VERSION ""

NS_ :

BS_:
BU_: GW BMS GPEU PCU RPEU PDU EMS TMS RPEU OBC GPEU PDU ReservedID19 ReservedID20 BDC  TMS Tester
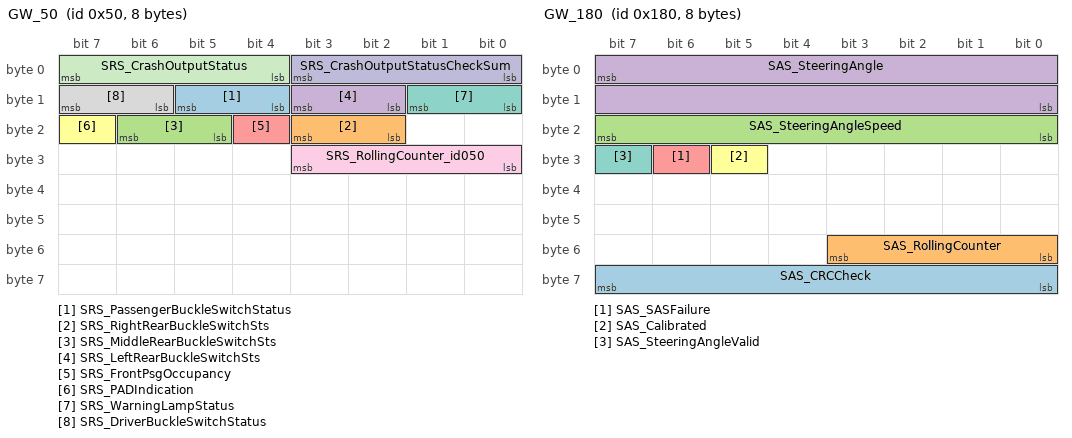
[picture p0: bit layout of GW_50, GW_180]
BO_ 80 GW_50: 8 GW
 SG_ SRS_PassengerBuckleSwitchStatus : 13|2@0+ (1.0000000000,0.0000000000) [0.0000000000|3.0000000000] "" Vector__XXX
 SG_ SRS_RightRearBuckleSwitchSts : 19|2@0+ (1.0000000000,0.0000000000) [0.0000000000|3.0000000000] "" Vector__XXX
 SG_ SRS_MiddleRearBuckleSwitchSts : 22|2@0+ (1.0000000000,0.0000000000) [0.0000000000|3.0000000000] "" Vector__XXX
 SG_ SRS_LeftRearBuckleSwitchSts : 11|2@0+ (1.0000000000,0.0000000000) [0.0000000000|3.0000000000] "" Vector__XXX
 SG_ SRS_FrontPsgOccupancy : 20|1@0+ (1.0000000000,0.0000000000) [0.0000000000|1.0000000000] "" Vector__XXX
 SG_ SRS_PADIndication : 23|1@0+ (1.0000000000,0.0000000000) [0.0000000000|1.0000000000] "" Vector__XXX
 SG_ SRS_WarningLampStatus : 9|2@0+ (1.0000000000,0.0000000000) [0.0000000000|3.0000000000] "" Vector__XXX
 SG_ SRS_DriverBuckleSwitchStatus : 15|2@0+ (1.0000000000,0.0000000000) [0.0000000000|3.0000000000] ""  EMS,PCU,PDCU
 SG_ SRS_RollingCounter_id050 : 27|4@0+ (1.0000000000,0.0000000000) [0.0000000000|15.0000000000] ""  BMS,EMS,PCU,PDCU
 SG_ SRS_CrashOutputStatusCheckSum : 3|4@0+ (1.0000000000,0.0000000000) [0.0000000000|15.0000000000] ""  BMS,EMS,PCU,PDCU
 SG_ SRS_CrashOutputStatus : 7|4@0+ (1.0000000000,0.0000000000) [0.0000000000|15.0000000000] ""  BMS,EMS,PCU,PDCU

BO_ 384 GW_180: 8 GW
 SG_ SAS_CRCCheck : 63|8@0+ (1.0000000000,0.0000000000) [0.0000000000|255.0000000000] ""  PCU,PDCU
 SG_ SAS_RollingCounter : 51|4@0+ (1.0000000000,0.0000000000) [0.0000000000|15.0000000000] ""  PCU,PDCU
 SG_ SAS_SteeringAngleSpeed : 23|8@0+ (4.0000000000,0.0000000000) [0.0000000000|1016.0000000000] "deg/s"  EMS,PCU,PDCU
 SG_ SAS_SteeringAngle : 7|16@0- (0.1000000000,0.0000000000) [-780.0000000000|780.0000000000] "degree"  EMS,PCU,PDCU
 SG_ SAS_SASFailure : 30|1@0+ (1.0000000000,0.0000000000) [0.0000000000|1.0000000000] "" Vector__XXX
 SG_ SAS_Calibrated : 29|1@0+ (1.0000000000,0.0000000000) [0.0000000000|1.0000000000] "" Vector__XXX
 SG_ SAS_SteeringAngleValid : 31|1@0+ (1.0000000000,0.0000000000) [0.0000000000|1.0000000000] ""  EMS,PCU,PDCU

BO_ 400 BMS_190: 32 BMS
 SG_ BMS_PlsHeatTiRem : 203|11@0+ (1.0000000000,0.0000000000) [0.0000000000|2047.0000000000] "second"  GW
 SG_ BMS_BattPlsHeagStsFb : 208|3@0+ (1.0000000000,0.0000000000) [0.0000000000|7.0000000000] ""  GW
 SG_ BMS_MaxChrgU : 221|9@0+ (1.0000000000,0.0000000000) [0.0000000000|500.0000000000] "V"  GW,RPEU
 SG_ BMS_MinDchaIU : 228|9@0+ (1.0000000000,0.0000000000) [0.0000000000|500.0000000000] "V"  GW,RPEU
 SG_ BMS_BcuCycWakeupTimer : 82|11@0+ (1.0000000000,0.0000000000) [0.0000000000|2047.0000000000] "min"  GW
 SG_ BMS_BcuDataUploadReq : 83|1@0+ (1.0000000000,0.0000000000) [0.0000000000|1.0000000000] ""  GW
 SG_ BMS_BattInrHeatMode : 87|4@0+ (1.0000000000,0.0000000000) [0.0000000000|15.0000000000] "min"  GW,TMS,BDC
 SG_ BMS_BattPlsHeatgGearReq : 199|2@0+ (1.0000000000,0.0000000000) [0.0000000000|3.0000000000] ""  PCU,PDCU,GW,RPEU
 SG_ BMS_RollingCounter_190 : 235|4@0+ (1.0000000000,0.0000000000) [0.0000000000|15.0000000000] ""  GW,DPEU,PCU,PDCU,OBC,PDU
 SG_ BMS_CRCCheck_190 : 247|16@0+ (1.0000000000,0.0000000000) [0.0000000000|65535.0000000000] ""  GW,DPEU,PCU,PDCU,OBC,PDU
 SG_ BMS_RlyWlddErr : 180|1@0+ (1.0000000000,0.0000000000) [0.0000000000|1.0000000000] ""  PDCU,PCU,GW
 SG_ BMS_MaxDchaPwrShoT : 135|10@0+ (0.5000000000,0.0000000000) [0.0000000000|500.0000000000] "Kw"  PDCU,PCU,GW,DPEU
 SG_ BMS_MaxDchaIShoT : 147|10@0+ (1.0000000000,0.0000000000) [0.0000000000|1000.0000000000] "A"  PDCU,PCU,GW,DPEU
 SG_ BMS_MaxChrgPwrShoT : 141|10@0+ (0.5000000000,0.0000000000) [0.0000000000|500.0000000000] "Kw"  PDCU,PCU,GW,DPEU
 SG_ BMS_MaxChrgIShoT : 153|10@0+ (1.0000000000,0.0000000000) [0.0000000000|1000.0000000000] "A"  PDCU,PCU,GW,DPEU
 SG_ BMS_BattUSwitch : 175|9@0+ (1.0000000000,0.0000000000) [0.0000000000|500.0000000000] "V"  PDCU,PCU,GW
 SG_ BMS_BattUCmdLoc : 182|2@0+ (1.0000000000,0.0000000000) [0.0000000000|3.0000000000] ""  PDCU,PCU,GW
 SG_ BMS_BcuSngPackModSts : 71|1@0+ (1.0000000000,0.0000000000) [0.0000000000|1.0000000000] ""  PDCU,PCU,GW
 SG_ BMS_SOC : 28|10@0+ (0.1000000000,0.0000000000) [0.0000000000|100.0000000000] "%"  PDCU,PCU,GW,TMS,BDC
 SG_ BMS_PwrUpAllw : 42|1@0+ (1.0000000000,0.0000000000) [0.0000000000|1.0000000000] ""  PDCU,PCU,GW
 SG_ BMS_OperMod : 47|3@0+ (1.0000000000,0.0000000000) [0.0000000000|7.0000000000] ""  PDCU,PCU,GW,DPEU
 SG_ BMS_OBCOperModReq : 44|2@0+ (1.0000000000,0.0000000000) [0.0000000000|3.0000000000] ""  PDCU,PCU,GW,OBC,PDU
 SG_ BMS_InsulationSts : 33|2@0+ (1.0000000000,0.0000000000) [0.0000000000|3.0000000000] ""  PDCU,PCU,GW
 SG_ BMS_HVILSts : 41|1@0+ (1.0000000000,0.0000000000) [0.0000000000|1.0000000000] ""  PDCU,PCU,GW
 SG_ BMS_HeatSftySts : 34|1@0+ (1.0000000000,0.0000000000) [0.0000000000|1.0000000000] ""  PDCU,PCU,GW,TMS,BDC
 SG_ BMS_FltRnk : 55|4@0+ (1.0000000000,0.0000000000) [0.0000000000|8.0000000000] ""  PDCU,PCU,GW
 SG_ BMS_CrashSts : 40|1@0+ (1.0000000000,0.0000000000) [0.0000000000|1.0000000000] ""  PDCU,PCU,GW
 SG_ BMS_BattU : 7|13@0+ (0.1000000000,0.0000000000) [0.0000000000|500.0000000000] "V"  PDCU,PCU,DPEU,GPEU,RPEU,GW
 SG_ BMS_BattI : 10|14@0+ (0.1000000000,-600.0000000000) [-600.0000000000|1000.0000000000] "A"  PDCU,PCU,DPEU,GPEU,RPEU,GW,TMS,BDC

BO_ 308 GPEU_134: 64 GPEU
 SG_ GM_MotorStart : 239|1@0+ (1.0000000000,0.0000000000) [0.0000000000|1.0000000000] ""  GPEU,GW
 SG_ GM_KeyOn : 238|1@0+ (1.0000000000,0.0000000000) [0.0000000000|1.0000000000] ""  GPEU,GW
 SG_ GM_ReolverSingalVp : 423|8@0+ (0.0200000000,0.0000000000) [0.0000000000|5.1000000000] ""  DPEU,GPEU,GW
 SG_ GM_IqFeedBack : 415|8@0+ (0.0200000000,-2.4000000000) [-2.4000000000|2.4000000000] ""  DPEU,GPEU,GW
 SG_ GM_IdFeedBack : 407|8@0+ (0.0200000000,-2.4000000000) [-2.4000000000|2.4000000000] ""  DPEU,GPEU,GW
 SG_ GM_IqCmd : 399|8@0+ (0.0200000000,-2.4000000000) [-2.4000000000|2.4000000000] ""  DPEU,GPEU,GW
 SG_ GM_IdCmd : 391|8@0+ (0.0200000000,-2.4000000000) [-2.4000000000|2.4000000000] ""  DPEU,GPEU,GW
 SG_ GM_IvtINTCT : 167|8@0+ (1.0000000000,-40.0000000000) [-40.0000000000|213.0000000000] "DegreeC"  DPEU,GPEU,PCU,PDCU,GW,TMS,BDC
 SG_ GM_IvtwaterReq : 263|8@0+ (0.1000000000,0.0000000000) [0.0000000000|20.0000000000] "L/min"  DPEU,GPEU,GW,TMS,BDC
 SG_ GM_MidSide_DCUUAct : 463|10@0+ (1.0000000000,0.0000000000) [0.0000000000|1000.0000000000] "V"  DPEU,GPEU,PCU,PDCU,GW
 SG_ GM_MotSpdVld : 72|1@0+ (1.0000000000,0.0000000000) [0.0000000000|1.0000000000] ""  DPEU,GPEU,PCU,PDCU,GW,TMS,BDC
 SG_ GM_MotSpd : 71|15@0+ (1.0000000000,-12000.0000000000) [-12000.0000000000|12000.0000000000] "1/min"  DPEU,GPEU,PCU,PDCU,GW,TMS,BDC
 SG_ GM_TorsionalVibrationTqVld : 17|1@0+ (1.0000000000,0.0000000000) [0.0000000000|1.0000000000] ""  DPEU,GPEU,PCU,PDCU,GW
 SG_ GM_TorsionalVibrationTq : 9|8@0+ (1.0000000000,-128.0000000000) [-128.0000000000|127.0000000000] "Nm"  DPEU,GPEU,PCU,PDCU,GW
 SG_ GM_MotTqRealVld : 10|1@0+ (1.0000000000,0.0000000000) [0.0000000000|1.0000000000] ""  DPEU,GPEU,PCU,PDCU,GW,EMS
 SG_ GM_MotTqReal : 7|13@0+ (0.1000000000,-400.0000000000) [-400.0000000000|400.0000000000] "Nm"  DPEU,GPEU,PCU,PDCU,GW,EMS
 SG_ GM_IvtTOver : 293|1@0+ (1.0000000000,0.0000000000) [0.0000000000|1.0000000000] ""  DPEU,GPEU,GW,TMS,BDC
 SG_ GM_OperMdl : 281|4@0+ (1.0000000000,0.0000000000) [0.0000000000|15.0000000000] ""  DPEU,GPEU,PCU,PDCU,GW,TMS,BDC
 SG_ GM_MotTOver : 282|1@0+ (1.0000000000,0.0000000000) [0.0000000000|1.0000000000] ""  DPEU,GPEU,GW,TMS,BDC
 SG_ GM_IvtCooltT : 274|8@0+ (1.0000000000,-40.0000000000) [-40.0000000000|213.0000000000] "DegreeC"  DPEU,GPEU,PCU,PDCU,GW,TMS,BDC
 SG_ GM_MotSts : 153|2@0+ (1.0000000000,0.0000000000) [0.0000000000|3.0000000000] ""  DPEU,GPEU,GW,TMS,BDC
 SG_ GM_MotNr : 155|2@0+ (1.0000000000,0.0000000000) [0.0000000000|3.0000000000] ""  DPEU,GPEU,GW
 SG_ GM_ErrAmnt : 159|4@0+ (1.0000000000,0.0000000000) [0.0000000000|15.0000000000] ""  DPEU,GPEU,GW
 SG_ GM_BattSide_DCUIAct : 205|10@0+ (1.0000000000,-500.0000000000) [-500.0000000000|500.0000000000] "A"  DPEU,GPEU,PCU,PDCU,GW
 SG_ GM_MotwaterReq : 300|8@0+ (0.1000000000,0.0000000000) [0.0000000000|20.0000000000] "L/min"  DPEU,GPEU,GW,TMS,BDC
 SG_ GM_MotOilReq : 292|8@0+ (0.1000000000,0.0000000000) [0.0000000000|20.0000000000] "L/min"  DPEU,GPEU,PCU,PDCU,GW,TMS,BDC
 SG_ GM_FltCode : 237|9@0+ (1.0000000000,0.0000000000) [0.0000000000|500.0000000000] ""  DPEU,GPEU,PCU,PDCU,GW
 SG_ GM_ACIAct : 199|10@0+ (1.0000000000,-400.0000000000) [-400.0000000000|400.0000000000] "Arms"  DPEU,GPEU,GW
 SG_ GM_MotStatorT : 151|8@0+ (1.0000000000,-40.0000000000) [-40.0000000000|213.0000000000] "DegreeC"  DPEU,GPEU,PCU,PDCU,GW,TMS,BDC
 SG_ GM_MotRotorT : 143|8@0+ (1.0000000000,-40.0000000000) [-40.0000000000|213.0000000000] "DegreeC"  DPEU,GPEU,PCU,PDCU,GW,TMS,BDC
 SG_ GM_IvtIGBTMdlT : 135|8@0+ (1.0000000000,-40.0000000000) [-40.0000000000|213.0000000000] "DegreeC"  DPEU,GPEU,PCU,PDCU,GW,TMS,BDC
 SG_ DPEU_RollingCounter_134 : 491|4@0+ (1.0000000000,0.0000000000) [0.0000000000|15.0000000000] ""  DPEU,PCU,PDCU,GW,GPEU,EMS
 SG_ DPEU_CRCCheck_134 : 503|16@0+ (1.0000000000,0.0000000000) [0.0000000000|65535.0000000000] ""  DPEU,PCU,PDCU,GW,GPEU,EMS
 SG_ GM_Resolvercalibrstatus : 327|3@0+ (1.0000000000,0.0000000000) [0.0000000000|7.0000000000] ""  DPEU,GPEU,PCU,PDCU,GW
 SG_ GM_OffsAg : 219|12@0+ (0.0878906250,-180.0000000000) [-180.0000000000|180.0000000000] ""  DPEU,GPEU,PCU,PDCU,GW
 SG_ GM_MinTqShortTerm : 356|9@0+ (1.0000000000,-500.0000000000) [-500.0000000000|0.0000000000] "Nm"  DPEU,GPEU,PCU,PDCU
 SG_ GM_MinTqLongTerm : 349|9@0+ (1.0000000000,-500.0000000000) [-500.0000000000|0.0000000000] "Nm"  DPEU,GPEU,PCU,PDCU
 SG_ GM_MaxTqShortTerm : 342|9@0+ (1.0000000000,0.0000000000) [0.0000000000|500.0000000000] "Nm"  DPEU,GPEU,PCU,PDCU
 SG_ GM_MaxTqLongTerm : 335|9@0+ (1.0000000000,0.0000000000) [0.0000000000|500.0000000000] "Nm"  DPEU,GPEU,PCU,PDCU
 SG_ GM_FltRnk : 322|3@0+ (1.0000000000,0.0000000000) [0.0000000000|4.0000000000] ""  DPEU,GPEU,PCU,PDCU,GW
 SG_ GM_ASCflag : 244|1@0+ (1.0000000000,0.0000000000) [0.0000000000|1.0000000000] ""  DPEU,GPEU,PCU,PDCU,GW
 SG_ GM_MidSide_DCUIAct : 469|10@0+ (1.0000000000,-500.0000000000) [-500.0000000000|500.0000000000] "A"  DPEU,GPEU,GW

BO_ 510 PCU_1FE: 32 PCU
 SG_ PCU_CRCCheck_1FE_2 : 191|8@0+ (1.0000000000,0.0000000000) [0.0000000000|255.0000000000] ""  DPEU,GPEU,PCU,PDCU
 SG_ PCU_RollingCounter_1FE_2 : 179|4@0+ (1.0000000000,0.0000000000) [0.0000000000|15.0000000000] ""  DPEU,GPEU,PCU,PDCU
 SG_ PCU_CRCCheck_1FE_1 : 127|8@0+ (1.0000000000,0.0000000000) [0.0000000000|255.0000000000] ""  PCU,PDCU,DPEU,GPEU
 SG_ PCU_RollingCounter_1FE_1 : 115|4@0+ (1.0000000000,0.0000000000) [0.0000000000|15.0000000000] ""  PCU,PDCU,DPEU,GPEU
 SG_ PCU_CRCCheck_1FE_0 : 63|8@0+ (1.0000000000,0.0000000000) [0.0000000000|255.0000000000] ""  PCU,PDCU,DPEU,GPEU
 SG_ PCU_RollingCounter_1FE_0 : 51|4@0+ (1.0000000000,0.0000000000) [0.0000000000|15.0000000000] ""  PCU,PDCU,DPEU,GPEU
 SG_ PCU_GMCurrentCmd : 19|11@0+ (0.1000000000,-100.0000000000) [-100.0000000000|100.0000000000] "A"  PCU,PDCU,DPEU,GPEU
 SG_ PCU_GMTqRgnIMax : 13|10@0+ (1.0000000000,-500.0000000000) [-500.0000000000|500.0000000000] "A"  PCU,PDCU,DPEU,GPEU
 SG_ PCU_GMTqImax : 7|10@0+ (1.0000000000,-500.0000000000) [-500.0000000000|500.0000000000] "A"  PCU,PDCU,DPEU,GPEU
 SG_ PCU_RollingCounter_1FE : 235|4@0+ (1.0000000000,0.0000000000) [0.0000000000|15.0000000000] ""  DPEU,PCU,PDCU,GPEU
 SG_ PCU_CRCCheck_1FE : 247|16@0+ (1.0000000000,0.0000000000) [0.0000000000|65535.0000000000] ""  DPEU,PCU,PDCU,GPEU
 SG_ PCU_GM_TqNegMax : 146|10@0+ (1.0000000000,-512.0000000000) [-512.0000000000|511.0000000000] "Nm"  DPEU,GPEU,PCU,PDCU
 SG_ PCU_GM_RateTqMax : 138|8@0+ (100.0000000000,-10000.0000000000) [-10000.0000000000|10000.0000000000] "Nm/s"  DPEU,GPEU,PCU,PDCU
 SG_ PCU_GM_RateSpdMax : 131|9@0+ (100.0000000000,-20000.0000000000) [-20000.0000000000|20000.0000000000] "rpm/s"  DPEU,GPEU,PCU,PDCU
 SG_ PCU_GM_MotModReq : 135|4@0+ (1.0000000000,0.0000000000) [0.0000000000|15.0000000000] ""  DPEU,GPEU,PCU,PDCU
 SG_ PCU_GM_TqPosMax : 46|10@0+ (1.0000000000,-512.0000000000) [-512.0000000000|511.0000000000] "Nm"  DPEU,GPEU,PCU,PDCU
 SG_ PCU_GM_SurgeDamperTqMin : 24|10@0+ (1.0000000000,-500.0000000000) [-500.0000000000|500.0000000000] "Nm"  PCU,PDCU,DPEU,GPEU
 SG_ PCU_GM_SurgeDamperTqMax : 101|10@0+ (1.0000000000,-500.0000000000) [-500.0000000000|500.0000000000] "Nm"  PCU,PDCU,DPEU,GPEU
 SG_ PCU_GM_SurgeDamperEna : 102|1@0+ (1.0000000000,0.0000000000) [0.0000000000|1.0000000000] ""  PCU,PDCU,DPEU,GPEU
 SG_ PCU_GM_ResoCaliAllow : 88|2@0+ (1.0000000000,0.0000000000) [0.0000000000|3.0000000000] ""  PCU,PDCU,DPEU,GPEU
 SG_ PCU_GM_nCtlExtCfg : 91|3@0+ (1.0000000000,0.0000000000) [0.0000000000|5.0000000000] ""  PCU,PDCU,DPEU,GPEU
 SG_ PCU_GM_MotTqReq : 72|13@0+ (0.1000000000,-400.0000000000) [-400.0000000000|400.0000000000] "Nm"  PCU,PDCU,DPEU,GPEU
 SG_ PCU_GM_MotSpdReq : 71|15@0+ (1.0000000000,-12000.0000000000) [-12000.0000000000|12000.0000000000] "1/Min"  PCU,PDCU,DPEU,GPEU

BO_ 1467 RPEU_5BB: 64 RPEU
 SG_ TM1_ReMotActHeaPwr : 439|8@0+ (1.0000000000,0.0000000000) [0.0000000000|255.0000000000] "kW"  RPEU,GW,TMS,BDC,PCU,PDCU
 SG_ TM1_ReMotWasHeaPwr : 431|8@0+ (1.0000000000,0.0000000000) [0.0000000000|255.0000000000] "kW"  RPEU,GW,TMS,BDC,PCU,PDCU
 SG_ TM1_ReIPUIqCmd : 481|11@0+ (1.0000000000,-1000.0000000000) [-1000.0000000000|1047.0000000000] "A"  RPEU,GW
 SG_ TM1_ReIPUIdCmd : 476|11@0+ (1.0000000000,-1000.0000000000) [-1000.0000000000|1047.0000000000] "A"  RPEU,GW
 SG_ TM1_ReMotIStatr : 471|11@0+ (1.0000000000,-1000.0000000000) [-1000.0000000000|1047.0000000000] "A"  RPEU,GW
 SG_ TM1_VcuIpuErrLamp : 456|1@0+ (1.0000000000,0.0000000000) [0.0000000000|1.0000000000] ""  RPEU,GW
 SG_ TM1_ReMotReducerRatio : 455|15@0+ (0.0010000000,0.0000000000) [0.0000000000|20.0000000000] ""  RPEU,GW
 SG_ TM1_RmipuReWhlActTq : 415|16@0+ (1.0000000000,-32768.0000000000) [-32768.0000000000|32767.0000000000] ""  RPEU,GW
 SG_ TM1_ReIpuTIgbtPhaW : 407|8@0+ (1.0000000000,-50.0000000000) [-50.0000000000|205.0000000000] "��"  RPEU,GW
 SG_ TM1_ReIpuTIgbtPhaV : 399|8@0+ (1.0000000000,-50.0000000000) [-50.0000000000|205.0000000000] "��"  RPEU,GW
 SG_ TM1_ReIpuTIgbtPhaU : 391|8@0+ (1.0000000000,-50.0000000000) [-50.0000000000|205.0000000000] "��"  RPEU,GW
 SG_ TM1_ReIpuStsDrtgTqMin : 364|6@0+ (1.0000000000,0.0000000000) [0.0000000000|63.0000000000] ""  RPEU,GW
 SG_ TM1_ReIpuStsDrtgTqMax : 354|6@0+ (1.0000000000,0.0000000000) [0.0000000000|63.0000000000] ""  RPEU,GW
 SG_ TM1_ReIpuCooltFlowRateEst : 339|4@0+ (1.0000000000,0.0000000000) [0.0000000000|15.0000000000] ""  RPEU,GW
 SG_ TM1_ReIpuCoolgTEst : 327|8@0+ (1.0000000000,-50.0000000000) [-50.0000000000|205.0000000000] "��"  RPEU,GW
 SG_ TM1_RmipuTqLimFlgWithInpU : 340|1@0+ (1.0000000000,0.0000000000) [0.0000000000|1.0000000000] ""  RPEU,GW
 SG_ TM1_ReIPUUqCmd : 335|11@0+ (1.0000000000,-1000.0000000000) [-1000.0000000000|1047.0000000000] "V"  RPEU,GW
 SG_ TM1_ReMotTqGb : 287|16@0+ (0.1000000000,-2000.0000000000) [-2000.0000000000|4553.5000000000] "Nm"  RPEU,GW
 SG_ TM1_ReMotRateTq : 303|10@0+ (10.0000000000,0.0000000000) [0.0000000000|10230.0000000000] "Nm/S"  RPEU,GW
 SG_ TM1_ReIPUIGBTSwitchFreq : 279|8@0+ (0.1000000000,0.0000000000) [0.0000000000|25.5000000000] "kHz"  RPEU,GW
 SG_ TM1_ReIpuIqPIOut : 271|8@0+ (1.0000000000,-100.0000000000) [-100.0000000000|155.0000000000] "A"  RPEU,GW
 SG_ TM1_ReIpuT : 263|8@0+ (1.0000000000,-40.0000000000) [-40.0000000000|215.0000000000] "��"  RPEU,GW
 SG_ TM1_MotSts : 33|2@0+ (1.0000000000,0.0000000000) [0.0000000000|3.0000000000] ""  DPEU,RPEU,GW,TMS,BDC
 SG_ TM1_MotNr : 35|2@0+ (1.0000000000,0.0000000000) [0.0000000000|3.0000000000] ""  DPEU,RPEU,GW
 SG_ TM1_ErrAmnt : 39|4@0+ (1.0000000000,0.0000000000) [0.0000000000|15.0000000000] ""  DPEU,RPEU,GW

BO_ 811 PDU_32B: 32 PDU
 SG_ OBC_RollingCounter_32B : 235|4@0+ (1.0000000000,0.0000000000) [0.0000000000|15.0000000000] ""  GW,OBC,PCU,PDCU
 SG_ OBC_CRCCheck_32B : 247|16@0+ (1.0000000000,0.0000000000) [0.0000000000|65535.0000000000] ""  GW,OBC,PCU,PDCU
 SG_ DCDC_ResetSts : 74|3@0+ (1.0000000000,0.0000000000) [0.0000000000|7.0000000000] ""  GW,DPEU,OBC,PDU
 SG_ DCDCAvlOutpPwr : 95|12@0+ (1.0000000000,0.0000000000) [0.0000000000|3500.0000000000] ""  DPEU,OBC,PDU,PCU,PDCU,GW,DCDC
 SG_ DCDC_Sts : 77|2@0+ (1.0000000000,0.0000000000) [0.0000000000|3.0000000000] ""  DPEU,OBC,GW,DCDC
 SG_ DCDC_RollingCounter_31D : 115|4@0+ (1.0000000000,0.0000000000) [0.0000000000|15.0000000000] ""  DPEU,OBC,PDU,PCU,PDCU,GW,DCDC
 SG_ DCDC_PCBT : 87|8@0+ (1.0000000000,-40.0000000000) [-40.0000000000|213.0000000000] "DegreeC"  DPEU,OBC,PDU,PCU,PDCU,GW,DCDC,TMS,BDC
 SG_ DCDC_OverT : 75|1@0+ (1.0000000000,0.0000000000) [0.0000000000|1.0000000000] ""  DPEU,OBC,PDU,GW,DCDC,TMS,BDC,IBCMR
 SG_ DCDC_FltRnk : 79|2@0+ (1.0000000000,0.0000000000) [0.0000000000|3.0000000000] ""  DPEU,OBC,PDU,DCDC,PCU,PDCU,GW
 SG_ DCDC_FltCode : 71|8@0+ (1.0000000000,0.0000000000) [0.0000000000|255.0000000000] ""  DPEU,OBC,PDU,PCU,PDCU,GW
 SG_ DCDC_CRCCheck_31D : 127|8@0+ (1.0000000000,0.0000000000) [0.0000000000|255.0000000000] ""  DPEU,OBC,PDU,PCU,PDCU,GW
 SG_ DCDC_Utlzt : 26|9@0+ (0.2500000000,0.0000000000) [0.0000000000|127.2500000000] "%"  DPEU,OBC,PCU,PDCU,GW
 SG_ DCDC_ULV : 14|8@0+ (0.1250000000,0.0000000000) [0.0000000000|25.0000000000] ""  DPEU,OBC,PDU,PCU,PDCU,GW
 SG_ DCDC_UHV : 7|9@0+ (1.0000000000,0.0000000000) [0.0000000000|500.0000000000] "V"  DPEU,OBC,PDU,PCU,PDCU,GW
 SG_ DCDC_RollingCounter_2E4 : 51|4@0+ (1.0000000000,0.0000000000) [0.0000000000|15.0000000000] ""  DPEU,OBC,PDU,DCDC,PCU,PDCU,GW
 SG_ DCDC_CRCCheck_2E4 : 63|8@0+ (1.0000000000,0.0000000000) [0.0000000000|255.0000000000] ""  DPEU,OBC,PDU,DCDC,PCU,PDCU,GW
 SG_ DCDC_StsWarning : 53|2@0+ (1.0000000000,0.0000000000) [0.0000000000|3.0000000000] ""  DPEU,OBC,PDU,PCU,PDCU,GW
 SG_ DCDC_OperMod : 29|3@0+ (1.0000000000,0.0000000000) [0.0000000000|7.0000000000] ""  DPEU,OBC,PDU,PCU,PDCU,GW,TMS,BDC
 SG_ DCDC_ILV : 22|9@0+ (1.0000000000,0.0000000000) [0.0000000000|500.0000000000] "A"  DPEU,OBC,PDU,PCU,PDCU,GW
 SG_ DCDC_IHV : 32|9@0+ (0.0625000000,0.0000000000) [0.0000000000|25.0000000000] "A"  DPEU,OBC,PDU,PCU,PDCU,GW

BO_ 276 PCU_114: 32 PCU
 SG_ TCU_ShiftPostionValid1 : 107|1@0+ (1.0000000000,0.0000000000) [0.0000000000|1.0000000000] ""  PCU,PDCU,GW,RPEU
 SG_ TCU_GearShiftPosition1 : 111|4@0+ (1.0000000000,0.0000000000) [0.0000000000|15.0000000000] ""  PCU,PDCU,GW,RPEU
 SG_ PCU_TM1DynTqUnloadAllwd : 53|1@0+ (1.0000000000,0.0000000000) [0.0000000000|1.0000000000] ""  PCU,PDCU,GW,RPEU
 SG_ PCU_CRCCheck_114 : 247|16@0+ (1.0000000000,0.0000000000) [0.0000000000|65535.0000000000] ""  PCU,PDCU,GW,DPEU,RPEU
 SG_ PCU_RollingCounter_114 : 235|4@0+ (1.0000000000,0.0000000000) [0.0000000000|15.0000000000] ""  PCU,PDCU,GW,DPEU,RPEU
 SG_ PCU_CRCCheck_114_2 : 191|8@0+ (1.0000000000,0.0000000000) [0.0000000000|255.0000000000] ""  PCU,PDCU,GW,DPEU,RPEU
 SG_ PCU_RollingCounter_114_2 : 179|4@0+ (1.0000000000,0.0000000000) [0.0000000000|15.0000000000] ""  PCU,PDCU,GW,DPEU,RPEU
 SG_ PCU_CRCCheck_114_1 : 127|8@0+ (1.0000000000,0.0000000000) [0.0000000000|255.0000000000] ""  PCU,PDCU,GW,DPEU,RPEU
 SG_ PCU_RollingCounter_114_1 : 115|4@0+ (1.0000000000,0.0000000000) [0.0000000000|15.0000000000] ""  PCU,PDCU,GW,DPEU,RPEU
 SG_ PCU_TM1CurrentCmd : 147|11@0+ (0.1000000000,-100.0000000000) [-100.0000000000|100.0000000000] "A"  PCU,PDCU,GW,DPEU,RPEU
 SG_ PCU_TM1TqRgnIMax : 141|10@0+ (1.0000000000,-500.0000000000) [-500.0000000000|500.0000000000] "A"  PCU,PDCU,GW,DPEU,RPEU
 SG_ PCU_TM1TqImax : 135|10@0+ (1.0000000000,-500.0000000000) [-500.0000000000|500.0000000000] "A"  PCU,PDCU,GW,DPEU,RPEU
 SG_ PCU_TM1_SurgeDamperTqMin : 13|10@0+ (1.0000000000,-500.0000000000) [-500.0000000000|500.0000000000] "Nm"  PCU,PDCU,GW,DPEU,RPEU
 SG_ PCU_TM1_SurgeDamperTqMax : 7|10@0+ (1.0000000000,-500.0000000000) [-500.0000000000|500.0000000000] "Nm"  PCU,PDCU,GW,DPEU,RPEU
 SG_ PCU_TM1_MotTqPosMax : 19|10@0+ (1.0000000000,-500.0000000000) [-500.0000000000|500.0000000000] "Nm"  PCU,PDCU,GW,DPEU,RPEU
 SG_ PCU_TM1_MotTqNegMax : 25|10@0+ (1.0000000000,-500.0000000000) [-500.0000000000|500.0000000000] "Nm"  PCU,PDCU,GW,DPEU,RPEU
 SG_ PCU_TM1_MotRateTqMax : 47|10@0+ (10.0000000000,0.0000000000) [0.0000000000|10000.0000000000] "Nm/S"  PCU,PDCU,GW,DPEU,RPEU
 SG_ PCU_CRCCheck_114_0 : 63|8@0+ (1.0000000000,0.0000000000) [0.0000000000|255.0000000000] ""  PCU,PDCU,GW,DPEU,RPEU
 SG_ PCU_RollingCounter_114_0 : 51|4@0+ (1.0000000000,0.0000000000) [0.0000000000|15.0000000000] ""  PCU,PDCU,GW,DPEU,RPEU
 SG_ PCU_TM1_SurgeDamperEna : 96|1@0+ (1.0000000000,0.0000000000) [0.0000000000|1.0000000000] ""  PCU,PDCU,GW,DPEU,RPEU
 SG_ PCU_TM1_ResoCaliAllow : 98|2@0+ (1.0000000000,0.0000000000) [0.0000000000|3.0000000000] ""  PCU,PDCU,GW,DPEU,RPEU
 SG_ PCU_TM1_nCtlExtCfg : 101|3@0+ (1.0000000000,0.0000000000) [0.0000000000|5.0000000000] ""  PCU,PDCU,GW,DPEU,RPEU
 SG_ PCU_TM1_MotTqReq : 83|14@0+ (0.1000000000,-800.0000000000) [-800.0000000000|800.0000000000] "Nm"  PCU,PDCU,GW,DPEU,RPEU
 SG_ PCU_TM1_MotSpdReq : 71|16@0+ (1.0000000000,-25000.0000000000) [-25000.0000000000|25000.0000000000] "1/Min"  PCU,PDCU,GW,DPEU,RPEU
 SG_ PCU_TM1_MotModReq : 87|4@0+ (1.0000000000,0.0000000000) [0.0000000000|15.0000000000] ""  PCU,PDCU,GW,DPEU,RPEU

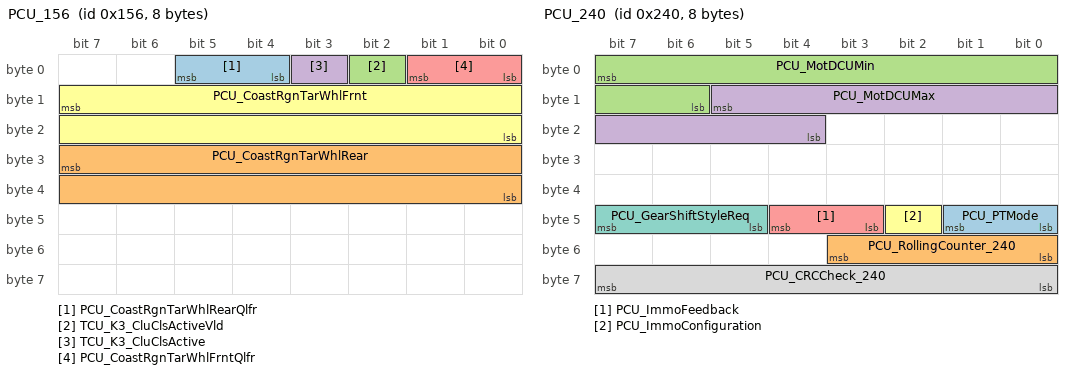
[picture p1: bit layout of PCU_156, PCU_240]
BO_ 342 PCU_156: 8 PCU
 SG_ PCU_CoastRgnTarWhlRearQlfr : 5|2@0+ (1.0000000000,0.0000000000) [0.0000000000|2.0000000000] ""  PCU,PDCU,GW
 SG_ PCU_CoastRgnTarWhlRear : 31|16@0+ (1.0000000000,-32768.0000000000) [-32768.0000000000|32767.0000000000] "Nm"  PCU,PDCU,GW
 SG_ TCU_K3_CluClsActiveVld : 2|1@0+ (1.0000000000,0.0000000000) [0.0000000000|1.0000000000] ""  PCU,PDCU,GW
 SG_ TCU_K3_CluClsActive : 3|1@0+ (1.0000000000,0.0000000000) [0.0000000000|1.0000000000] ""  PCU,PDCU,GW
 SG_ PCU_CoastRgnTarWhlFrntQlfr : 1|2@0+ (1.0000000000,0.0000000000) [0.0000000000|2.0000000000] "-"  PCU,PDCU,GW
 SG_ PCU_CoastRgnTarWhlFrnt : 15|16@0+ (1.0000000000,-32768.0000000000) [-32768.0000000000|32767.0000000000] "Nm"  PCU,PDCU,GW

BO_ 576 PCU_240: 8 PCU
 SG_ PCU_PTMode : 41|2@0+ (1.0000000000,0.0000000000) [0.0000000000|3.0000000000] ""  EMS,PCU,PDCU,GW
 SG_ PCU_RollingCounter_240 : 51|4@0+ (1.0000000000,0.0000000000) [0.0000000000|15.0000000000] ""  DPEU,PCU,PDCU,GW
 SG_ PCU_MotDCUMin : 7|10@0+ (0.5000000000,0.0000000000) [0.0000000000|500.0000000000] "V"  PCU,PDCU,DPEU,GW
 SG_ PCU_MotDCUMax : 13|10@0+ (0.5000000000,0.0000000000) [0.0000000000|500.0000000000] "V"  PCU,PDCU,DPEU,GW
 SG_ PCU_ImmoFeedback : 44|2@0+ (1.0000000000,0.0000000000) [0.0000000000|3.0000000000] ""  PCU,PDCU,GW
 SG_ PCU_ImmoConfiguration : 42|1@0+ (1.0000000000,0.0000000000) [0.0000000000|1.0000000000] ""  PCU,PDCU,GW
 SG_ PCU_GearShiftStyleReq : 47|3@0+ (1.0000000000,0.0000000000) [0.0000000000|7.0000000000] ""  PCU,PDCU,GW
 SG_ PCU_CRCCheck_240 : 63|8@0+ (1.0000000000,0.0000000000) [0.0000000000|255.0000000000] ""  DPEU,PCU,PDCU,GW

BO_ 583 GW_247: 32 GW
 SG_ APA_ESP_BrakeFunctionMode : 238|3@0+ (1.0000000000,0.0000000000) [0.0000000000|7.0000000000] "" Vector__XXX
 SG_ APA_RollingCounter_236 : 179|4@0+ (1.0000000000,0.0000000000) [0.0000000000|15.0000000000] ""  PCU,PDCU
 SG_ APA_PtTrqReqValid : 151|1@0+ (1.0000000000,0.0000000000) [0.0000000000|1.0000000000] ""  PCU,PDCU
 SG_ APA_PtTorqReq : 135|16@0+ (1.0000000000,-32768.0000000000) [-32768.0000000000|32767.0000000000] "Nm"  PCU,PDCU
 SG_ APA_CRC_Checksum_236 : 191|8@0+ (1.0000000000,0.0000000000) [0.0000000000|255.0000000000] ""  PCU,PDCU
 SG_ APA_FunctionOnOffSts : 33|5@0+ (1.0000000000,0.0000000000) [0.0000000000|31.0000000000] "" Vector__XXX
 SG_ APA_CRCCheck_247 : 247|16@0+ (1.0000000000,0.0000000000) [0.0000000000|65535.0000000000] ""  EMS,PCU,PDCU
 SG_ APA_RollingCounter_247 : 235|4@0+ (1.0000000000,0.0000000000) [0.0000000000|15.0000000000] ""  EMS,PCU,PDCU
 SG_ APA_TrqHoldForTCUCl : 111|1@0+ (1.0000000000,0.0000000000) [0.0000000000|1.0000000000] "" Vector__XXX
 SG_ APA_TCUClutchCombinationReq : 110|1@0+ (1.0000000000,0.0000000000) [0.0000000000|1.0000000000] "" Vector__XXX
 SG_ APA_APAOnOff : 6|1@0+ (1.0000000000,0.0000000000) [0.0000000000|1.0000000000] ""  PCU,PDCU,EMS
 SG_ APA_CRCCheck_264 : 63|8@0+ (1.0000000000,0.0000000000) [0.0000000000|255.0000000000] "" Vector__XXX
 SG_ APA_ParkingPercentage : 42|7@0+ (1.0000000000,0.0000000000) [0.0000000000|100.0000000000] "%" Vector__XXX
 SG_ APA_RollingCounter_264 : 51|4@0+ (1.0000000000,0.0000000000) [0.0000000000|15.0000000000] "" Vector__XXX
 SG_ APA_TurnLightsCommand : 29|2@0+ (1.0000000000,0.0000000000) [0.0000000000|3.0000000000] "" Vector__XXX
 SG_ APA_ParkNotice : 39|6@0+ (1.0000000000,0.0000000000) [0.0000000000|63.0000000000] "" Vector__XXX
 SG_ APA_IncreasePressureReq : 27|1@0+ (1.0000000000,0.0000000000) [0.0000000000|1.0000000000] "" Vector__XXX
 SG_ APA_ButtonPress : 26|1@0+ (1.0000000000,0.0000000000) [0.0000000000|1.0000000000] "" Vector__XXX
 SG_ APA_RemoteOnOff : 25|2@0+ (1.0000000000,0.0000000000) [0.0000000000|3.0000000000] "" Vector__XXX
 SG_ APA_SteeringAngleReq : 15|16@0- (0.1000000000,0.0000000000) [-780.0000000000|780.0000000000] "degree" Vector__XXX
 SG_ APA_EmergenceBrake : 7|1@0+ (1.0000000000,0.0000000000) [0.0000000000|1.0000000000] "" Vector__XXX
 SG_ APA_indication : 5|3@0+ (1.0000000000,0.0000000000) [0.0000000000|7.0000000000] "" Vector__XXX
 SG_ APA_ErrorStatus : 2|1@0+ (1.0000000000,0.0000000000) [0.0000000000|1.0000000000] "" Vector__XXX
 SG_ APA_SteeringAngleReqProtection : 1|2@0+ (1.0000000000,0.0000000000) [0.0000000000|3.0000000000] "" Vector__XXX
 SG_ APA_HSAHDforbidden : 92|1@0+ (1.0000000000,0.0000000000) [0.0000000000|1.0000000000] "" Vector__XXX
 SG_ APA_CRCCheck_26C : 127|8@0+ (1.0000000000,0.0000000000) [0.0000000000|255.0000000000] ""  EMS,PCU,PDCU
 SG_ APA_RollingCounter_26C : 115|4@0+ (1.0000000000,0.0000000000) [0.0000000000|15.0000000000] "N/A"  EMS,PCU,PDCU
 SG_ APA_ESPDecompressionModel : 98|1@0+ (1.0000000000,0.0000000000) [0.0000000000|1.0000000000] "" Vector__XXX
 SG_ APA_AccPedShieldReq : 97|1@0+ (1.0000000000,0.0000000000) [0.0000000000|1.0000000000] ""  EMS,PCU,PDCU
 SG_ APA_SlotNotice : 109|4@0+ (1.0000000000,0.0000000000) [0.0000000000|15.0000000000] "" Vector__XXX
 SG_ APA_DynamicSlotWarning : 105|1@0+ (1.0000000000,0.0000000000) [0.0000000000|1.0000000000] "" Vector__XXX
 SG_ APA_PrefillReq : 104|1@0+ (1.0000000000,0.0000000000) [0.0000000000|1.0000000000] "" Vector__XXX
 SG_ APA_Activation_Status : 89|3@0+ (1.0000000000,0.0000000000) [0.0000000000|7.0000000000] "" Vector__XXX
 SG_ APA_EngTorqReq : 87|10@0+ (0.0978470000,0.0000000000) [0.0000000000|99.9996340000] "%"  EMS
 SG_ APA_EngineTrqReqEnable : 93|1@0+ (1.0000000000,0.0000000000) [0.0000000000|1.0000000000] ""  EMS,PCU,PDCU
 SG_ APA_LSCAction : 91|1@0+ (1.0000000000,0.0000000000) [0.0000000000|1.0000000000] ""  EMS,PCU,PDCU
 SG_ APA_TransPRNDShiftEnable : 90|1@0+ (1.0000000000,0.0000000000) [0.0000000000|1.0000000000] ""  PCU,PDCU
 SG_ APA_TargetAcceleration : 79|8@0+ (0.0500000000,-5.0000000000) [-5.0000000000|7.7500000000] "m/s2" Vector__XXX
 SG_ APA_TransPRNDShiftReqValid : 71|1@0+ (1.0000000000,0.0000000000) [0.0000000000|1.0000000000] ""  PCU,PDCU
 SG_ APA_TransPRNDShiftRequest : 70|3@0+ (1.0000000000,0.0000000000) [0.0000000000|7.0000000000] ""  PCU,PDCU
 SG_ APA_TargetAccelerationValid : 67|1@0+ (1.0000000000,0.0000000000) [0.0000000000|1.0000000000] "NA" Vector__XXX
 SG_ APA_EPBrequestValid : 66|1@0+ (1.0000000000,0.0000000000) [0.0000000000|1.0000000000] "" Vector__XXX
 SG_ APA_EPBrequest : 65|2@0+ (1.0000000000,0.0000000000) [0.0000000000|3.0000000000] "" Vector__XXX

BO_ 610 GW_262: 8 GW
 SG_ PEPS_RemoteStartKeyStatus : 43|2@0+ (1.0000000000,0.0000000000) [0.0000000000|3.0000000000] "" Vector__XXX
 SG_ PEPS_APA_PowerMirrorFoldFeedback : 26|2@0+ (1.0000000000,0.0000000000) [0.0000000000|3.0000000000] "" Vector__XXX
 SG_ PEPS_APARemoteParkingOff : 53|1@0+ (1.0000000000,0.0000000000) [0.0000000000|1.0000000000] "" Vector__XXX
 SG_ PEPS_KeyStandbyPositionIndicator : 54|1@0+ (1.0000000000,0.0000000000) [0.0000000000|1.0000000000] "" Vector__XXX
 SG_ PEPS_CRCCheck_262 : 63|8@0+ (1.0000000000,0.0000000000) [0.0000000000|255.0000000000] "" Vector__XXX
 SG_ PEPS_RollingCounter_262 : 51|4@0+ (1.0000000000,0.0000000000) [0.0000000000|15.0000000000] "" Vector__XXX
 SG_ PEPS_PEPSFailStatus : 55|1@0+ (1.0000000000,0.0000000000) [0.0000000000|1.0000000000] "" Vector__XXX
 SG_ PEPS_PowerDistributionFaultBit : 47|1@0+ (1.0000000000,0.0000000000) [0.0000000000|1.0000000000] ""  PCU,PDCU
 SG_ PEPS_IMMOFeedback : 45|2@0+ (1.0000000000,0.0000000000) [0.0000000000|3.0000000000] ""  PCU,PDCU
 SG_ PEPS_EngineStartupInhibitFB : 46|1@0+ (1.0000000000,0.0000000000) [0.0000000000|1.0000000000] ""  PCU,PDCU
 SG_ PEPS_RemoteStartFeedback : 31|5@0+ (1.0000000000,0.0000000000) [0.0000000000|31.0000000000] ""  PCU,PDCU
 SG_ PEPS_EngineStartupInhibitSts : 24|1@0+ (1.0000000000,0.0000000000) [0.0000000000|1.0000000000] ""  PCU,PDCU
 SG_ PEPS_PowerDistributionStatus : 23|2@0+ (1.0000000000,0.0000000000) [0.0000000000|3.0000000000] ""  PCU,PDCU
 SG_ PEPS_UnallowStartSignal_Not_PN : 19|1@0+ (1.0000000000,0.0000000000) [0.0000000000|1.0000000000] ""  PCU,PDCU
 SG_ PEPS_IMMOFailedAlarmsignal : 18|1@0+ (1.0000000000,0.0000000000) [0.0000000000|1.0000000000] ""  PCU,PDCU
 SG_ PEPS_UnallowStart_ESCL_LOCK : 21|1@0+ (1.0000000000,0.0000000000) [0.0000000000|1.0000000000] ""  PCU,PDCU
 SG_ PEPS_UnallowStart_ESCL_Error : 15|1@0+ (1.0000000000,0.0000000000) [0.0000000000|1.0000000000] ""  PCU,PDCU
 SG_ PEPS_StartIndicatorSignal : 7|1@0+ (1.0000000000,0.0000000000) [0.0000000000|1.0000000000] "" Vector__XXX
 SG_ PEPS_StartupButtonSignal : 17|2@0+ (1.0000000000,0.0000000000) [0.0000000000|3.0000000000] ""  PCU,PDCU
 SG_ PEPS_APA_CloseWinFeedback : 11|2@0+ (1.0000000000,0.0000000000) [0.0000000000|3.0000000000] "" Vector__XXX
 SG_ PEPS_RemoteControlACReq : 9|2@0+ (1.0000000000,0.0000000000) [0.0000000000|3.0000000000] "" Vector__XXX
 SG_ PEPS_RemoteAPADoneKeyOffReq : 6|2@0+ (1.0000000000,0.0000000000) [0.0000000000|3.0000000000] "" Vector__XXX
 SG_ PEPS_APA_Engine0ffFeedback : 4|2@0+ (1.0000000000,0.0000000000) [0.0000000000|3.0000000000] "" Vector__XXX
 SG_ PEPS_APA_LockFeedback : 2|2@0+ (1.0000000000,0.0000000000) [0.0000000000|3.0000000000] "" Vector__XXX
 SG_ PEPS_APARemoteParkingOn : 0|1@0+ (1.0000000000,0.0000000000) [0.0000000000|1.0000000000] "" Vector__XXX

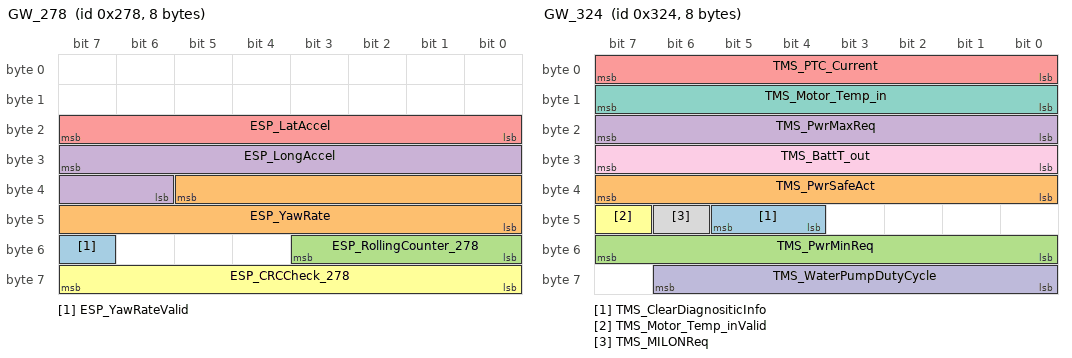
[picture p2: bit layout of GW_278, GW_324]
BO_ 632 GW_278: 8 GW
 SG_ ESP_YawRateValid : 55|1@0+ (1.0000000000,0.0000000000) [0.0000000000|1.0000000000] ""  PCU,PDCU
 SG_ ESP_YawRate : 37|14@0+ (0.0100000000,-81.9100000000) [-81.9100000000|81.9100000000] "degree/s"  PCU,PDCU
 SG_ ESP_RollingCounter_278 : 51|4@0+ (1.0000000000,0.0000000000) [0.0000000000|15.0000000000] ""  EMS,PCU,PDCU
 SG_ ESP_LongAccel : 31|10@0+ (0.0312500000,-16.0000000000) [-16.0000000000|15.9062500000] "m/s2"  EMS,PCU,PDCU
 SG_ ESP_LatAccel : 23|8@0+ (0.1000000000,-12.7000000000) [-12.7000000000|12.7000000000] "m/s2"  EMS,PCU,PDCU
 SG_ ESP_CRCCheck_278 : 63|8@0+ (1.0000000000,0.0000000000) [0.0000000000|255.0000000000] ""  EMS,PCU,PDCU

BO_ 664 GW_298: 8 GW
 SG_ BCM_TrunkUnlockReq : 29|1@0+ (1.0000000000,0.0000000000) [0.0000000000|1.0000000000] "" Vector__XXX
 SG_ PEPS_LuggageUnlockSignal : 1|2@0+ (1.0000000000,0.0000000000) [0.0000000000|3.0000000000] "" Vector__XXX
 SG_ BCM_DriverDoorLockStatus : 44|2@0+ (1.0000000000,0.0000000000) [0.0000000000|3.0000000000] ""  PCU,PDCU
 SG_ BCM_CRCCheck_298 : 63|8@0+ (1.0000000000,0.0000000000) [0.0000000000|255.0000000000] "" Vector__XXX
 SG_ BCM_RollingCounter_298 : 51|4@0+ (1.0000000000,0.0000000000) [0.0000000000|15.0000000000] "" Vector__XXX
 SG_ BCM_PassengerDoorLockStatus : 42|2@0+ (1.0000000000,0.0000000000) [0.0000000000|3.0000000000] "" Vector__XXX
 SG_ BCM_LeftRearDoorStatus : 40|1@0+ (1.0000000000,0.0000000000) [0.0000000000|1.0000000000] "" Vector__XXX
 SG_ PEPS_SmartWelcomeLightStaus : 37|2@0+ (1.0000000000,0.0000000000) [0.0000000000|3.0000000000] "" Vector__XXX
 SG_ PEPS_TrunkKeyStatus : 35|2@0+ (1.0000000000,0.0000000000) [0.0000000000|3.0000000000] "" Vector__XXX
 SG_ PEPS_UnLockKeyStatus : 33|2@0+ (1.0000000000,0.0000000000) [0.0000000000|3.0000000000] ""  PCU,PDCU
 SG_ PEPS_LockKeyStatus : 31|2@0+ (1.0000000000,0.0000000000) [0.0000000000|3.0000000000] ""  PCU,PDCU
 SG_ PEPS_SmartTrunkUlockRemind : 23|2@0+ (1.0000000000,0.0000000000) [0.0000000000|3.0000000000] "" Vector__XXX
 SG_ PEPS_UnlockSignal : 21|2@0+ (1.0000000000,0.0000000000) [0.0000000000|3.0000000000] ""  PCU,PDCU
 SG_ PEPS_LockSignal : 17|2@0+ (1.0000000000,0.0000000000) [0.0000000000|3.0000000000] ""  PCU,PDCU
 SG_ PEPS_KeyNumber : 15|3@0+ (1.0000000000,0.0000000000) [0.0000000000|6.0000000000] "" Vector__XXX
 SG_ PEPS_KeyAuthenticationStatus : 12|2@0+ (1.0000000000,0.0000000000) [0.0000000000|3.0000000000] ""  PCU,PDCU
 SG_ PEPS_Easy_open : 10|1@0+ (1.0000000000,0.0000000000) [0.0000000000|1.0000000000] "" Vector__XXX
 SG_ PEPS_Welcomelamp : 9|2@0+ (1.0000000000,0.0000000000) [0.0000000000|3.0000000000] ""  PCU,PDCU
 SG_ PEPS_TrunkRequestSignal : 7|1@0+ (1.0000000000,0.0000000000) [0.0000000000|1.0000000000] "" Vector__XXX
 SG_ PEPS_KeyLearningSignal : 6|2@0+ (1.0000000000,0.0000000000) [0.0000000000|3.0000000000] ""  PCU,PDCU
 SG_ PEPS_EasyOpenOrginalSignal : 4|1@0+ (1.0000000000,0.0000000000) [0.0000000000|1.0000000000] "" Vector__XXX
 SG_ PEPS_RemoteFailedAlarmSignal : 3|1@0+ (1.0000000000,0.0000000000) [0.0000000000|1.0000000000] ""  PCU,PDCU
 SG_ PEPS_SearchCarSignal : 2|1@0+ (1.0000000000,0.0000000000) [0.0000000000|1.0000000000] "" Vector__XXX

BO_ 793 PDU_319: 32 PDU
 SG_ OBC_RollingCounter_319 : 235|4@0+ (1.0000000000,0.0000000000) [0.0000000000|15.0000000000] ""  GW,OBC,PCU,PDCU
 SG_ OBC_CRCCheck_319 : 247|16@0+ (1.0000000000,0.0000000000) [0.0000000000|65535.0000000000] ""  GW,OBC,PCU,PDCU,PDU,BMS
 SG_ DCAC_DcacInpU : 199|13@0+ (0.1000000000,0.0000000000) [0.0000000000|500.0000000000] "V"  PCU,PDCU,GW,OBC,PDU
 SG_ DCAC_DcacInpI : 227|8@0+ (0.1000000000,0.0000000000) [0.0000000000|25.5000000000] "A"  PCU,PDCU,GW,OBC,PDU
 SG_ OBC_ResetSts : 189|3@0+ (1.0000000000,0.0000000000) [0.0000000000|7.0000000000] ""  OBC,PDU,GW
 SG_ OBC_MILONReq : 129|1@0+ (1.0000000000,0.0000000000) [0.0000000000|1.0000000000] ""  OBC,GW,PCU,PDCU,EMS
 SG_ OBC_IntT : 181|8@0+ (1.0000000000,-40.0000000000) [-40.0000000000|120.0000000000] "DegreeC"  OBC,PDU,GW,PCU,PDCU
 SG_ DCAC_DcacPwrCnseAct : 153|10@0+ (10.0000000000,0.0000000000) [0.0000000000|6000.0000000000] "W"  OBC,PDU,GW,PCU,PDCU
 SG_ DCAC_DcacOutpU : 137|8@0+ (1.0000000000,0.0000000000) [0.0000000000|255.0000000000] "V"  OBC,PDU,GW,PCU,PDCU
 SG_ DCAC_DcacOutpPwrAvlMax : 175|10@0+ (10.0000000000,0.0000000000) [0.0000000000|6000.0000000000] "W"  OBC,PDU,GW,PCU,PDCU
 SG_ DCAC_DcacOutpI : 145|7@0+ (1.0000000000,0.0000000000) [0.0000000000|120.0000000000] "A"  OBC,PDU,GW,PCU,PDCU
 SG_ DCAC_DcacOperMod : 135|3@0+ (1.0000000000,0.0000000000) [0.0000000000|7.0000000000] ""  OBC,PDU,GW,PCU,PDCU,TMS,BDC
 SG_ DCAC_DcacFltRnk : 132|3@0+ (1.0000000000,0.0000000000) [0.0000000000|7.0000000000] ""  OBC,PDU,GW,PCU,PDCU
 SG_ DCAC_DcacErrNr : 128|7@0+ (1.0000000000,0.0000000000) [0.0000000000|120.0000000000] ""  OBC,PDU,GW
 SG_ OBC_ObcWaterT : 109|8@0+ (1.0000000000,-40.0000000000) [-40.0000000000|120.0000000000] "DegreeC"  OBC,PDU,PCU,PDCU,GW,BMS,TMS,BDC
 SG_ OBC_ObcTOverWarn : 124|1@0+ (1.0000000000,0.0000000000) [0.0000000000|1.0000000000] ""  OBC,PDU,PCU,PDCU,GW
 SG_ OBC_ObcErrNr : 117|8@0+ (1.0000000000,0.0000000000) [0.0000000000|255.0000000000] ""  OBC,PDU,GW,BMS,PCU,PDCU
 SG_ OBC_ObcChrgInpAcU : 71|9@0+ (1.0000000000,0.0000000000) [0.0000000000|500.0000000000] "V"  OBC,PDU,PCU,PDCU,GW,BMS
 SG_ OBC_ObcChrgInpAcI : 78|10@0+ (0.1000000000,0.0000000000) [0.0000000000|100.0000000000] "A"  OBC,PDU,PCU,PDCU,GW,BMS
 SG_ OBC_ObcChrgDcU : 84|13@0+ (0.1000000000,0.0000000000) [0.0000000000|500.0000000000] "V"  OBC,PDU,PCU,PDCU,GW,BMS
 SG_ OBC_ObcChrgDcI : 103|10@0+ (0.1000000000,0.0000000000) [0.0000000000|100.0000000000] "A"  OBC,PDU,PCU,PDCU,GW,BMS
 SG_ OBC_Obc349CycCntr : 123|4@0+ (1.0000000000,0.0000000000) [0.0000000000|15.0000000000] ""  OBC,GW,BMS
 SG_ OBC_HVPwrOnReq : 125|1@0+ (1.0000000000,0.0000000000) [0.0000000000|1.0000000000] ""  OBC,PDU,PCU,PDCU,GW
 SG_ OBC_ObcWakeupSrc : 63|2@0+ (1.0000000000,0.0000000000) [0.0000000000|1.0000000000] ""  OBC,PDU,GW
 SG_ OBC_ObcS2Sts : 48|1@0+ (1.0000000000,0.0000000000) [0.0000000000|1.0000000000] ""  OBC,PDU,GW,BMS,PCU,PDCU
 SG_ OBC_ObcMaxChrgOutpUAvl : 7|13@0+ (0.1000000000,0.0000000000) [0.0000000000|500.0000000000] "V"  OBC,PDU,GW,BMS,PCU,PDCU
 SG_ OBC_ObcMaxChrgOutpPwrAvl : 16|10@0+ (10.0000000000,0.0000000000) [0.0000000000|10000.0000000000] "w"  OBC,PDU,GW,BMS,PCU,PDCU
 SG_ OBC_ObcMaxChrgOutpIAvl : 10|10@0+ (0.1000000000,0.0000000000) [0.0000000000|100.0000000000] "A"  OBC,PDU,GW,BMS,PCU,PDCU
 SG_ OBC_ObcFltRnk : 55|2@0+ (1.0000000000,0.0000000000) [0.0000000000|3.0000000000] ""  OBC,PDU,GW,PCU,PDCU
 SG_ OBC_ObcCpValVld : 46|1@0+ (1.0000000000,0.0000000000) [0.0000000000|1.0000000000] ""  OBC,PDU,GW,BMS,PCU,PDCU
 SG_ OBC_ObcCpVal : 38|8@0+ (1.0000000000,0.0000000000) [0.0000000000|100.0000000000] "%"  OBC,PDU,GW,BMS,PCU,PDCU
 SG_ OBC_ObcCpOutpU : 45|6@0+ (0.5000000000,0.0000000000) [0.0000000000|31.5000000000] "V"  OBC,PDU,GW
 SG_ OBC_ObcChrgSts : 53|4@0+ (1.0000000000,0.0000000000) [0.0000000000|6.0000000000] ""  OBC,PDU,GW,BMS,PCU,PDCU,TMS,BDC
 SG_ OBC_Obc319CycCntr : 59|4@0+ (1.0000000000,0.0000000000) [0.0000000000|15.0000000000] ""  OBC,PDU,GW,BMS,PCU,PDCU
 SG_ OBC_ChargeCoverSts : 49|1@0+ (1.0000000000,0.0000000000) [0.0000000000|1.0000000000] ""  OBC,GW,PCU,PDCU

BO_ 804 GW_324: 8 GW
 SG_ TMS_ClearDiagnositicInfo : 45|2@0+ (1.0000000000,0.0000000000) [0.0000000000|3.0000000000] "Rpm"  EMS,PDCU
 SG_ TMS_PwrSafeAct : 39|8@0+ (50.0000000000,0.0000000000) [0.0000000000|12750.0000000000] "W"  PCU,PDCU
 SG_ TMS_PwrMinReq : 55|8@0+ (100.0000000000,0.0000000000) [0.0000000000|25500.0000000000] "W"  PCU,PDCU
 SG_ TMS_PwrMaxReq : 23|8@0+ (100.0000000000,0.0000000000) [0.0000000000|25500.0000000000] "W"  PCU,PDCU
 SG_ TMS_PTC_Current : 7|8@0+ (1.0000000000,0.0000000000) [0.0000000000|255.0000000000] "A"  PCU,PDCU
 SG_ TMS_Motor_Temp_inValid : 47|1@0+ (1.0000000000,0.0000000000) [0.0000000000|1.0000000000] ""  DPEU,GPEU
 SG_ TMS_Motor_Temp_in : 15|8@0+ (1.0000000000,-40.0000000000) [-40.0000000000|120.0000000000] "��"  DPEU,GPEU
 SG_ TMS_MILONReq : 46|1@0+ (1.0000000000,0.0000000000) [0.0000000000|1.0000000000] ""  PCU,PDCU,EMS
 SG_ TMS_BattT_out : 31|8@0+ (1.0000000000,-40.0000000000) [-40.0000000000|120.0000000000] "��" Vector__XXX
 SG_ TMS_WaterPumpDutyCycle : 62|7@0+ (1.0000000000,0.0000000000) [0.0000000000|100.0000000000] ""  DPEU,GPEU

BO_ 838 EMS_346: 64 EMS
 SG_ EMS_ReFueldSts : 233|1@0+ (1.0000000000,0.0000000000) [0.0000000000|1.0000000000] ""  EMS,PCU,PDCU,GW
 SG_ EMS_NormalDteskEvapdiareq : 232|1@0+ (1.0000000000,0.0000000000) [0.0000000000|1.0000000000] ""  EMS,PCU,PDCU,GW
 SG_ EMS_ClearTMSDiagnositicInfo : 80|2@0+ (1.0000000000,0.0000000000) [0.0000000000|3.0000000000] "KW"  EMS,PDCU,GW,TMS,BDC
 SG_ EMS_CleaGPEUDiagnosticInfo : 185|2@0+ (1.0000000000,0.0000000000) [0.0000000000|3.0000000000] ""  EMS,PDCU,DPEU,GPEU,GW
 SG_ EMS_EngStrtInhb : 51|2@0+ (1.0000000000,0.0000000000) [0.0000000000|3.0000000000] ""  EMS,PDCU,GW,PCU
 SG_ EMS_CoolantThermostatDC : 280|4@0+ (10.0000000000,0.0000000000) [0.0000000000|100.0000000000] "Percent"  EMS,PDCU,GW,TMS,BDC
 SG_ EMS_flgWtrPmpErr : 281|1@0+ (1.0000000000,0.0000000000) [0.0000000000|1.0000000000] ""  EMS,PDCU,GW,TMS,BDC
 SG_ EMS_WtrPmpActSpd : 275|10@0+ (10.0000000000,0.0000000000) [0.0000000000|10220.0000000000] "RPM"  EMS,PDCU,GW,TMS,BDC
 SG_ EMS_WtrPmpTargetSpd : 269|10@0+ (10.0000000000,0.0000000000) [0.0000000000|10220.0000000000] "RPM"  EMS,PDCU,GW,TMS,BDC
 SG_ EMS_EngTargetCoolantTemp : 259|6@0+ (1.0000000000,60.0000000000) [60.0000000000|120.0000000000] "��"  EMS,PDCU,GW,TMS,BDC
 SG_ EMS_ClearOBCDiagnosticInfo : 187|2@0+ (1.0000000000,0.0000000000) [0.0000000000|3.0000000000] ""  EMS,PDCU,OBC,GW
 SG_ EMS_EngProtectionActive : 49|2@0+ (1.0000000000,0.0000000000) [0.0000000000|3.0000000000] ""  EMS,PDCU,GW,PCU
 SG_ EMS_MILIndcdLightInfo : 263|4@0+ (1.0000000000,0.0000000000) [0.0000000000|15.0000000000] ""  EMS,PDCU,PCU,GW
 SG_ EMS_EGRDia : 244|1@0+ (1.0000000000,0.0000000000) [0.0000000000|1.0000000000] ""  EMS,PCU,PDCU,GW
 SG_ Ems_GpfSrvRgnReq : 117|1@0+ (1.0000000000,0.0000000000) [0.0000000000|1.0000000000] ""  EMS,PCU,PDCU,GW
 SG_ EMS_DenominatorCntr2 : 181|1@0+ (1.0000000000,0.0000000000) [0.0000000000|1.0000000000] ""  EMS,PDCU,RPEU,GW,OBC
 SG_ EMS_DenominatorCntr1 : 180|1@0+ (1.0000000000,0.0000000000) [0.0000000000|1.0000000000] ""  EMS,PDCU,RPEU,GW,OBC
 SG_ EmsEngCoolanT2 : 78|8@0+ (0.7500000000,-48.0000000000) [-48.0000000000|142.5000000000] "��"  EMS,PDCU,GW,TMS,BDC
 SG_ EMS_ClearRPEUDiagnosticInfo : 191|2@0+ (1.0000000000,0.0000000000) [0.0000000000|3.0000000000] ""  EMS,PDCU,RPEU,GW
 SG_ Ems_EngRvsTowingReq : 85|1@0+ (1.0000000000,0.0000000000) [0.0000000000|1.0000000000] ""  EMS,PCU,PDCU,GW
 SG_ Ems_EngFuCutOffFbd : 84|1@0+ (1.0000000000,0.0000000000) [0.0000000000|1.0000000000] ""  EMS,PCU,PDCU,GW
 SG_ Ems_GpfActvRgnReq : 86|1@0+ (1.0000000000,0.0000000000) [0.0000000000|1.0000000000] ""  EMS,PCU,PDCU,GW
 SG_ Ems_FltRnk : 247|3@0+ (1.0000000000,0.0000000000) [0.0000000000|7.0000000000] ""  EMS,PCU,PDCU,GW
 SG_ EMS_RollingCounter_346 : 491|4@0+ (1.0000000000,0.0000000000) [0.0000000000|15.0000000000] ""  GW,EMS,PDCU
 SG_ EMS_CRCCheck_346 : 503|16@0+ (1.0000000000,0.0000000000) [0.0000000000|65535.0000000000] ""  GW,EMS,PDCU
 SG_ EMS_CleaDPEUDiagnosticInfo : 111|2@0+ (1.0000000000,0.0000000000) [0.0000000000|3.0000000000] ""  EMS,PDCU,GW,DPEU,GPEU
 SG_ EMS_ThrottleRelativePosition : 159|8@0+ (0.3920000000,0.0000000000) [0.0000000000|99.5680000000] "%"  EMS,PDCU,PCU,GW,BMS,DPEU,GPEU,OBC
 SG_ EMS_ThrottleAbsolutePosition : 151|8@0+ (0.3920000000,0.0000000000) [0.0000000000|99.5680000000] "%"  EMS,PDCU,PCU,GW,BMS,DPEU,GPEU,OBC
 SG_ EMS_PwrTrainStopTime : 167|16@0+ (1.0000000000,0.0000000000) [0.0000000000|65534.0000000000] "s"  EMS,PDCU,PCU,GW,BMS,DPEU,GPEU,OBC
 SG_ EMS_PwrTrainRunningTime : 135|16@0+ (1.0000000000,0.0000000000) [0.0000000000|65534.0000000000] "s"  EMS,PDCU,PCU,GW,BMS,OBC,DPEU,GPEU
 SG_ EMS_ClearPCUDiagnosticInfo : 179|2@0+ (1.0000000000,0.0000000000) [0.0000000000|3.0000000000] ""  EMS,PDCU,PCU,GW
 SG_ EMS_ClearIBCUDiagnosticInfo : 189|2@0+ (1.0000000000,0.0000000000) [0.0000000000|3.0000000000] ""  EMS,PDCU,GW
 SG_ EMS_ClearBMSDiagnosticInfo : 183|2@0+ (1.0000000000,0.0000000000) [0.0000000000|3.0000000000] ""  EMS,PDCU,GW,BMS
 SG_ EMS_PFCCCondition : 79|1@0+ (1.0000000000,0.0000000000) [0.0000000000|1.0000000000] ""  EMS,PDCU,PCU,GW,BMS,DPEU,GPEU,RPEU,OBC
 SG_ EMS_GPF_State : 83|3@0+ (1.0000000000,0.0000000000) [0.0000000000|7.0000000000] ""  EMS,PDCU,GW,PCU
 SG_ EMS_EngLoad : 71|8@0+ (0.3920000000,0.0000000000) [0.0000000000|99.5680000000] "%"  EMS,PDCU,GW,PCU,BMS,DPEU,GPEU,RPEU,OBC
 SG_ EMS_OxygenSensorDia : 23|1@0+ (1.0000000000,0.0000000000) [0.0000000000|1.0000000000] ""  GW,EMS,PDCU,PCU
 SG_ EMS_LowPreOilPumpProRemind : 22|1@0+ (1.0000000000,0.0000000000) [0.0000000000|1.0000000000] ""  EMS,PDCU,GW,PCU
 SG_ EMS_EngProtectionRemind : 21|2@0+ (1.0000000000,0.0000000000) [0.0000000000|3.0000000000] ""  EMS,PDCU,GW
 SG_ EMS_TotOdometer : 31|24@0+ (0.1000000000,0.0000000000) [0.0000000000|999999.0000000000] "Km"  EMS,PDCU,GW
 SG_ EMS_SVSLamp : 7|1@0+ (1.0000000000,0.0000000000) [0.0000000000|1.0000000000] ""  EMS,PDCU,GW
 SG_ EMS_OilPressureSts : 4|1@0+ (1.0000000000,0.0000000000) [0.0000000000|1.0000000000] ""  EMS,PDCU,GW
 SG_ EMS_MILIndcd : 6|2@0+ (1.0000000000,0.0000000000) [0.0000000000|3.0000000000] ""  EMS,PDCU,GW
 SG_ EMS_FuelCapLeakDisplay : 55|1@0+ (1.0000000000,0.0000000000) [0.0000000000|1.0000000000] ""  EMS,PDCU,GW
 SG_ EMS_FuCnse : 3|12@0+ (0.0010000000,0.0000000000) [0.0000000000|4.0950000000] ""  EMS,PDCU,GW,PCU
 SG_ EMS_EngOilT : 63|8@0+ (1.0000000000,-40.0000000000) [-40.0000000000|213.0000000000] "DegreeC"  EMS,PDCU,GW

BO_ 870 GW_366: 8 GW
 SG_ AC_TargetTorque : 3|8@0+ (0.1000000000,0.0000000000) [0.0000000000|25.4000000000] "Nm"  EMS
 SG_ AC_WorkSts : 4|3@0+ (1.0000000000,0.0000000000) [0.0000000000|7.0000000000] ""  PCU,PDCU
 SG_ AC_PTCStatus : 10|2@0+ (1.0000000000,0.0000000000) [0.0000000000|3.0000000000] ""  EMS
 SG_ AC_SolenoidCurrent : 47|8@0+ (0.0040000000,0.0000000000) [0.0000000000|1.0160000000] "A"  EMS
 SG_ AC_CompressorStatus : 5|1@0+ (1.0000000000,0.0000000000) [0.0000000000|1.0000000000] ""  EMS
 SG_ AC_ACPre : 27|12@0+ (0.0100000000,0.0000000000) [0.0000000000|40.9400000000] "Mpa"  EMS
 SG_ AC_AC_ReqValid : 54|1@0+ (1.0000000000,0.0000000000) [0.0000000000|1.0000000000] ""  EMS,PCU,PDCU
 SG_ AC_FrReqWindLevel : 31|4@0+ (1.0000000000,0.0000000000) [0.0000000000|15.0000000000] ""  EMS,PCU,PDCU
 SG_ AC_FrReqWindLevelVD : 11|1@0+ (1.0000000000,0.0000000000) [0.0000000000|1.0000000000] ""  EMS,PCU,PDCU
 SG_ AC_AC_Req : 55|1@0+ (1.0000000000,0.0000000000) [0.0000000000|1.0000000000] ""  EMS,PCU,PDCU
 SG_ AC_EnvironmentalTemp : 23|8@0+ (0.5000000000,-40.0000000000) [-40.0000000000|87.0000000000] "degreeC"  EMS,PCU,PDCU
 SG_ AC_EnvironmentalTempVD : 8|1@0+ (1.0000000000,0.0000000000) [0.0000000000|1.0000000000] ""  EMS,PCU,PDCU

BO_ 1302 GW_516: 32 GW
 SG_ HU_AirHumidityValid : 87|1@0+ (1.0000000000,0.0000000000) [0.0000000000|1.0000000000] ""  EMS,PDCU
 SG_ HU_AirHumidity : 70|7@0+ (1.0000000000,0.0000000000) [0.0000000000|100.0000000000] "%"  EMS,PDCU
 SG_ HU_LeaveMaintainMileage : 147|20@0+ (1.0000000000,0.0000000000) [0.0000000000|100000.0000000000] "km" Vector__XXX
 SG_ HU_LeaveMaintainDay : 131|12@0+ (1.0000000000,0.0000000000) [0.0000000000|3100.0000000000] "��" Vector__XXX
 SG_ HU_MaintainRemindReq : 133|2@0+ (1.0000000000,0.0000000000) [0.0000000000|3.0000000000] "" Vector__XXX
 SG_ HU_LocalTimeSystem : 111|2@0+ (1.0000000000,0.0000000000) [0.0000000000|3.0000000000] ""  BMS,OBC,PCU,PDCU,RPEU,DPEU,GPEU,PDU
 SG_ HU_LocalTimeSecond : 109|6@0+ (1.0000000000,0.0000000000) [0.0000000000|59.0000000000] "second"  BMS,OBC,PCU,PDCU,RPEU,DPEU,GPEU,PDU
 SG_ HU_LocalTimeMinute : 101|6@0+ (1.0000000000,0.0000000000) [0.0000000000|59.0000000000] "minute"  BMS,OBC,PCU,PDCU,RPEU,DPEU,GPEU,PDU
 SG_ HU_LocalTimeHour : 92|5@0+ (1.0000000000,0.0000000000) [0.0000000000|23.0000000000] "hour"  BMS,OBC,PCU,PDCU,RPEU,DPEU,GPEU,PDU
 SG_ HU_LocalTimeDate : 84|5@0+ (1.0000000000,0.0000000000) [1.0000000000|31.0000000000] "day"  BMS,OBC,PCU,PDCU,RPEU,DPEU,GPEU,PDU
 SG_ HU_LocalTimeYear : 119|8@0+ (1.0000000000,2013.0000000000) [2013.0000000000|2268.0000000000] "year"  BMS,OBC,PCU,PDCU,RPEU,DPEU,GPEU,PDU
 SG_ HU_LocalTimeMonth : 75|4@0+ (1.0000000000,0.0000000000) [1.0000000000|12.0000000000] "month"  BMS,OBC,PCU,PDCU,RPEU,DPEU,GPEU,PDU
 SG_ HU_LocalTimeValid : 71|1@0+ (1.0000000000,0.0000000000) [0.0000000000|1.0000000000] ""  BMS,OBC,PCU,PDCU,RPEU,DPEU,GPEU,PDU
 SG_ HU_CurrentLocationLatitude : 35|28@0+ (0.0000010000,-134.2177270000) [-90.0000000000|90.0000000000] "degree" Vector__XXX
 SG_ HU_CurrentLocationLongitude : 4|29@0+ (0.0000010000,-268.4354550000) [-180.0000000000|180.0000000000] "degree" Vector__XXX
 SG_ HU_CurrentLocationValid : 7|1@0+ (1.0000000000,0.0000000000) [0.0000000000|1.0000000000] "" Vector__XXX

BO_ 1304 GW_518: 8 GW
 SG_ BCM_CarMode : 11|2@0+ (1.0000000000,0.0000000000) [0.0000000000|3.0000000000] ""  EMS,PDCU

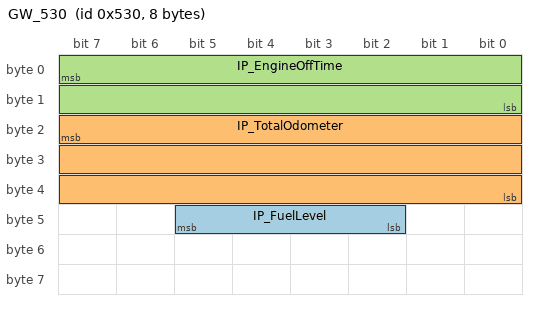
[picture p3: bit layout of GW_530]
BO_ 1328 GW_530: 8 GW
 SG_ IP_FuelLevel : 45|4@0+ (1.0000000000,0.0000000000) [0.0000000000|15.0000000000] "" Vector__XXX
 SG_ IP_TotalOdometer : 23|24@0+ (0.1000000000,0.0000000000) [0.0000000000|999999.0000000000] "Km"  BMS,EMS,PCU,PDCU,DPEU,GPEU
 SG_ IP_EngineOffTime : 7|16@0+ (1.0000000000,0.0000000000) [0.0000000000|65535.0000000000] "s"  PCU,PDCU

BO_ 1333 BMS_535: 32 BMS
 SG_ BMS_BcuCycWakupCount : 220|5@0+ (1.0000000000,0.0000000000) [0.0000000000|31.0000000000] ""  GW
 SG_ BMS_BcuCycWakupSts : 231|1@0+ (1.0000000000,0.0000000000) [0.0000000000|1.0000000000] ""  GW
 SG_ BMS_CellDeltaU : 67|11@0+ (0.0010000000,0.0000000000) [0.0000000000|2.0000000000] "V"  GW
 SG_ BMS_ModTRiseValue : 72|7@0+ (0.1000000000,0.0000000000) [0.0000000000|10.0000000000] "��/s"  GW
 SG_ BMS_ModTRiseQntty : 91|4@0+ (1.0000000000,0.0000000000) [0.0000000000|15.0000000000] ""  GW
 SG_ BMS_ModTRiseNum : 81|6@0+ (1.0000000000,0.0000000000) [0.0000000000|60.0000000000] ""  GW
 SG_ BMS_CellUdownErrQntty : 124|5@0+ (1.0000000000,0.0000000000) [0.0000000000|31.0000000000] ""  GW
 SG_ BMS_CellUdownErrNum : 117|8@0+ (1.0000000000,0.0000000000) [0.0000000000|168.0000000000] ""  GW
 SG_ BMS_SosMixSt : 15|24@0+ (1.0000000000,0.0000000000) [0.0000000000|16777215.0000000000] ""  GW
 SG_ BMS_PackARMU : 50|11@0+ (10.0000000000,0.0000000000) [0.0000000000|20470.0000000000] "ug/m3 "  GW
 SG_ BMS_DataUploadReq : 51|1@0+ (1.0000000000,0.0000000000) [0.0000000000|1.0000000000] ""  GW
 SG_ BMS_Wkpmod : 6|3@0+ (1.0000000000,0.0000000000) [0.0000000000|7.0000000000] ""  GW
 SG_ BMS_SwitchSts : 41|1@0+ (1.0000000000,0.0000000000) [0.0000000000|1.0000000000] ""  BCU,GW
 SG_ BMS_PckPrssrSts : 43|2@0+ (1.0000000000,0.0000000000) [0.0000000000|3.0000000000] ""  BCU,GW
 SG_ BMS_PackPRMU : 39|12@0+ (0.1000000000,0.0000000000) [0.0000000000|409.5000000000] "kpa"  BCU,GW
 SG_ BMS_HeatWarngSts : 40|3@0+ (1.0000000000,0.0000000000) [0.0000000000|7.0000000000] ""  BCU,GW
 SG_ BMS_HeatSftyStsRMU : 7|1@0+ (1.0000000000,0.0000000000) [0.0000000000|1.0000000000] ""  BCU,PCU,PDCU,GW
 SG_ BMS_StopCarTi : 199|27@0+ (1.0000000000,0.0000000000) [0.0000000000|134217727.0000000000] "/s"  GW
 SG_ BMS_CycleNr : 143|16@0+ (1.0000000000,0.0000000000) [0.0000000000|65535.0000000000] ""  GW
 SG_ BMS_CycleSt : 135|8@0+ (1.0000000000,0.0000000000) [0.0000000000|255.0000000000] ""  GW
 SG_ BMS_FirstCellU : 159|16@0+ (0.0010000000,0.0000000000) [0.0000000000|65.5350000000] "V"  GW

BO_ 1541 BMS_605: 64 BMS
 SG_ BMS_SOCUproModDisp : 359|2@0+ (1.0000000000,0.0000000000) [0.0000000000|2.0000000000] ""  GW
 SG_ BMS_SOCOverFlgDisp : 376|1@0+ (1.0000000000,0.0000000000) [0.0000000000|1.0000000000] ""  GW
 SG_ BMS_SOCEKFDisp : 366|10@0+ (0.1000000000,0.0000000000) [0.0000000000|100.0000000000] ""  GW
 SG_ BMS_BattResidPwr : 343|16@0+ (0.1000000000,0.0000000000) [0.0000000000|100.0000000000] "kWh"  PDCU,PCU,GW
 SG_ BMS_BattRatedAh : 327|16@0+ (0.2000000000,0.0000000000) [0.0000000000|300.0000000000] "Ah"  PDCU,PCU,GW
 SG_ BMS_SOCCntrDisp : 311|16@0+ (1.0000000000,0.0000000000) [0.0000000000|65535.0000000000] ""  GW
 SG_ BMS_VehCANErr : 207|1@0+ (1.0000000000,0.0000000000) [0.0000000000|1.0000000000] ""  GW
 SG_ BMS_SOHBattCpDisp : 219|10@0+ (0.5000000000,0.0000000000) [0.0000000000|500.0000000000] ""  GW
 SG_ BMS_SOCEstDisp : 213|10@0+ (0.1000000000,0.0000000000) [0.0000000000|100.0000000000] ""  GW
 SG_ BMS_OverCrrtDischrg : 202|1@0+ (1.0000000000,0.0000000000) [0.0000000000|1.0000000000] ""  GW
 SG_ BMS_OverCrrtChrg : 203|1@0+ (1.0000000000,0.0000000000) [0.0000000000|1.0000000000] ""  GW
 SG_ BMS_SwVers : 71|10@0+ (1.0000000000,0.0000000000) [0.0000000000|1023.0000000000] ""  PDCU,PCU
 SG_ BMS_SwSn : 89|4@0+ (1.0000000000,0.0000000000) [0.0000000000|15.0000000000] ""  PDCU,PCU
 SG_ BMS_SwNm : 111|8@0+ (1.0000000000,0.0000000000) [0.0000000000|255.0000000000] ""  PDCU,PCU
 SG_ BMS_HwVers : 77|10@0+ (1.0000000000,0.0000000000) [0.0000000000|1023.0000000000] ""  PDCU,PCU
 SG_ BMS_CalDataVers : 83|10@0+ (1.0000000000,0.0000000000) [0.0000000000|1023.0000000000] ""  PDCU,PCU
 SG_ BMS_BattSoe : 117|10@0+ (0.1000000000,0.0000000000) [0.0000000000|100.0000000000] "%"  PDCU,PCU
 SG_ BMS_SOH : 23|10@0+ (0.1000000000,0.0000000000) [0.0000000000|100.0000000000] "%"  PDCU,PCU,GW
 SG_ BMS_SOCMin : 15|8@0+ (1.0000000000,0.0000000000) [0.0000000000|100.0000000000] "%"  PDCU,PCU,GW
 SG_ BMS_SOCMax : 7|8@0+ (1.0000000000,0.0000000000) [0.0000000000|100.0000000000] "%"  PDCU,PCU,GW
 SG_ BMS_RmaingCpby : 29|15@0+ (0.1000000000,0.0000000000) [0.0000000000|500.0000000000] "Ah"  PDCU,PCU,GW
 SG_ BMS_ChrgnSysIAllwdMax : 45|9@0+ (1.0000000000,0.0000000000) [0.0000000000|400.0000000000] "A"  PDCU,PCU,GW
 SG_ BMS_BattT_InpReq : 63|8@0+ (1.0000000000,-40.0000000000) [-40.0000000000|125.0000000000] "DegreeC"  GW,TMS,BDC

BO_ 1590 BMS_636: 64 BMS
 SG_ BMS_CellEquilnSts168 : 187|1@0+ (1.0000000000,0.0000000000) [0.0000000000|1.0000000000] ""  GW
 SG_ BMS_CellEquilnSts167 : 186|1@0+ (1.0000000000,0.0000000000) [0.0000000000|1.0000000000] ""  GW
 SG_ BMS_CellEquilnSts166 : 185|1@0+ (1.0000000000,0.0000000000) [0.0000000000|1.0000000000] ""  GW
 SG_ BMS_CellEquilnSts165 : 184|1@0+ (1.0000000000,0.0000000000) [0.0000000000|1.0000000000] ""  GW
 SG_ BMS_CellEquilnSts164 : 183|1@0+ (1.0000000000,0.0000000000) [0.0000000000|1.0000000000] ""  GW
 SG_ BMS_CellEquilnSts163 : 182|1@0+ (1.0000000000,0.0000000000) [0.0000000000|1.0000000000] ""  GW
 SG_ BMS_CellEquilnSts162 : 181|1@0+ (1.0000000000,0.0000000000) [0.0000000000|1.0000000000] ""  GW
 SG_ BMS_CellEquilnSts161 : 180|1@0+ (1.0000000000,0.0000000000) [0.0000000000|1.0000000000] ""  GW
 SG_ BMS_CellEquilnSts160 : 179|1@0+ (1.0000000000,0.0000000000) [0.0000000000|1.0000000000] ""  GW
 SG_ BMS_CellEquilnSts159 : 178|1@0+ (1.0000000000,0.0000000000) [0.0000000000|1.0000000000] ""  GW
 SG_ BMS_CellEquilnSts158 : 177|1@0+ (1.0000000000,0.0000000000) [0.0000000000|1.0000000000] ""  GW
 SG_ BMS_CellEquilnSts157 : 176|1@0+ (1.0000000000,0.0000000000) [0.0000000000|1.0000000000] ""  GW
 SG_ BMS_CellEquilnSts156 : 175|1@0+ (1.0000000000,0.0000000000) [0.0000000000|1.0000000000] ""  GW
 SG_ BMS_CellEquilnSts155 : 174|1@0+ (1.0000000000,0.0000000000) [0.0000000000|1.0000000000] ""  GW
 SG_ BMS_CellEquilnSts154 : 173|1@0+ (1.0000000000,0.0000000000) [0.0000000000|1.0000000000] ""  GW
 SG_ BMS_CellEquilnSts153 : 172|1@0+ (1.0000000000,0.0000000000) [0.0000000000|1.0000000000] ""  GW
 SG_ BMS_CellEquilnSts152 : 171|1@0+ (1.0000000000,0.0000000000) [0.0000000000|1.0000000000] ""  GW
 SG_ BMS_CellEquilnSts151 : 170|1@0+ (1.0000000000,0.0000000000) [0.0000000000|1.0000000000] ""  GW
 SG_ BMS_CellEquilnSts150 : 169|1@0+ (1.0000000000,0.0000000000) [0.0000000000|1.0000000000] ""  GW
 SG_ BMS_CellEquilnSts149 : 168|1@0+ (1.0000000000,0.0000000000) [0.0000000000|1.0000000000] ""  GW
 SG_ BMS_CellEquilnSts148 : 167|1@0+ (1.0000000000,0.0000000000) [0.0000000000|1.0000000000] ""  GW
 SG_ BMS_CellEquilnSts147 : 166|1@0+ (1.0000000000,0.0000000000) [0.0000000000|1.0000000000] ""  GW
 SG_ BMS_CellEquilnSts146 : 165|1@0+ (1.0000000000,0.0000000000) [0.0000000000|1.0000000000] ""  GW
 SG_ BMS_CellEquilnSts145 : 164|1@0+ (1.0000000000,0.0000000000) [0.0000000000|1.0000000000] ""  GW
 SG_ BMS_CellEquilnSts144 : 163|1@0+ (1.0000000000,0.0000000000) [0.0000000000|1.0000000000] ""  GW
 SG_ BMS_CellEquilnSts143 : 162|1@0+ (1.0000000000,0.0000000000) [0.0000000000|1.0000000000] ""  GW
 SG_ BMS_CellEquilnSts142 : 161|1@0+ (1.0000000000,0.0000000000) [0.0000000000|1.0000000000] ""  GW
 SG_ BMS_CellEquilnSts141 : 160|1@0+ (1.0000000000,0.0000000000) [0.0000000000|1.0000000000] ""  GW
 SG_ BMS_CellEquilnSts140 : 159|1@0+ (1.0000000000,0.0000000000) [0.0000000000|1.0000000000] ""  GW
 SG_ BMS_CellEquilnSts139 : 158|1@0+ (1.0000000000,0.0000000000) [0.0000000000|1.0000000000] ""  GW
 SG_ BMS_CellEquilnSts138 : 157|1@0+ (1.0000000000,0.0000000000) [0.0000000000|1.0000000000] ""  GW
 SG_ BMS_CellEquilnSts137 : 156|1@0+ (1.0000000000,0.0000000000) [0.0000000000|1.0000000000] ""  GW
 SG_ BMS_CellEquilnSts136 : 155|1@0+ (1.0000000000,0.0000000000) [0.0000000000|1.0000000000] ""  GW
 SG_ BMS_CellEquilnSts135 : 154|1@0+ (1.0000000000,0.0000000000) [0.0000000000|1.0000000000] ""  GW
 SG_ BMS_CellEquilnSts134 : 153|1@0+ (1.0000000000,0.0000000000) [0.0000000000|1.0000000000] ""  GW
 SG_ BMS_CellEquilnSts133 : 152|1@0+ (1.0000000000,0.0000000000) [0.0000000000|1.0000000000] ""  GW
 SG_ BMS_CellEquilnSts132 : 151|1@0+ (1.0000000000,0.0000000000) [0.0000000000|1.0000000000] ""  GW
 SG_ BMS_CellEquilnSts131 : 150|1@0+ (1.0000000000,0.0000000000) [0.0000000000|1.0000000000] ""  GW
 SG_ BMS_CellEquilnSts130 : 149|1@0+ (1.0000000000,0.0000000000) [0.0000000000|1.0000000000] ""  GW
 SG_ BMS_CellEquilnSts129 : 148|1@0+ (1.0000000000,0.0000000000) [0.0000000000|1.0000000000] ""  GW
 SG_ BMS_CellEquilnSts128 : 147|1@0+ (1.0000000000,0.0000000000) [0.0000000000|1.0000000000] ""  GW
 SG_ BMS_CellEquilnSts127 : 146|1@0+ (1.0000000000,0.0000000000) [0.0000000000|1.0000000000] ""  GW
 SG_ BMS_CellEquilnSts126 : 145|1@0+ (1.0000000000,0.0000000000) [0.0000000000|1.0000000000] ""  GW
 SG_ BMS_CellEquilnSts125 : 144|1@0+ (1.0000000000,0.0000000000) [0.0000000000|1.0000000000] ""  GW
 SG_ BMS_CellEquilnSts124 : 143|1@0+ (1.0000000000,0.0000000000) [0.0000000000|1.0000000000] ""  GW
 SG_ BMS_CellEquilnSts123 : 142|1@0+ (1.0000000000,0.0000000000) [0.0000000000|1.0000000000] ""  GW
 SG_ BMS_CellEquilnSts122 : 141|1@0+ (1.0000000000,0.0000000000) [0.0000000000|1.0000000000] ""  GW
 SG_ BMS_CellEquilnSts121 : 140|1@0+ (1.0000000000,0.0000000000) [0.0000000000|1.0000000000] ""  GW
 SG_ BMS_CellEquilnSts120 : 139|1@0+ (1.0000000000,0.0000000000) [0.0000000000|1.0000000000] ""  GW
 SG_ BMS_CellEquilnSts119 : 138|1@0+ (1.0000000000,0.0000000000) [0.0000000000|1.0000000000] ""  GW
 SG_ BMS_CellEquilnSts118 : 137|1@0+ (1.0000000000,0.0000000000) [0.0000000000|1.0000000000] ""  GW
 SG_ BMS_CellEquilnSts117 : 136|1@0+ (1.0000000000,0.0000000000) [0.0000000000|1.0000000000] ""  GW
 SG_ BMS_CellEquilnSts116 : 135|1@0+ (1.0000000000,0.0000000000) [0.0000000000|1.0000000000] ""  GW
 SG_ BMS_CellEquilnSts115 : 134|1@0+ (1.0000000000,0.0000000000) [0.0000000000|1.0000000000] ""  GW
 SG_ BMS_CellEquilnSts114 : 133|1@0+ (1.0000000000,0.0000000000) [0.0000000000|1.0000000000] ""  GW
 SG_ BMS_CellEquilnSts113 : 132|1@0+ (1.0000000000,0.0000000000) [0.0000000000|1.0000000000] ""  GW
 SG_ BMS_CellEquilnSts112 : 131|1@0+ (1.0000000000,0.0000000000) [0.0000000000|1.0000000000] ""  GW
 SG_ BMS_CellEquilnSts111 : 130|1@0+ (1.0000000000,0.0000000000) [0.0000000000|1.0000000000] ""  GW
 SG_ BMS_CellEquilnSts110 : 129|1@0+ (1.0000000000,0.0000000000) [0.0000000000|1.0000000000] ""  GW
 SG_ BMS_CellEquilnSts109 : 128|1@0+ (1.0000000000,0.0000000000) [0.0000000000|1.0000000000] ""  GW
 SG_ BMS_CellEquilnSts108 : 111|1@0+ (1.0000000000,0.0000000000) [0.0000000000|1.0000000000] ""  GW
 SG_ BMS_CellEquilnSts107 : 110|1@0+ (1.0000000000,0.0000000000) [0.0000000000|1.0000000000] ""  GW
 SG_ BMS_CellEquilnSts106 : 109|1@0+ (1.0000000000,0.0000000000) [0.0000000000|1.0000000000] ""  GW
 SG_ BMS_CellEquilnSts105 : 108|1@0+ (1.0000000000,0.0000000000) [0.0000000000|1.0000000000] ""  GW
 SG_ BMS_CellEquilnSts104 : 103|1@0+ (1.0000000000,0.0000000000) [0.0000000000|1.0000000000] ""  GW
 SG_ BMS_CellEquilnSts103 : 102|1@0+ (1.0000000000,0.0000000000) [0.0000000000|1.0000000000] ""  GW
 SG_ BMS_CellEquilnSts102 : 101|1@0+ (1.0000000000,0.0000000000) [0.0000000000|1.0000000000] ""  GW
 SG_ BMS_CellEquilnSts101 : 100|1@0+ (1.0000000000,0.0000000000) [0.0000000000|1.0000000000] ""  GW
 SG_ BMS_CellEquilnSts100 : 99|1@0+ (1.0000000000,0.0000000000) [0.0000000000|1.0000000000] ""  GW
 SG_ BMS_CellEquilnSts99 : 98|1@0+ (1.0000000000,0.0000000000) [0.0000000000|1.0000000000] ""  GW
 SG_ BMS_CellEquilnSts98 : 97|1@0+ (1.0000000000,0.0000000000) [0.0000000000|1.0000000000] ""  GW
 SG_ BMS_CellEquilnSts97 : 96|1@0+ (1.0000000000,0.0000000000) [0.0000000000|1.0000000000] ""  GW
 SG_ BMS_CellEquilnSts96 : 88|1@0+ (1.0000000000,0.0000000000) [0.0000000000|1.0000000000] ""  GW
 SG_ BMS_CellEquilnSts95 : 89|1@0+ (1.0000000000,0.0000000000) [0.0000000000|1.0000000000] ""  GW
 SG_ BMS_CellEquilnSts94 : 90|1@0+ (1.0000000000,0.0000000000) [0.0000000000|1.0000000000] ""  GW
 SG_ BMS_CellEquilnSts93 : 91|1@0+ (1.0000000000,0.0000000000) [0.0000000000|1.0000000000] ""  GW
 SG_ BMS_CellEquilnSts92 : 92|1@0+ (1.0000000000,0.0000000000) [0.0000000000|1.0000000000] ""  GW
 SG_ BMS_CellEquilnSts91 : 93|1@0+ (1.0000000000,0.0000000000) [0.0000000000|1.0000000000] ""  GW
 SG_ BMS_CellEquilnSts90 : 94|1@0+ (1.0000000000,0.0000000000) [0.0000000000|1.0000000000] ""  GW
 SG_ BMS_CellEquilnSts89 : 95|1@0+ (1.0000000000,0.0000000000) [0.0000000000|1.0000000000] ""  GW
 SG_ BMS_CellEquilnSts88 : 80|1@0+ (1.0000000000,0.0000000000) [0.0000000000|1.0000000000] ""  GW
 SG_ BMS_CellEquilnSts87 : 81|1@0+ (1.0000000000,0.0000000000) [0.0000000000|1.0000000000] ""  GW
 SG_ BMS_CellEquilnSts86 : 82|1@0+ (1.0000000000,0.0000000000) [0.0000000000|1.0000000000] ""  GW
 SG_ BMS_CellEquilnSts85 : 83|1@0+ (1.0000000000,0.0000000000) [0.0000000000|1.0000000000] ""  GW
 SG_ BMS_CellEquilnSts84 : 84|1@0+ (1.0000000000,0.0000000000) [0.0000000000|1.0000000000] ""  GW
 SG_ BMS_CellEquilnSts83 : 85|1@0+ (1.0000000000,0.0000000000) [0.0000000000|1.0000000000] ""  GW
 SG_ BMS_CellEquilnSts82 : 86|1@0+ (1.0000000000,0.0000000000) [0.0000000000|1.0000000000] ""  GW
 SG_ BMS_CellEquilnSts81 : 87|1@0+ (1.0000000000,0.0000000000) [0.0000000000|1.0000000000] ""  GW
 SG_ BMS_CellEquilnSts80 : 72|1@0+ (1.0000000000,0.0000000000) [0.0000000000|1.0000000000] ""  GW
 SG_ BMS_CellEquilnSts79 : 73|1@0+ (1.0000000000,0.0000000000) [0.0000000000|1.0000000000] ""  GW
 SG_ BMS_CellEquilnSts78 : 74|1@0+ (1.0000000000,0.0000000000) [0.0000000000|1.0000000000] ""  GW
 SG_ BMS_CellEquilnSts77 : 75|1@0+ (1.0000000000,0.0000000000) [0.0000000000|1.0000000000] ""  GW
 SG_ BMS_CellEquilnSts76 : 76|1@0+ (1.0000000000,0.0000000000) [0.0000000000|1.0000000000] ""  GW
 SG_ BMS_CellEquilnSts75 : 77|1@0+ (1.0000000000,0.0000000000) [0.0000000000|1.0000000000] ""  GW
 SG_ BMS_CellEquilnSts74 : 78|1@0+ (1.0000000000,0.0000000000) [0.0000000000|1.0000000000] ""  GW
 SG_ BMS_CellEquilnSts73 : 79|1@0+ (1.0000000000,0.0000000000) [0.0000000000|1.0000000000] ""  GW
 SG_ BMS_CellEquilnSts72 : 64|1@0+ (1.0000000000,0.0000000000) [0.0000000000|1.0000000000] ""  GW
 SG_ BMS_CellEquilnSts71 : 65|1@0+ (1.0000000000,0.0000000000) [0.0000000000|1.0000000000] ""  GW
 SG_ BMS_CellEquilnSts70 : 66|1@0+ (1.0000000000,0.0000000000) [0.0000000000|1.0000000000] ""  GW
 SG_ BMS_CellEquilnSts69 : 67|1@0+ (1.0000000000,0.0000000000) [0.0000000000|1.0000000000] ""  GW
 SG_ BMS_CellEquilnSts68 : 68|1@0+ (1.0000000000,0.0000000000) [0.0000000000|1.0000000000] ""  GW
 SG_ BMS_CellEquilnSts67 : 69|1@0+ (1.0000000000,0.0000000000) [0.0000000000|1.0000000000] ""  GW
 SG_ BMS_CellEquilnSts66 : 70|1@0+ (1.0000000000,0.0000000000) [0.0000000000|1.0000000000] ""  GW
 SG_ BMS_CellEquilnSts65 : 71|1@0+ (1.0000000000,0.0000000000) [0.0000000000|1.0000000000] ""  GW
 SG_ BMS_CellEquilnSts9 : 15|1@0+ (1.0000000000,0.0000000000) [0.0000000000|1.0000000000] ""  GW
 SG_ BMS_CellEquilnSts8 : 0|1@0+ (1.0000000000,0.0000000000) [0.0000000000|1.0000000000] ""  GW
 SG_ BMS_CellEquilnSts7 : 1|1@0+ (1.0000000000,0.0000000000) [0.0000000000|1.0000000000] ""  GW
 SG_ BMS_CellEquilnSts64 : 56|1@0+ (1.0000000000,0.0000000000) [0.0000000000|1.0000000000] ""  GW
 SG_ BMS_CellEquilnSts63 : 57|1@0+ (1.0000000000,0.0000000000) [0.0000000000|1.0000000000] ""  GW
 SG_ BMS_CellEquilnSts62 : 58|1@0+ (1.0000000000,0.0000000000) [0.0000000000|1.0000000000] ""  GW
 SG_ BMS_CellEquilnSts61 : 59|1@0+ (1.0000000000,0.0000000000) [0.0000000000|1.0000000000] ""  GW
 SG_ BMS_CellEquilnSts60 : 60|1@0+ (1.0000000000,0.0000000000) [0.0000000000|1.0000000000] ""  GW
 SG_ BMS_CellEquilnSts6 : 2|1@0+ (1.0000000000,0.0000000000) [0.0000000000|1.0000000000] ""  GW
 SG_ BMS_CellEquilnSts59 : 61|1@0+ (1.0000000000,0.0000000000) [0.0000000000|1.0000000000] ""  GW
 SG_ BMS_CellEquilnSts58 : 62|1@0+ (1.0000000000,0.0000000000) [0.0000000000|1.0000000000] ""  GW
 SG_ BMS_CellEquilnSts57 : 63|1@0+ (1.0000000000,0.0000000000) [0.0000000000|1.0000000000] ""  GW
 SG_ BMS_CellEquilnSts56 : 48|1@0+ (1.0000000000,0.0000000000) [0.0000000000|1.0000000000] ""  GW
 SG_ BMS_CellEquilnSts55 : 49|1@0+ (1.0000000000,0.0000000000) [0.0000000000|1.0000000000] ""  GW
 SG_ BMS_CellEquilnSts54 : 50|1@0+ (1.0000000000,0.0000000000) [0.0000000000|1.0000000000] ""  GW
 SG_ BMS_CellEquilnSts53 : 51|1@0+ (1.0000000000,0.0000000000) [0.0000000000|1.0000000000] ""  GW
 SG_ BMS_CellEquilnSts52 : 52|1@0+ (1.0000000000,0.0000000000) [0.0000000000|1.0000000000] ""  GW
 SG_ BMS_CellEquilnSts51 : 53|1@0+ (1.0000000000,0.0000000000) [0.0000000000|1.0000000000] ""  GW
 SG_ BMS_CellEquilnSts50 : 54|1@0+ (1.0000000000,0.0000000000) [0.0000000000|1.0000000000] ""  GW
 SG_ BMS_CellEquilnSts5 : 3|1@0+ (1.0000000000,0.0000000000) [0.0000000000|1.0000000000] ""  GW
 SG_ BMS_CellEquilnSts49 : 55|1@0+ (1.0000000000,0.0000000000) [0.0000000000|1.0000000000] ""  GW
 SG_ BMS_CellEquilnSts48 : 40|1@0+ (1.0000000000,0.0000000000) [0.0000000000|1.0000000000] ""  GW
 SG_ BMS_CellEquilnSts47 : 41|1@0+ (1.0000000000,0.0000000000) [0.0000000000|1.0000000000] ""  GW
 SG_ BMS_CellEquilnSts46 : 42|1@0+ (1.0000000000,0.0000000000) [0.0000000000|1.0000000000] ""  GW
 SG_ BMS_CellEquilnSts45 : 43|1@0+ (1.0000000000,0.0000000000) [0.0000000000|1.0000000000] ""  GW
 SG_ BMS_CellEquilnSts44 : 44|1@0+ (1.0000000000,0.0000000000) [0.0000000000|1.0000000000] ""  GW
 SG_ BMS_CellEquilnSts43 : 45|1@0+ (1.0000000000,0.0000000000) [0.0000000000|1.0000000000] ""  GW
 SG_ BMS_CellEquilnSts42 : 46|1@0+ (1.0000000000,0.0000000000) [0.0000000000|1.0000000000] ""  GW
 SG_ BMS_CellEquilnSts41 : 47|1@0+ (1.0000000000,0.0000000000) [0.0000000000|1.0000000000] ""  GW
 SG_ BMS_CellEquilnSts40 : 32|1@0+ (1.0000000000,0.0000000000) [0.0000000000|1.0000000000] ""  GW
 SG_ BMS_CellEquilnSts4 : 4|1@0+ (1.0000000000,0.0000000000) [0.0000000000|1.0000000000] ""  GW
 SG_ BMS_CellEquilnSts39 : 33|1@0+ (1.0000000000,0.0000000000) [0.0000000000|1.0000000000] ""  GW
 SG_ BMS_CellEquilnSts38 : 34|1@0+ (1.0000000000,0.0000000000) [0.0000000000|1.0000000000] ""  GW
 SG_ BMS_CellEquilnSts37 : 35|1@0+ (1.0000000000,0.0000000000) [0.0000000000|1.0000000000] ""  GW
 SG_ BMS_CellEquilnSts36 : 36|1@0+ (1.0000000000,0.0000000000) [0.0000000000|1.0000000000] ""  GW
 SG_ BMS_CellEquilnSts35 : 37|1@0+ (1.0000000000,0.0000000000) [0.0000000000|1.0000000000] ""  GW
 SG_ BMS_CellEquilnSts34 : 38|1@0+ (1.0000000000,0.0000000000) [0.0000000000|1.0000000000] ""  GW
 SG_ BMS_CellEquilnSts33 : 39|1@0+ (1.0000000000,0.0000000000) [0.0000000000|1.0000000000] ""  GW
 SG_ BMS_CellEquilnSts32 : 24|1@0+ (1.0000000000,0.0000000000) [0.0000000000|1.0000000000] ""  GW
 SG_ BMS_CellEquilnSts31 : 25|1@0+ (1.0000000000,0.0000000000) [0.0000000000|1.0000000000] ""  GW
 SG_ BMS_CellEquilnSts30 : 26|1@0+ (1.0000000000,0.0000000000) [0.0000000000|1.0000000000] ""  GW
 SG_ BMS_CellEquilnSts3 : 5|1@0+ (1.0000000000,0.0000000000) [0.0000000000|1.0000000000] ""  GW
 SG_ BMS_CellEquilnSts29 : 27|1@0+ (1.0000000000,0.0000000000) [0.0000000000|1.0000000000] ""  GW
 SG_ BMS_CellEquilnSts28 : 28|1@0+ (1.0000000000,0.0000000000) [0.0000000000|1.0000000000] ""  GW
 SG_ BMS_CellEquilnSts27 : 29|1@0+ (1.0000000000,0.0000000000) [0.0000000000|1.0000000000] ""  GW
 SG_ BMS_CellEquilnSts26 : 30|1@0+ (1.0000000000,0.0000000000) [0.0000000000|1.0000000000] ""  GW
 SG_ BMS_CellEquilnSts25 : 31|1@0+ (1.0000000000,0.0000000000) [0.0000000000|1.0000000000] ""  GW
 SG_ BMS_CellEquilnSts24 : 16|1@0+ (1.0000000000,0.0000000000) [0.0000000000|1.0000000000] ""  GW
 SG_ BMS_CellEquilnSts23 : 17|1@0+ (1.0000000000,0.0000000000) [0.0000000000|1.0000000000] ""  GW
 SG_ BMS_CellEquilnSts22 : 18|1@0+ (1.0000000000,0.0000000000) [0.0000000000|1.0000000000] ""  GW
 SG_ BMS_CellEquilnSts21 : 19|1@0+ (1.0000000000,0.0000000000) [0.0000000000|1.0000000000] ""  GW
 SG_ BMS_CellEquilnSts20 : 20|1@0+ (1.0000000000,0.0000000000) [0.0000000000|1.0000000000] ""  GW
 SG_ BMS_CellEquilnSts2 : 6|1@0+ (1.0000000000,0.0000000000) [0.0000000000|1.0000000000] ""  GW
 SG_ BMS_CellEquilnSts19 : 21|1@0+ (1.0000000000,0.0000000000) [0.0000000000|1.0000000000] ""  GW
 SG_ BMS_CellEquilnSts18 : 22|1@0+ (1.0000000000,0.0000000000) [0.0000000000|1.0000000000] ""  GW
 SG_ BMS_CellEquilnSts17 : 23|1@0+ (1.0000000000,0.0000000000) [0.0000000000|1.0000000000] ""  GW
 SG_ BMS_CellEquilnSts16 : 8|1@0+ (1.0000000000,0.0000000000) [0.0000000000|1.0000000000] ""  GW
 SG_ BMS_CellEquilnSts15 : 9|1@0+ (1.0000000000,0.0000000000) [0.0000000000|1.0000000000] ""  GW
 SG_ BMS_CellEquilnSts14 : 10|1@0+ (1.0000000000,0.0000000000) [0.0000000000|1.0000000000] ""  GW
 SG_ BMS_CellEquilnSts13 : 11|1@0+ (1.0000000000,0.0000000000) [0.0000000000|1.0000000000] ""  GW
 SG_ BMS_CellEquilnSts12 : 12|1@0+ (1.0000000000,0.0000000000) [0.0000000000|1.0000000000] ""  GW
 SG_ BMS_CellEquilnSts11 : 13|1@0+ (1.0000000000,0.0000000000) [0.0000000000|1.0000000000] ""  GW
 SG_ BMS_CellEquilnSts10 : 14|1@0+ (1.0000000000,0.0000000000) [0.0000000000|1.0000000000] ""  GW
 SG_ BMS_CellEquilnSts1 : 7|1@0+ (1.0000000000,0.0000000000) [0.0000000000|1.0000000000] ""  GW

CM_ BO_ 80  " ";
CM_ SG_ 80 SRS_PassengerBuckleSwitchStatus  "For PDM is configured projects=
(if PDM is configured, logical detection with PDM is required)
0x0= [Buckled] or [Unbuckled and passenger not occupied]
0x1= [Unbuckle and passenger occupied]
0x2= Not Used
0x3= Not Used
 ";
CM_ SG_ 80 SRS_FrontPsgOccupancy  "��������������⴫�����븱�ݰ�ȫ���۴����ĳ��Ͳ������ź� ";
CM_ SG_ 80 SRS_PADIndication  "SRS_PADIndication =0=offʱ����ʻ���Ҵ�ָʾ�Ƶ�����   SRS_PADIndication =1=onʱ����ʻ���ҹر�ָʾ�Ƶ��� ";
CM_ SG_ 80 SRS_DriverBuckleSwitchStatus  "EMS��ȼ�ͳ����� ";
CM_ SG_ 80 SRS_RollingCounter_id050  "ACM����ΪATר�� ";

CM_ BO_ 384  " ";
CM_ SG_ 384 SAS_SteeringAngleSpeed  "EMS��ȼ�ͳ����� ";
CM_ SG_ 384 SAS_SteeringAngle  "EMS��ȼ�ͳ����� ";
CM_ SG_ 384 SAS_SteeringAngleValid  "EMS��ȼ�ͳ����� ";

CM_ BO_ 400  " ";
CM_ SG_ 400 BMS_MaxChrgU  " ";
CM_ SG_ 400 BMS_MinDchaIU  " ";
CM_ SG_ 400 BMS_RlyWlddErr  " ";
CM_ SG_ 400 BMS_MaxDchaPwrShoT  " ";
CM_ SG_ 400 BMS_MaxDchaIShoT  " ";
CM_ SG_ 400 BMS_MaxChrgPwrShoT  " ";
CM_ SG_ 400 BMS_MaxChrgIShoT  " ";
CM_ SG_ 400 BMS_BattUSwitch  " ";
CM_ SG_ 400 BMS_BattUCmdLoc  " ";
CM_ SG_ 400 BMS_BcuSngPackModSts  " ";
CM_ SG_ 400 BMS_SOC  "����Ҫ����SOC��ĿǰΪPCU���ͱ���SOC�����EBƽ̨��BMS��SOCӳ�䣬�����BMS���� ";
CM_ SG_ 400 BMS_PwrUpAllw  " ";
CM_ SG_ 400 BMS_OperMod  " ";
CM_ SG_ 400 BMS_OBCOperModReq  " ";
CM_ SG_ 400 BMS_InsulationSts  "���꣨1=��Ե������0=��������־ά�ֵ������������
Ŀǰ��Ե״̬��Ϊ3�֣���TBOX�����󰴹��궨���ϴ� ";
CM_ SG_ 400 BMS_HVILSts  "�Ϻ��رꡢ���꣨1=��ѹ����״̬������0=��������־ά�ֵ������������
Ŀǰ����ʹ�ø��źţ���ΪBMS����ֻ�ǵ���ڲ���ѹ����״̬�����ڿ�����PCU��TBOX���� ";
CM_ SG_ 400 BMS_HeatSftySts  " ";
CM_ SG_ 400 BMS_FltRnk  " ";
CM_ SG_ 400 BMS_CrashSts  " ";
CM_ SG_ 400 BMS_BattU  "����ʹ��0x6C2֡�е��ܵ�ѹ��ǰ�ڹ��챨�����⣬�Ʋ����ܵ�ѹ���ڣ�10ms���͵����ѹ���ڣ�1s����ƥ�䵼�£��������0x6C2�趨Ϊ1s���ڣ�����ͨ����������Ŀ����0x6C2�ܵ�ѹ���� ";
CM_ SG_ 400 BMS_BattI  "����Ҫ�����ܵ�����Ŀǰ��PCU���ͣ��ڲ�ͬ����������PCUʹ�ò�ͬ�ĵ���ֵ ";

CM_ BO_ 308  " ";
CM_ SG_ 308 GM_OperMdl  "������ѧϰΪ�������źţ��Ե����ź�Ϊ׼ ";
CM_ SG_ 308 GM_MotOilReq  "DPEU use this signal to request TCU to give the cooling oil flow ";
CM_ SG_ 308 GM_ACIAct  " ";
CM_ SG_ 308 GM_OffsAg  "����Ҫ�� ";
CM_ SG_ 308 GM_MidSide_DCUIAct  " ";

CM_ BO_ 510  " ";
CM_ SG_ 510 PCU_GM_TqNegMax  "Ť�ؿ���ģʽ ";
CM_ SG_ 510 PCU_GM_RateTqMax  " ";
CM_ SG_ 510 PCU_GM_RateSpdMax  " ";
CM_ SG_ 510 PCU_GM_MotModReq  "����ģʽ���� ";
CM_ SG_ 510 PCU_GM_TqPosMax  "Ť�ؿ���ģʽ ";

CM_ BO_ 1467  " ";
CM_ SG_ 1467 TM1_ReIPUIqCmd  "������ݷ��� ";
CM_ SG_ 1467 TM1_ReIPUIdCmd  "������ݷ��� ";
CM_ SG_ 1467 TM1_ReMotIStatr  "������ݷ��� ";
CM_ SG_ 1467 TM1_VcuIpuErrLamp  " ";
CM_ SG_ 1467 TM1_ReMotReducerRatio  " ";
CM_ SG_ 1467 TM1_RmipuReWhlActTq  "������ݷ��� ";
CM_ SG_ 1467 TM1_ReIpuTIgbtPhaW  "������ݷ��� ";
CM_ SG_ 1467 TM1_ReIpuTIgbtPhaV  "������ݷ��� ";
CM_ SG_ 1467 TM1_ReIpuTIgbtPhaU  "������ݷ��� ";
CM_ SG_ 1467 TM1_ReIpuStsDrtgTqMin  "������ݷ��� ";
CM_ SG_ 1467 TM1_ReIpuStsDrtgTqMax  "������ݷ��� ";
CM_ SG_ 1467 TM1_ReIpuCooltFlowRateEst  "������ݷ��� ";
CM_ SG_ 1467 TM1_ReIpuCoolgTEst  "������ݷ��� ";
CM_ SG_ 1467 TM1_RmipuTqLimFlgWithInpU  " ";
CM_ SG_ 1467 TM1_ReIPUUqCmd  "������ݷ��� ";
CM_ SG_ 1467 TM1_ReMotTqGb  "����RMU���� ";
CM_ SG_ 1467 TM1_ReMotRateTq  "Ԥ���ź� ";
CM_ SG_ 1467 TM1_ReIPUIGBTSwitchFreq  "������ݷ��� ";
CM_ SG_ 1467 TM1_ReIpuIqPIOut  "������ݷ��� ";
CM_ SG_ 1467 TM1_ReIpuT  "����RMU���� ";

CM_ BO_ 811  " ";
CM_ SG_ 811 DCDC_RollingCounter_2E4  " ";

CM_ BO_ 276  " ";
CM_ SG_ 276 TCU_GearShiftPosition1  "TCU receives driver demands gear from ESL and make decisition of actual drive mode based on current vehicle/transmission status.
PCU receives this signals to understand actual drive mode and estimate target gear ";

CM_ BO_ 342  " ";
CM_ SG_ 342 PCU_CoastRgnTarWhlRearQlfr  " ";

CM_ BO_ 576  " ";
CM_ SG_ 576 PCU_GearShiftStyleReq  "/(reserved for shift stytle) ";

CM_ BO_ 583  " ";
CM_ SG_ 583 APA_FunctionOnOffSts  "(���ؼ��ܷ��͸�RFBT) ";
CM_ SG_ 583 APA_CRCCheck_247  " ";
CM_ SG_ 583 APA_RollingCounter_247  "rolling counter ";
CM_ SG_ 583 APA_APAOnOff  "EMS��ȼ�ͳ����� ";
CM_ SG_ 583 APA_SteeringAngleReq  "��PAS_PSC_SetSteeringWheel
Ang ";
CM_ SG_ 583 APA_indication  "��ʾ��ǰ�Ǵ�ֱ������ƽ�в�������������ģʽ ";
CM_ SG_ 583 APA_ErrorStatus  "��PAS_PSC_Status ";
CM_ SG_ 583 APA_SteeringAngleReqProtection  "PAS_PSC_EPS_Control_Requ
est ";
CM_ SG_ 583 APA_CRCCheck_26C  "EMS��ȼ�ͳ����� ";
CM_ SG_ 583 APA_RollingCounter_26C  "EMS��ȼ�ͳ����� ";
CM_ SG_ 583 APA_AccPedShieldReq  "EMS��ȼ�ͳ����� ";
CM_ SG_ 583 APA_SlotNotice  "GW���ղ����ܣ�������ת��������ģ�鵽�ֻ�APP���� ";
CM_ SG_ 583 APA_DynamicSlotWarning  "����5֡ ";
CM_ SG_ 583 APA_EngineTrqReqEnable  "EMS��ȼ�ͳ����� ";
CM_ SG_ 583 APA_LSCAction  "EMS��ȼ�ͳ����� ";

CM_ BO_ 610  " ";

CM_ BO_ 632  " ";
CM_ SG_ 632 ESP_RollingCounter_278  "EMS��ȼ�ͳ����� ";
CM_ SG_ 632 ESP_LongAccel  "EMS��ȼ�ͳ����� ";
CM_ SG_ 632 ESP_LatAccel  "EMS��ȼ�ͳ����� ";
CM_ SG_ 632 ESP_CRCCheck_278  "EMS��ȼ�ͳ����� ";

CM_ BO_ 664  " ";
CM_ SG_ 664 PEPS_Welcomelamp  "C207���� ";

CM_ BO_ 793  " ";
CM_ SG_ 793 DCAC_DcacInpU  " ";
CM_ SG_ 793 DCAC_DcacInpI  " ";
CM_ SG_ 793 OBC_MILONReq  " ";
CM_ SG_ 793 OBC_IntT  " ";
CM_ SG_ 793 DCAC_DcacPwrCnseAct  " ";
CM_ SG_ 793 DCAC_DcacOutpU  " ";
CM_ SG_ 793 DCAC_DcacOutpPwrAvlMax  " ";
CM_ SG_ 793 DCAC_DcacOutpI  " ";
CM_ SG_ 793 DCAC_DcacOperMod  " ";
CM_ SG_ 793 DCAC_DcacFltRnk  " ";
CM_ SG_ 793 DCAC_DcacErrNr  "�ɳ������ж��� ";
CM_ SG_ 793 OBC_ObcWaterT  " ";
CM_ SG_ 793 OBC_ObcTOverWarn  " ";
CM_ SG_ 793 OBC_ObcErrNr  " ";
CM_ SG_ 793 OBC_ObcChrgInpAcU  " ";
CM_ SG_ 793 OBC_ObcChrgInpAcI  " ";
CM_ SG_ 793 OBC_ObcChrgDcU  " ";
CM_ SG_ 793 OBC_ObcChrgDcI  " ";
CM_ SG_ 793 OBC_Obc349CycCntr  "��֡���ļ���=0~14ѭ��
 ";
CM_ SG_ 793 OBC_HVPwrOnReq  " ";
CM_ SG_ 793 OBC_ObcWakeupSrc  " ";
CM_ SG_ 793 OBC_ObcS2Sts  " ";
CM_ SG_ 793 OBC_ObcMaxChrgOutpUAvl  " ";
CM_ SG_ 793 OBC_ObcMaxChrgOutpPwrAvl  " ";
CM_ SG_ 793 OBC_ObcMaxChrgOutpIAvl  " ";
CM_ SG_ 793 OBC_ObcFltRnk  " ";
CM_ SG_ 793 OBC_ObcCpValVld  " ";
CM_ SG_ 793 OBC_ObcCpVal  " ";
CM_ SG_ 793 OBC_ObcCpOutpU  " ";
CM_ SG_ 793 OBC_ObcChrgSts  " ";
CM_ SG_ 793 OBC_Obc319CycCntr  " ";
CM_ SG_ 793 OBC_ChargeCoverSts  " ";

CM_ BO_ 804  " ";
CM_ SG_ 804 TMS_BattT_out  "���Һ�� ";
CM_ SG_ 804 TMS_WaterPumpDutyCycle  " ";

CM_ BO_ 838  " ";
CM_ SG_ 838 EMS_CleaGPEUDiagnosticInfo  " ";
CM_ SG_ 838 EMS_ClearOBCDiagnosticInfo  " ";
CM_ SG_ 838 Ems_GpfSrvRgnReq  " ";
CM_ SG_ 838 Ems_EngRvsTowingReq  " ";
CM_ SG_ 838 Ems_EngFuCutOffFbd  " ";
CM_ SG_ 838 Ems_GpfActvRgnReq  " ";
CM_ SG_ 838 Ems_FltRnk  "���ڷ�������ϵͳ������� ";
CM_ SG_ 838 EMS_CleaDPEUDiagnosticInfo  " ";
CM_ SG_ 838 EMS_ThrottleRelativePosition  " ";
CM_ SG_ 838 EMS_ThrottleAbsolutePosition  " ";
CM_ SG_ 838 EMS_PwrTrainStopTime  " ";
CM_ SG_ 838 EMS_PwrTrainRunningTime  " ";
CM_ SG_ 838 EMS_ClearPCUDiagnosticInfo  " ";
CM_ SG_ 838 EMS_ClearIBCUDiagnosticInfo  " ";
CM_ SG_ 838 EMS_ClearBMSDiagnosticInfo  " ";
CM_ SG_ 838 EMS_PFCCCondition  " ";
CM_ SG_ 838 EMS_GPF_State  "GPF��Ŀ���� ";
CM_ SG_ 838 EMS_EngLoad  " ";
CM_ SG_ 838 EMS_OilPressureSts  "NE�����������������ʱ�����ź�Ĭ�Ϸ�0 ";
CM_ SG_ 838 EMS_EngOilT  "����Ҫ��תRMU ";

CM_ BO_ 870  "B_TMS_366 ";
CM_ SG_ 870 AC_CompressorStatus  "���ʽ������ѹ����ʹ�� ";
CM_ SG_ 870 AC_AC_ReqValid  "EMS��ȼ�ͳ����� ";
CM_ SG_ 870 AC_FrReqWindLevel  "EMS��ȼ�ͳ����� ";
CM_ SG_ 870 AC_FrReqWindLevelVD  "1����6����
˫ůͨ��S401���Ŀ������Ŀ��������
2��EMS��ȼ�ͳ����� ";
CM_ SG_ 870 AC_AC_Req  "EMS��ȼ�ͳ����� ";

CM_ BO_ 1302  " ";
CM_ SG_ 1302 HU_AirHumidityValid  "Ԥ���źţ��ɶ���Ժ������Ŀ�Ƿ���� ";
CM_ SG_ 1302 HU_AirHumidity  "Ԥ���źţ��ɶ���Ժ������Ŀ�Ƿ���� ";

CM_ BO_ 1304  " ";
CM_ SG_ 1304 BCM_CarMode  "��Чֵ��ΪתDBC ";

CM_ BO_ 1328  " ";
CM_ SG_ 1328 IP_FuelLevel  "GW����ת�� ";
CM_ SG_ 1328 IP_TotalOdometer  "GW����ת�� ";
CM_ SG_ 1328 IP_EngineOffTime  "This signal identifies the amount of time from IGN Off to the next Ignition cycle.  This signal is required for the Thermal Estimation algorithms to work properly.
GW����ת�� ";

CM_ BO_ 1333  " ";
CM_ SG_ 1333 BMS_SosMixSt  "�ϴ������� ";
CM_ SG_ 1333 BMS_DataUploadReq  " ";
CM_ SG_ 1333 BMS_StopCarTi  "�ϴ������� ";
CM_ SG_ 1333 BMS_CycleNr  "�ϴ������� ";
CM_ SG_ 1333 BMS_CycleSt  "�ϴ������� ";
CM_ SG_ 1333 BMS_FirstCellU  "�ϴ������� ";

CM_ BO_ 1541  " ";
CM_ SG_ 1541 BMS_SOCUproModDisp  "RMU����Ҫ�� ";
CM_ SG_ 1541 BMS_SOCOverFlgDisp  "RMU����Ҫ�� ";
CM_ SG_ 1541 BMS_SOCEKFDisp  "RMU����Ҫ�� ";
CM_ SG_ 1541 BMS_BattResidPwr  "�Ϻ��ر꣨0-999.9������0.1�� ";
CM_ SG_ 1541 BMS_BattRatedAh  " ";
CM_ SG_ 1541 BMS_SOCCntrDisp  " ";
CM_ SG_ 1541 BMS_VehCANErr  " ";
CM_ SG_ 1541 BMS_SOHBattCpDisp  "�Թ۲��ź� ";
CM_ SG_ 1541 BMS_SOCEstDisp  "�Թ۲��ź� ";
CM_ SG_ 1541 BMS_OverCrrtDischrg  " ";
CM_ SG_ 1541 BMS_OverCrrtChrg  " ";
CM_ SG_ 1541 BMS_SwVers  "���ա����쳤������Դ�������޹�˾�������汾�ƶ��淶��ִ�У�����=1020��ʾBMS����汾��ΪS1.0.2.0�� ";
CM_ SG_ 1541 BMS_SwSn  " ";
CM_ SG_ 1541 BMS_SwNm  " ";
CM_ SG_ 1541 BMS_HwVers  "���ա����쳤������Դ�������޹�˾�������汾�ƶ��淶��ִ�У�����=21��ʾBMSӲ���汾��ΪH2.1�� ";
CM_ SG_ 1541 BMS_CalDataVers  "���ա����쳤������Դ�������޹�˾�������汾�ƶ��淶��ִ�У�����=1002��ʾBMS�궨�汾��Ϊ1.0.0.2�� ";
CM_ SG_ 1541 BMS_BattSoe  " ";
CM_ SG_ 1541 BMS_SOH  " ";
CM_ SG_ 1541 BMS_SOCMin  " ";
CM_ SG_ 1541 BMS_SOCMax  " ";
CM_ SG_ 1541 BMS_RmaingCpby  " ";
CM_ SG_ 1541 BMS_ChrgnSysIAllwdMax  "������ӽ���ֱ������£���ѹ�յ��������ơ� ";
CM_ SG_ 1541 BMS_BattT_InpReq  " ";

CM_ BO_ 1590  " ";
CM_ SG_ 1590 BMS_CellEquilnSts168  " ";
CM_ SG_ 1590 BMS_CellEquilnSts167  " ";
CM_ SG_ 1590 BMS_CellEquilnSts166  " ";
CM_ SG_ 1590 BMS_CellEquilnSts165  " ";
CM_ SG_ 1590 BMS_CellEquilnSts164  " ";
CM_ SG_ 1590 BMS_CellEquilnSts163  " ";
CM_ SG_ 1590 BMS_CellEquilnSts162  " ";
CM_ SG_ 1590 BMS_CellEquilnSts161  " ";
CM_ SG_ 1590 BMS_CellEquilnSts160  " ";
CM_ SG_ 1590 BMS_CellEquilnSts159  " ";
CM_ SG_ 1590 BMS_CellEquilnSts158  " ";
CM_ SG_ 1590 BMS_CellEquilnSts157  " ";
CM_ SG_ 1590 BMS_CellEquilnSts156  " ";
CM_ SG_ 1590 BMS_CellEquilnSts155  " ";
CM_ SG_ 1590 BMS_CellEquilnSts154  " ";
CM_ SG_ 1590 BMS_CellEquilnSts153  " ";
CM_ SG_ 1590 BMS_CellEquilnSts152  " ";
CM_ SG_ 1590 BMS_CellEquilnSts151  " ";
CM_ SG_ 1590 BMS_CellEquilnSts150  " ";
CM_ SG_ 1590 BMS_CellEquilnSts149  " ";
CM_ SG_ 1590 BMS_CellEquilnSts148  " ";
CM_ SG_ 1590 BMS_CellEquilnSts147  " ";
CM_ SG_ 1590 BMS_CellEquilnSts146  " ";
CM_ SG_ 1590 BMS_CellEquilnSts145  " ";
CM_ SG_ 1590 BMS_CellEquilnSts144  " ";
CM_ SG_ 1590 BMS_CellEquilnSts143  " ";
CM_ SG_ 1590 BMS_CellEquilnSts142  " ";
CM_ SG_ 1590 BMS_CellEquilnSts141  " ";
CM_ SG_ 1590 BMS_CellEquilnSts140  " ";
CM_ SG_ 1590 BMS_CellEquilnSts139  " ";
CM_ SG_ 1590 BMS_CellEquilnSts138  " ";
CM_ SG_ 1590 BMS_CellEquilnSts137  " ";
CM_ SG_ 1590 BMS_CellEquilnSts136  " ";
CM_ SG_ 1590 BMS_CellEquilnSts135  " ";
CM_ SG_ 1590 BMS_CellEquilnSts134  " ";
CM_ SG_ 1590 BMS_CellEquilnSts133  " ";
CM_ SG_ 1590 BMS_CellEquilnSts132  " ";
CM_ SG_ 1590 BMS_CellEquilnSts131  " ";
CM_ SG_ 1590 BMS_CellEquilnSts130  " ";
CM_ SG_ 1590 BMS_CellEquilnSts129  " ";
CM_ SG_ 1590 BMS_CellEquilnSts128  " ";
CM_ SG_ 1590 BMS_CellEquilnSts127  " ";
CM_ SG_ 1590 BMS_CellEquilnSts126  " ";
CM_ SG_ 1590 BMS_CellEquilnSts125  " ";
CM_ SG_ 1590 BMS_CellEquilnSts124  " ";
CM_ SG_ 1590 BMS_CellEquilnSts123  " ";
CM_ SG_ 1590 BMS_CellEquilnSts122  " ";
CM_ SG_ 1590 BMS_CellEquilnSts121  " ";
CM_ SG_ 1590 BMS_CellEquilnSts120  " ";
CM_ SG_ 1590 BMS_CellEquilnSts119  " ";
CM_ SG_ 1590 BMS_CellEquilnSts118  " ";
CM_ SG_ 1590 BMS_CellEquilnSts117  " ";
CM_ SG_ 1590 BMS_CellEquilnSts116  " ";
CM_ SG_ 1590 BMS_CellEquilnSts115  " ";
CM_ SG_ 1590 BMS_CellEquilnSts114  " ";
CM_ SG_ 1590 BMS_CellEquilnSts113  " ";
CM_ SG_ 1590 BMS_CellEquilnSts112  " ";
CM_ SG_ 1590 BMS_CellEquilnSts111  " ";
CM_ SG_ 1590 BMS_CellEquilnSts110  " ";
CM_ SG_ 1590 BMS_CellEquilnSts109  " ";
CM_ SG_ 1590 BMS_CellEquilnSts108  " ";
CM_ SG_ 1590 BMS_CellEquilnSts107  " ";
CM_ SG_ 1590 BMS_CellEquilnSts106  " ";
CM_ SG_ 1590 BMS_CellEquilnSts105  " ";
CM_ SG_ 1590 BMS_CellEquilnSts104  " ";
CM_ SG_ 1590 BMS_CellEquilnSts103  " ";
CM_ SG_ 1590 BMS_CellEquilnSts102  " ";
CM_ SG_ 1590 BMS_CellEquilnSts101  " ";
CM_ SG_ 1590 BMS_CellEquilnSts100  " ";
CM_ SG_ 1590 BMS_CellEquilnSts99  " ";
CM_ SG_ 1590 BMS_CellEquilnSts98  " ";
CM_ SG_ 1590 BMS_CellEquilnSts97  " ";
CM_ SG_ 1590 BMS_CellEquilnSts96  " ";
CM_ SG_ 1590 BMS_CellEquilnSts95  " ";
CM_ SG_ 1590 BMS_CellEquilnSts94  " ";
CM_ SG_ 1590 BMS_CellEquilnSts93  " ";
CM_ SG_ 1590 BMS_CellEquilnSts92  " ";
CM_ SG_ 1590 BMS_CellEquilnSts91  " ";
CM_ SG_ 1590 BMS_CellEquilnSts90  " ";
CM_ SG_ 1590 BMS_CellEquilnSts89  " ";
CM_ SG_ 1590 BMS_CellEquilnSts88  " ";
CM_ SG_ 1590 BMS_CellEquilnSts87  " ";
CM_ SG_ 1590 BMS_CellEquilnSts86  " ";
CM_ SG_ 1590 BMS_CellEquilnSts85  " ";
CM_ SG_ 1590 BMS_CellEquilnSts84  " ";
CM_ SG_ 1590 BMS_CellEquilnSts83  " ";
CM_ SG_ 1590 BMS_CellEquilnSts82  " ";
CM_ SG_ 1590 BMS_CellEquilnSts81  " ";
CM_ SG_ 1590 BMS_CellEquilnSts80  " ";
CM_ SG_ 1590 BMS_CellEquilnSts79  " ";
CM_ SG_ 1590 BMS_CellEquilnSts78  " ";
CM_ SG_ 1590 BMS_CellEquilnSts77  " ";
CM_ SG_ 1590 BMS_CellEquilnSts76  " ";
CM_ SG_ 1590 BMS_CellEquilnSts75  " ";
CM_ SG_ 1590 BMS_CellEquilnSts74  " ";
CM_ SG_ 1590 BMS_CellEquilnSts73  " ";
CM_ SG_ 1590 BMS_CellEquilnSts72  " ";
CM_ SG_ 1590 BMS_CellEquilnSts71  " ";
CM_ SG_ 1590 BMS_CellEquilnSts70  " ";
CM_ SG_ 1590 BMS_CellEquilnSts69  " ";
CM_ SG_ 1590 BMS_CellEquilnSts68  " ";
CM_ SG_ 1590 BMS_CellEquilnSts67  " ";
CM_ SG_ 1590 BMS_CellEquilnSts66  " ";
CM_ SG_ 1590 BMS_CellEquilnSts65  " ";
CM_ SG_ 1590 BMS_CellEquilnSts9  " ";
CM_ SG_ 1590 BMS_CellEquilnSts8  " ";
CM_ SG_ 1590 BMS_CellEquilnSts7  " ";
CM_ SG_ 1590 BMS_CellEquilnSts64  " ";
CM_ SG_ 1590 BMS_CellEquilnSts63  " ";
CM_ SG_ 1590 BMS_CellEquilnSts62  " ";
CM_ SG_ 1590 BMS_CellEquilnSts61  " ";
CM_ SG_ 1590 BMS_CellEquilnSts60  " ";
CM_ SG_ 1590 BMS_CellEquilnSts6  " ";
CM_ SG_ 1590 BMS_CellEquilnSts59  " ";
CM_ SG_ 1590 BMS_CellEquilnSts58  " ";
CM_ SG_ 1590 BMS_CellEquilnSts57  " ";
CM_ SG_ 1590 BMS_CellEquilnSts56  " ";
CM_ SG_ 1590 BMS_CellEquilnSts55  " ";
CM_ SG_ 1590 BMS_CellEquilnSts54  " ";
CM_ SG_ 1590 BMS_CellEquilnSts53  " ";
CM_ SG_ 1590 BMS_CellEquilnSts52  " ";
CM_ SG_ 1590 BMS_CellEquilnSts51  " ";
CM_ SG_ 1590 BMS_CellEquilnSts50  " ";
CM_ SG_ 1590 BMS_CellEquilnSts5  " ";
CM_ SG_ 1590 BMS_CellEquilnSts49  " ";
CM_ SG_ 1590 BMS_CellEquilnSts48  " ";
CM_ SG_ 1590 BMS_CellEquilnSts47  " ";
CM_ SG_ 1590 BMS_CellEquilnSts46  " ";
CM_ SG_ 1590 BMS_CellEquilnSts45  " ";
CM_ SG_ 1590 BMS_CellEquilnSts44  " ";
CM_ SG_ 1590 BMS_CellEquilnSts43  " ";
CM_ SG_ 1590 BMS_CellEquilnSts42  " ";
CM_ SG_ 1590 BMS_CellEquilnSts41  " ";
CM_ SG_ 1590 BMS_CellEquilnSts40  " ";
CM_ SG_ 1590 BMS_CellEquilnSts4  " ";
CM_ SG_ 1590 BMS_CellEquilnSts39  " ";
CM_ SG_ 1590 BMS_CellEquilnSts38  " ";
CM_ SG_ 1590 BMS_CellEquilnSts37  " ";
CM_ SG_ 1590 BMS_CellEquilnSts36  " ";
CM_ SG_ 1590 BMS_CellEquilnSts35  " ";
CM_ SG_ 1590 BMS_CellEquilnSts34  " ";
CM_ SG_ 1590 BMS_CellEquilnSts33  " ";
CM_ SG_ 1590 BMS_CellEquilnSts32  " ";
CM_ SG_ 1590 BMS_CellEquilnSts31  " ";
CM_ SG_ 1590 BMS_CellEquilnSts30  " ";
CM_ SG_ 1590 BMS_CellEquilnSts3  " ";
CM_ SG_ 1590 BMS_CellEquilnSts29  " ";
CM_ SG_ 1590 BMS_CellEquilnSts28  " ";
CM_ SG_ 1590 BMS_CellEquilnSts27  " ";
CM_ SG_ 1590 BMS_CellEquilnSts26  " ";
CM_ SG_ 1590 BMS_CellEquilnSts25  " ";
CM_ SG_ 1590 BMS_CellEquilnSts24  " ";
CM_ SG_ 1590 BMS_CellEquilnSts23  " ";
CM_ SG_ 1590 BMS_CellEquilnSts22  " ";
CM_ SG_ 1590 BMS_CellEquilnSts21  " ";
CM_ SG_ 1590 BMS_CellEquilnSts20  " ";
CM_ SG_ 1590 BMS_CellEquilnSts2  " ";
CM_ SG_ 1590 BMS_CellEquilnSts19  " ";
CM_ SG_ 1590 BMS_CellEquilnSts18  " ";
CM_ SG_ 1590 BMS_CellEquilnSts17  " ";
CM_ SG_ 1590 BMS_CellEquilnSts16  " ";
CM_ SG_ 1590 BMS_CellEquilnSts15  " ";
CM_ SG_ 1590 BMS_CellEquilnSts14  " ";
CM_ SG_ 1590 BMS_CellEquilnSts13  " ";
CM_ SG_ 1590 BMS_CellEquilnSts12  " ";
CM_ SG_ 1590 BMS_CellEquilnSts11  " ";
CM_ SG_ 1590 BMS_CellEquilnSts10  " ";
CM_ SG_ 1590 BMS_CellEquilnSts1  " ";

BA_DEF_ SG_  "GenSigStartValue" INT 0 0;
BA_DEF_ SG_  "GenSigInvalidValue" STRING  ;
BA_DEF_ SG_  "GenSigCycleTime" INT 0 0;
BA_DEF_ SG_  "GenSigSendType" ENUM  "Cyclic","OnWrite","OnWriteWithRepetition","OnChange","OnChangeWithRepetition","IfActive","IfActiveWithRepetition","NoSigSendType","NotUsed","NotUsed","NotUsed","NotUsed","NotUsed";
BA_DEF_  "Baudrate" INT 0 1000000;
BA_DEF_  "BusType" STRING ;
BA_DEF_  "NmType" STRING ;
BA_DEF_  "Manufacturer" STRING ;
BA_DEF_  "VersionYear" INT 2009 2210;
BA_DEF_  "VersionNumber" INT 0 65535;
BA_DEF_  "VersionMonth" INT 0 18;
BA_DEF_  "VersionDay" INT 0 49;
BA_DEF_ BU_  "NodeLayerModules" STRING ;
BA_DEF_ BU_  "ILUsed" ENUM  "No","Yes";
BA_DEF_  "GenNWMTalkNM" STRING ;
BA_DEF_  "GenNWMGotoMode_BusSleep" STRING ;
BA_DEF_  "GenNWMGotoMode_Awake" STRING ;
BA_DEF_  "GenNWMApCanWakeUp" STRING ;
BA_DEF_  "GenNWMApCanSleep" STRING ;
BA_DEF_  "GenNWMApCanOn" STRING ;
BA_DEF_  "GenNWMApCanOff" STRING ;
BA_DEF_  "GenNWMApCanNormal" STRING ;
BA_DEF_  "GenNWMApBusSleep" STRING ;
BA_DEF_ BO_  "GenMsgSendType" ENUM  "Cyclic","Event","NotUsed","NotUsed","NotUsed","Cyclic","NotUsed","IfActive","NoMsgSendType","NotUsed";
BA_DEF_ BO_  "GenMsgILSupport" ENUM  "No","Yes";
BA_DEF_ BO_  "GenMsgCycleTime" INT 0 65535;
BA_DEF_ BO_  "CANFD_BRS" ENUM  "0","1";
BA_DEF_ BO_  "VFrameFormat" ENUM  "StandardCAN","ExtendedCAN","reserved","reserved","reserved","reserved","reserved","reserved","reserved","reserved","reserved","reserved","reserved","reserved","StandardCAN_FD","ExtendedCAN_FD";
BA_DEF_DEF_  "GenSigStartValue" 0;
BA_DEF_DEF_  "GenSigInvalidValue" "/";
BA_DEF_DEF_  "GenSigCycleTime" 0;
BA_DEF_DEF_  "GenSigSendType" "Cyclic";
BA_DEF_DEF_  "Baudrate" 500000;
BA_DEF_DEF_  "BusType" "";
BA_DEF_DEF_  "NmType" "";
BA_DEF_DEF_  "Manufacturer" "CHANA";
BA_DEF_DEF_  "VersionYear" 2010;
BA_DEF_DEF_  "VersionNumber" 0;
BA_DEF_DEF_  "VersionMonth" 11;
BA_DEF_DEF_  "VersionDay" 0;
BA_DEF_DEF_  "NodeLayerModules" "OSEKNM01.dll,CANoeILNLVector.dll";
BA_DEF_DEF_  "ILUsed" "Yes";
BA_DEF_DEF_  "GenNWMTalkNM" "TalkNM()";
BA_DEF_DEF_  "GenNWMGotoMode_BusSleep" "GotoMode_BusSleep()";
BA_DEF_DEF_  "GenNWMGotoMode_Awake" "GotoMode_Awake()";
BA_DEF_DEF_  "GenNWMApCanWakeUp" "apCanWakeUp()";
BA_DEF_DEF_  "GenNWMApCanSleep" "apCanSleep()";
BA_DEF_DEF_  "GenNWMApCanOn" "apCanOn()";
BA_DEF_DEF_  "GenNWMApCanOff" "apCanOff()";
BA_DEF_DEF_  "GenNWMApCanNormal" "apCanNormal()";
BA_DEF_DEF_  "GenNWMApBusSleep" "apBusSleep()";
BA_DEF_DEF_  "GenMsgSendType" "NoMsgSendType";
BA_DEF_DEF_  "GenMsgILSupport" "Yes";
BA_DEF_DEF_  "GenMsgCycleTime" 0;
BA_DEF_DEF_  "CANFD_BRS" "1";
BA_DEF_DEF_  "VFrameFormat" "StandardCAN";

BA_ "VersionYear" 2023;
BA_ "VersionNumber" 11;
BA_ "VersionDay" 10;
BA_ "Baudrate" 2000000;
BA_ "NmType" "OSEK";
BA_ "BusType" "CAN FD";
BA_ "GenMsgCycleTime" BO_ 80 500;
BA_ "GenMsgSendType" BO_ 80 0;
BA_ "VFrameFormat" BO_ 80 14;
BA_ "GenMsgCycleTime" BO_ 384 10;
BA_ "GenMsgSendType" BO_ 384 0;
BA_ "VFrameFormat" BO_ 384 14;
BA_ "GenMsgCycleTime" BO_ 400 10;
BA_ "GenMsgSendType" BO_ 400 0;
BA_ "VFrameFormat" BO_ 400 14;
BA_ "GenMsgCycleTime" BO_ 308 10;
BA_ "GenMsgSendType" BO_ 308 0;
BA_ "VFrameFormat" BO_ 308 14;
BA_ "GenMsgCycleTime" BO_ 510 10;
BA_ "GenMsgSendType" BO_ 510 0;
BA_ "VFrameFormat" BO_ 510 14;
BA_ "GenMsgCycleTime" BO_ 1467 500;
BA_ "GenMsgSendType" BO_ 1467 0;
BA_ "VFrameFormat" BO_ 1467 14;
BA_ "GenMsgCycleTime" BO_ 811 100;
BA_ "GenMsgSendType" BO_ 811 0;
BA_ "VFrameFormat" BO_ 811 14;
BA_ "GenMsgCycleTime" BO_ 276 10;
BA_ "GenMsgSendType" BO_ 276 0;
BA_ "VFrameFormat" BO_ 276 14;
BA_ "GenMsgCycleTime" BO_ 342 20;
BA_ "GenMsgSendType" BO_ 342 0;
BA_ "VFrameFormat" BO_ 342 14;
BA_ "GenMsgCycleTime" BO_ 576 20;
BA_ "GenMsgSendType" BO_ 576 0;
BA_ "VFrameFormat" BO_ 576 14;
BA_ "GenMsgCycleTime" BO_ 583 20;
BA_ "GenMsgSendType" BO_ 583 0;
BA_ "VFrameFormat" BO_ 583 14;
BA_ "GenMsgCycleTime" BO_ 610 40;
BA_ "GenMsgSendType" BO_ 610 0;
BA_ "VFrameFormat" BO_ 610 14;
BA_ "GenMsgCycleTime" BO_ 632 20;
BA_ "GenMsgSendType" BO_ 632 0;
BA_ "VFrameFormat" BO_ 632 14;
BA_ "GenMsgCycleTime" BO_ 664 40;
BA_ "GenMsgSendType" BO_ 664 0;
BA_ "VFrameFormat" BO_ 664 14;
BA_ "GenMsgCycleTime" BO_ 793 100;
BA_ "GenMsgSendType" BO_ 793 0;
BA_ "VFrameFormat" BO_ 793 14;
BA_ "GenMsgCycleTime" BO_ 804 100;
BA_ "GenMsgSendType" BO_ 804 0;
BA_ "VFrameFormat" BO_ 804 14;
BA_ "GenMsgCycleTime" BO_ 838 100;
BA_ "GenMsgSendType" BO_ 838 0;
BA_ "VFrameFormat" BO_ 838 14;
BA_ "GenMsgCycleTime" BO_ 870 100;
BA_ "GenMsgSendType" BO_ 870 0;
BA_ "VFrameFormat" BO_ 870 14;
BA_ "GenMsgCycleTime" BO_ 1302 1000;
BA_ "GenMsgSendType" BO_ 1302 0;
BA_ "VFrameFormat" BO_ 1302 14;
BA_ "GenMsgCycleTime" BO_ 1304 500;
BA_ "GenMsgSendType" BO_ 1304 0;
BA_ "VFrameFormat" BO_ 1304 14;
BA_ "GenMsgCycleTime" BO_ 1328 500;
BA_ "GenMsgSendType" BO_ 1328 0;
BA_ "VFrameFormat" BO_ 1328 14;
BA_ "GenMsgCycleTime" BO_ 1333 50;
BA_ "GenMsgSendType" BO_ 1333 0;
BA_ "VFrameFormat" BO_ 1333 14;
BA_ "GenMsgCycleTime" BO_ 1541 1000;
BA_ "GenMsgSendType" BO_ 1541 0;
BA_ "VFrameFormat" BO_ 1541 14;
BA_ "GenMsgCycleTime" BO_ 1590 1000;
BA_ "GenMsgSendType" BO_ 1590 0;
BA_ "VFrameFormat" BO_ 1590 14;
BA_ "GenSigCycleTime" SG_ 80 SRS_PassengerBuckleSwitchStatus 500;
BA_ "GenSigCycleTime" SG_ 80 SRS_RightRearBuckleSwitchSts 500;
BA_ "GenSigCycleTime" SG_ 80 SRS_MiddleRearBuckleSwitchSts 500;
BA_ "GenSigCycleTime" SG_ 80 SRS_LeftRearBuckleSwitchSts 500;
BA_ "GenSigCycleTime" SG_ 80 SRS_FrontPsgOccupancy 500;
BA_ "GenSigCycleTime" SG_ 80 SRS_PADIndication 500;
BA_ "GenSigCycleTime" SG_ 80 SRS_WarningLampStatus 500;
BA_ "GenSigCycleTime" SG_ 80 SRS_DriverBuckleSwitchStatus 500;
BA_ "GenSigCycleTime" SG_ 80 SRS_RollingCounter_id050 500;
BA_ "GenSigCycleTime" SG_ 80 SRS_CrashOutputStatusCheckSum 500;
BA_ "GenSigCycleTime" SG_ 80 SRS_CrashOutputStatus 500;

BA_ "GenSigCycleTime" SG_ 384 SAS_CRCCheck 10;
BA_ "GenSigCycleTime" SG_ 384 SAS_RollingCounter 10;
BA_ "GenSigCycleTime" SG_ 384 SAS_SteeringAngleSpeed 10;
BA_ "GenSigInvalidValue" SG_ 384 SAS_SteeringAngleSpeed "255";
BA_ "GenSigCycleTime" SG_ 384 SAS_SteeringAngle 10;
BA_ "GenSigInvalidValue" SG_ 384 SAS_SteeringAngle "32767";
BA_ "GenSigCycleTime" SG_ 384 SAS_SASFailure 10;
BA_ "GenSigInvalidValue" SG_ 384 SAS_SASFailure "1";
BA_ "GenSigCycleTime" SG_ 384 SAS_Calibrated 10;
BA_ "GenSigCycleTime" SG_ 384 SAS_SteeringAngleValid 10;
BA_ "GenSigInvalidValue" SG_ 384 SAS_SteeringAngleValid "1";

BA_ "GenSigCycleTime" SG_ 400 BMS_PlsHeatTiRem 10;
BA_ "GenSigInvalidValue" SG_ 400 BMS_PlsHeatTiRem "2047";
BA_ "GenSigCycleTime" SG_ 400 BMS_BattPlsHeagStsFb 10;
BA_ "GenSigInvalidValue" SG_ 400 BMS_BattPlsHeagStsFb "NA";
BA_ "GenSigCycleTime" SG_ 400 BMS_MaxChrgU 10;
BA_ "GenSigInvalidValue" SG_ 400 BMS_MaxChrgU "511";
BA_ "GenSigCycleTime" SG_ 400 BMS_MinDchaIU 10;
BA_ "GenSigInvalidValue" SG_ 400 BMS_MinDchaIU "511";
BA_ "GenSigCycleTime" SG_ 400 BMS_BcuCycWakeupTimer 10;
BA_ "GenSigInvalidValue" SG_ 400 BMS_BcuCycWakeupTimer "0";
BA_ "GenSigCycleTime" SG_ 400 BMS_BcuDataUploadReq 10;
BA_ "GenSigInvalidValue" SG_ 400 BMS_BcuDataUploadReq "0";
BA_ "GenSigCycleTime" SG_ 400 BMS_BattInrHeatMode 10;
BA_ "GenSigInvalidValue" SG_ 400 BMS_BattInrHeatMode "0";
BA_ "GenSigCycleTime" SG_ 400 BMS_BattPlsHeatgGearReq 10;
BA_ "GenSigCycleTime" SG_ 400 BMS_RollingCounter_190 10;
BA_ "GenSigCycleTime" SG_ 400 BMS_CRCCheck_190 10;
BA_ "GenSigCycleTime" SG_ 400 BMS_RlyWlddErr 10;
BA_ "GenSigCycleTime" SG_ 400 BMS_MaxDchaPwrShoT 10;
BA_ "GenSigInvalidValue" SG_ 400 BMS_MaxDchaPwrShoT "1023";
BA_ "GenSigCycleTime" SG_ 400 BMS_MaxDchaIShoT 10;
BA_ "GenSigInvalidValue" SG_ 400 BMS_MaxDchaIShoT "1023";
BA_ "GenSigCycleTime" SG_ 400 BMS_MaxChrgPwrShoT 10;
BA_ "GenSigInvalidValue" SG_ 400 BMS_MaxChrgPwrShoT "1023";
BA_ "GenSigCycleTime" SG_ 400 BMS_MaxChrgIShoT 10;
BA_ "GenSigInvalidValue" SG_ 400 BMS_MaxChrgIShoT "1023";
BA_ "GenSigCycleTime" SG_ 400 BMS_BattUSwitch 10;
BA_ "GenSigInvalidValue" SG_ 400 BMS_BattUSwitch "511";
BA_ "GenSigCycleTime" SG_ 400 BMS_BattUCmdLoc 10;
BA_ "GenSigCycleTime" SG_ 400 BMS_BcuSngPackModSts 10;
BA_ "GenSigInvalidValue" SG_ 400 BMS_BcuSngPackModSts "NA";
BA_ "GenSigCycleTime" SG_ 400 BMS_SOC 10;
BA_ "GenSigInvalidValue" SG_ 400 BMS_SOC "1023";
BA_ "GenSigCycleTime" SG_ 400 BMS_PwrUpAllw 10;
BA_ "GenSigCycleTime" SG_ 400 BMS_OperMod 10;
BA_ "GenSigCycleTime" SG_ 400 BMS_OBCOperModReq 10;
BA_ "GenSigCycleTime" SG_ 400 BMS_InsulationSts 10;
BA_ "GenSigCycleTime" SG_ 400 BMS_HVILSts 10;
BA_ "GenSigCycleTime" SG_ 400 BMS_HeatSftySts 10;
BA_ "GenSigCycleTime" SG_ 400 BMS_FltRnk 10;
BA_ "GenSigCycleTime" SG_ 400 BMS_CrashSts 10;
BA_ "GenSigCycleTime" SG_ 400 BMS_BattU 10;
BA_ "GenSigInvalidValue" SG_ 400 BMS_BattU "8191";
BA_ "GenSigCycleTime" SG_ 400 BMS_BattI 10;
BA_ "GenSigStartValue" SG_ 400 BMS_BattI 6000.000000;
BA_ "GenSigInvalidValue" SG_ 400 BMS_BattI "16383";

BA_ "GenSigCycleTime" SG_ 308 GM_MotorStart 10;
BA_ "GenSigCycleTime" SG_ 308 GM_KeyOn 10;
BA_ "GenSigCycleTime" SG_ 308 GM_ReolverSingalVp 10;
BA_ "GenSigInvalidValue" SG_ 308 GM_ReolverSingalVp "255";
BA_ "GenSigCycleTime" SG_ 308 GM_IqFeedBack 10;
BA_ "GenSigInvalidValue" SG_ 308 GM_IqFeedBack "255";
BA_ "GenSigCycleTime" SG_ 308 GM_IdFeedBack 10;
BA_ "GenSigInvalidValue" SG_ 308 GM_IdFeedBack "255";
BA_ "GenSigCycleTime" SG_ 308 GM_IqCmd 10;
BA_ "GenSigInvalidValue" SG_ 308 GM_IqCmd "255";
BA_ "GenSigCycleTime" SG_ 308 GM_IdCmd 10;
BA_ "GenSigInvalidValue" SG_ 308 GM_IdCmd "255";
BA_ "GenSigCycleTime" SG_ 308 GM_IvtINTCT 10;
BA_ "GenSigCycleTime" SG_ 308 GM_IvtwaterReq 10;
BA_ "GenSigInvalidValue" SG_ 308 GM_IvtwaterReq "255";
BA_ "GenSigCycleTime" SG_ 308 GM_MidSide_DCUUAct 10;
BA_ "GenSigCycleTime" SG_ 308 GM_MotSpdVld 10;
BA_ "GenSigCycleTime" SG_ 308 GM_MotSpd 10;
BA_ "GenSigStartValue" SG_ 308 GM_MotSpd 12000.000000;
BA_ "GenSigInvalidValue" SG_ 308 GM_MotSpd "32767";
BA_ "GenSigCycleTime" SG_ 308 GM_TorsionalVibrationTqVld 10;
BA_ "GenSigCycleTime" SG_ 308 GM_TorsionalVibrationTq 10;
BA_ "GenSigStartValue" SG_ 308 GM_TorsionalVibrationTq 128.000000;
BA_ "GenSigInvalidValue" SG_ 308 GM_TorsionalVibrationTq "255";
BA_ "GenSigCycleTime" SG_ 308 GM_MotTqRealVld 10;
BA_ "GenSigCycleTime" SG_ 308 GM_MotTqReal 10;
BA_ "GenSigStartValue" SG_ 308 GM_MotTqReal 4000.000000;
BA_ "GenSigInvalidValue" SG_ 308 GM_MotTqReal "8191";
BA_ "GenSigCycleTime" SG_ 308 GM_IvtTOver 10;
BA_ "GenSigCycleTime" SG_ 308 GM_OperMdl 10;
BA_ "GenSigCycleTime" SG_ 308 GM_MotTOver 10;
BA_ "GenSigCycleTime" SG_ 308 GM_IvtCooltT 10;
BA_ "GenSigCycleTime" SG_ 308 GM_MotSts 10;
BA_ "GenSigStartValue" SG_ 308 GM_MotSts 2.000000;
BA_ "GenSigCycleTime" SG_ 308 GM_MotNr 10;
BA_ "GenSigInvalidValue" SG_ 308 GM_MotNr "3";
BA_ "GenSigCycleTime" SG_ 308 GM_ErrAmnt 10;
BA_ "GenSigInvalidValue" SG_ 308 GM_ErrAmnt "15";
BA_ "GenSigCycleTime" SG_ 308 GM_BattSide_DCUIAct 10;
BA_ "GenSigInvalidValue" SG_ 308 GM_BattSide_DCUIAct "1023";
BA_ "GenSigCycleTime" SG_ 308 GM_MotwaterReq 10;
BA_ "GenSigInvalidValue" SG_ 308 GM_MotwaterReq "255";
BA_ "GenSigCycleTime" SG_ 308 GM_MotOilReq 10;
BA_ "GenSigInvalidValue" SG_ 308 GM_MotOilReq "63";
BA_ "GenSigCycleTime" SG_ 308 GM_FltCode 10;
BA_ "GenSigInvalidValue" SG_ 308 GM_FltCode "511";
BA_ "GenSigCycleTime" SG_ 308 GM_ACIAct 10;
BA_ "GenSigStartValue" SG_ 308 GM_ACIAct 400.000000;
BA_ "GenSigInvalidValue" SG_ 308 GM_ACIAct "1023";
BA_ "GenSigCycleTime" SG_ 308 GM_MotStatorT 10;
BA_ "GenSigCycleTime" SG_ 308 GM_MotRotorT 10;
BA_ "GenSigCycleTime" SG_ 308 GM_IvtIGBTMdlT 10;
BA_ "GenSigCycleTime" SG_ 308 DPEU_RollingCounter_134 10;
BA_ "GenSigCycleTime" SG_ 308 DPEU_CRCCheck_134 10;
BA_ "GenSigCycleTime" SG_ 308 GM_Resolvercalibrstatus 10;
BA_ "GenSigCycleTime" SG_ 308 GM_OffsAg 10;
BA_ "GenSigInvalidValue" SG_ 308 GM_OffsAg "3601";
BA_ "GenSigCycleTime" SG_ 308 GM_MinTqShortTerm 10;
BA_ "GenSigStartValue" SG_ 308 GM_MinTqShortTerm 500.000000;
BA_ "GenSigCycleTime" SG_ 308 GM_MinTqLongTerm 10;
BA_ "GenSigStartValue" SG_ 308 GM_MinTqLongTerm 500.000000;
BA_ "GenSigInvalidValue" SG_ 308 GM_MinTqLongTerm "511";
BA_ "GenSigCycleTime" SG_ 308 GM_MaxTqShortTerm 10;
BA_ "GenSigCycleTime" SG_ 308 GM_MaxTqLongTerm 10;
BA_ "GenSigInvalidValue" SG_ 308 GM_MaxTqLongTerm "511";
BA_ "GenSigCycleTime" SG_ 308 GM_FltRnk 10;
BA_ "GenSigCycleTime" SG_ 308 GM_ASCflag 10;
BA_ "GenSigCycleTime" SG_ 308 GM_MidSide_DCUIAct 10;
BA_ "GenSigStartValue" SG_ 308 GM_MidSide_DCUIAct 500.000000;
BA_ "GenSigInvalidValue" SG_ 308 GM_MidSide_DCUIAct "1023";

BA_ "GenSigCycleTime" SG_ 510 PCU_CRCCheck_1FE_2 10;
BA_ "GenSigCycleTime" SG_ 510 PCU_RollingCounter_1FE_2 10;
BA_ "GenSigCycleTime" SG_ 510 PCU_CRCCheck_1FE_1 10;
BA_ "GenSigCycleTime" SG_ 510 PCU_RollingCounter_1FE_1 10;
BA_ "GenSigCycleTime" SG_ 510 PCU_CRCCheck_1FE_0 10;
BA_ "GenSigCycleTime" SG_ 510 PCU_RollingCounter_1FE_0 10;
BA_ "GenSigCycleTime" SG_ 510 PCU_GMCurrentCmd 10;
BA_ "GenSigStartValue" SG_ 510 PCU_GMCurrentCmd 1000.000000;
BA_ "GenSigInvalidValue" SG_ 510 PCU_GMCurrentCmd "2047";
BA_ "GenSigCycleTime" SG_ 510 PCU_GMTqRgnIMax 10;
BA_ "GenSigCycleTime" SG_ 510 PCU_GMTqImax 10;
BA_ "GenSigCycleTime" SG_ 510 PCU_RollingCounter_1FE 10;
BA_ "GenSigCycleTime" SG_ 510 PCU_CRCCheck_1FE 10;
BA_ "GenSigCycleTime" SG_ 510 PCU_GM_TqNegMax 10;
BA_ "GenSigStartValue" SG_ 510 PCU_GM_TqNegMax 511.000000;
BA_ "GenSigInvalidValue" SG_ 510 PCU_GM_TqNegMax "1023";
BA_ "GenSigCycleTime" SG_ 510 PCU_GM_RateTqMax 10;
BA_ "GenSigStartValue" SG_ 510 PCU_GM_RateTqMax 100.000000;
BA_ "GenSigInvalidValue" SG_ 510 PCU_GM_RateTqMax "255";
BA_ "GenSigCycleTime" SG_ 510 PCU_GM_RateSpdMax 10;
BA_ "GenSigStartValue" SG_ 510 PCU_GM_RateSpdMax 200.000000;
BA_ "GenSigInvalidValue" SG_ 510 PCU_GM_RateSpdMax "511";
BA_ "GenSigCycleTime" SG_ 510 PCU_GM_MotModReq 10;
BA_ "GenSigCycleTime" SG_ 510 PCU_GM_TqPosMax 10;
BA_ "GenSigStartValue" SG_ 510 PCU_GM_TqPosMax 511.000000;
BA_ "GenSigInvalidValue" SG_ 510 PCU_GM_TqPosMax "1023";
BA_ "GenSigCycleTime" SG_ 510 PCU_GM_SurgeDamperTqMin 10;
BA_ "GenSigCycleTime" SG_ 510 PCU_GM_SurgeDamperTqMax 10;
BA_ "GenSigCycleTime" SG_ 510 PCU_GM_SurgeDamperEna 10;
BA_ "GenSigCycleTime" SG_ 510 PCU_GM_ResoCaliAllow 10;
BA_ "GenSigInvalidValue" SG_ 510 PCU_GM_ResoCaliAllow "3";
BA_ "GenSigCycleTime" SG_ 510 PCU_GM_nCtlExtCfg 10;
BA_ "GenSigCycleTime" SG_ 510 PCU_GM_MotTqReq 10;
BA_ "GenSigStartValue" SG_ 510 PCU_GM_MotTqReq 4000.000000;
BA_ "GenSigCycleTime" SG_ 510 PCU_GM_MotSpdReq 10;
BA_ "GenSigStartValue" SG_ 510 PCU_GM_MotSpdReq 12000.000000;

BA_ "GenSigCycleTime" SG_ 1467 TM1_ReMotActHeaPwr 500;
BA_ "GenSigInvalidValue" SG_ 1467 TM1_ReMotActHeaPwr "255";
BA_ "GenSigCycleTime" SG_ 1467 TM1_ReMotWasHeaPwr 500;
BA_ "GenSigInvalidValue" SG_ 1467 TM1_ReMotWasHeaPwr "255";
BA_ "GenSigCycleTime" SG_ 1467 TM1_ReIPUIqCmd 500;
BA_ "GenSigStartValue" SG_ 1467 TM1_ReIPUIqCmd 1000.000000;
BA_ "GenSigInvalidValue" SG_ 1467 TM1_ReIPUIqCmd "NA";
BA_ "GenSigCycleTime" SG_ 1467 TM1_ReIPUIdCmd 500;
BA_ "GenSigStartValue" SG_ 1467 TM1_ReIPUIdCmd 1000.000000;
BA_ "GenSigInvalidValue" SG_ 1467 TM1_ReIPUIdCmd "NA";
BA_ "GenSigCycleTime" SG_ 1467 TM1_ReMotIStatr 500;
BA_ "GenSigStartValue" SG_ 1467 TM1_ReMotIStatr 1000.000000;
BA_ "GenSigInvalidValue" SG_ 1467 TM1_ReMotIStatr "NA";
BA_ "GenSigCycleTime" SG_ 1467 TM1_VcuIpuErrLamp 500;
BA_ "GenSigCycleTime" SG_ 1467 TM1_ReMotReducerRatio 500;
BA_ "GenSigStartValue" SG_ 1467 TM1_ReMotReducerRatio 11265.000000;
BA_ "GenSigInvalidValue" SG_ 1467 TM1_ReMotReducerRatio "11265";
BA_ "GenSigCycleTime" SG_ 1467 TM1_RmipuReWhlActTq 500;
BA_ "GenSigInvalidValue" SG_ 1467 TM1_RmipuReWhlActTq "NA";
BA_ "GenSigCycleTime" SG_ 1467 TM1_ReIpuTIgbtPhaW 500;
BA_ "GenSigStartValue" SG_ 1467 TM1_ReIpuTIgbtPhaW 70.000000;
BA_ "GenSigInvalidValue" SG_ 1467 TM1_ReIpuTIgbtPhaW "255";
BA_ "GenSigCycleTime" SG_ 1467 TM1_ReIpuTIgbtPhaV 500;
BA_ "GenSigStartValue" SG_ 1467 TM1_ReIpuTIgbtPhaV 70.000000;
BA_ "GenSigInvalidValue" SG_ 1467 TM1_ReIpuTIgbtPhaV "255";
BA_ "GenSigCycleTime" SG_ 1467 TM1_ReIpuTIgbtPhaU 500;
BA_ "GenSigStartValue" SG_ 1467 TM1_ReIpuTIgbtPhaU 70.000000;
BA_ "GenSigInvalidValue" SG_ 1467 TM1_ReIpuTIgbtPhaU "255";
BA_ "GenSigCycleTime" SG_ 1467 TM1_ReIpuStsDrtgTqMin 500;
BA_ "GenSigInvalidValue" SG_ 1467 TM1_ReIpuStsDrtgTqMin "NA";
BA_ "GenSigCycleTime" SG_ 1467 TM1_ReIpuStsDrtgTqMax 500;
BA_ "GenSigInvalidValue" SG_ 1467 TM1_ReIpuStsDrtgTqMax "NA";
BA_ "GenSigCycleTime" SG_ 1467 TM1_ReIpuCooltFlowRateEst 500;
BA_ "GenSigInvalidValue" SG_ 1467 TM1_ReIpuCooltFlowRateEst "15";
BA_ "GenSigCycleTime" SG_ 1467 TM1_ReIpuCoolgTEst 500;
BA_ "GenSigStartValue" SG_ 1467 TM1_ReIpuCoolgTEst 70.000000;
BA_ "GenSigInvalidValue" SG_ 1467 TM1_ReIpuCoolgTEst "255";
BA_ "GenSigCycleTime" SG_ 1467 TM1_RmipuTqLimFlgWithInpU 500;
BA_ "GenSigInvalidValue" SG_ 1467 TM1_RmipuTqLimFlgWithInpU "NA";
BA_ "GenSigCycleTime" SG_ 1467 TM1_ReIPUUqCmd 500;
BA_ "GenSigStartValue" SG_ 1467 TM1_ReIPUUqCmd 1000.000000;
BA_ "GenSigInvalidValue" SG_ 1467 TM1_ReIPUUqCmd "NA";
BA_ "GenSigCycleTime" SG_ 1467 TM1_ReMotTqGb 500;
BA_ "GenSigStartValue" SG_ 1467 TM1_ReMotTqGb 20000.000000;
BA_ "GenSigInvalidValue" SG_ 1467 TM1_ReMotTqGb "65535";
BA_ "GenSigCycleTime" SG_ 1467 TM1_ReMotRateTq 500;
BA_ "GenSigInvalidValue" SG_ 1467 TM1_ReMotRateTq "NA";
BA_ "GenSigCycleTime" SG_ 1467 TM1_ReIPUIGBTSwitchFreq 500;
BA_ "GenSigInvalidValue" SG_ 1467 TM1_ReIPUIGBTSwitchFreq "255";
BA_ "GenSigCycleTime" SG_ 1467 TM1_ReIpuIqPIOut 500;
BA_ "GenSigStartValue" SG_ 1467 TM1_ReIpuIqPIOut 100.000000;
BA_ "GenSigInvalidValue" SG_ 1467 TM1_ReIpuIqPIOut "255";
BA_ "GenSigCycleTime" SG_ 1467 TM1_ReIpuT 500;
BA_ "GenSigStartValue" SG_ 1467 TM1_ReIpuT 60.000000;
BA_ "GenSigInvalidValue" SG_ 1467 TM1_ReIpuT "255";
BA_ "GenSigCycleTime" SG_ 1467 TM1_MotSts 500;
BA_ "GenSigStartValue" SG_ 1467 TM1_MotSts 2.000000;
BA_ "GenSigCycleTime" SG_ 1467 TM1_MotNr 500;
BA_ "GenSigInvalidValue" SG_ 1467 TM1_MotNr "3";
BA_ "GenSigCycleTime" SG_ 1467 TM1_ErrAmnt 500;
BA_ "GenSigInvalidValue" SG_ 1467 TM1_ErrAmnt "15";

BA_ "GenSigCycleTime" SG_ 811 OBC_RollingCounter_32B 100;
BA_ "GenSigCycleTime" SG_ 811 OBC_CRCCheck_32B 100;
BA_ "GenSigCycleTime" SG_ 811 DCDC_ResetSts 100;
BA_ "GenSigInvalidValue" SG_ 811 DCDC_ResetSts "7";
BA_ "GenSigCycleTime" SG_ 811 DCDCAvlOutpPwr 100;
BA_ "GenSigInvalidValue" SG_ 811 DCDCAvlOutpPwr "4095";
BA_ "GenSigCycleTime" SG_ 811 DCDC_Sts 100;
BA_ "GenSigCycleTime" SG_ 811 DCDC_RollingCounter_31D 100;
BA_ "GenSigCycleTime" SG_ 811 DCDC_PCBT 100;
BA_ "GenSigStartValue" SG_ 811 DCDC_PCBT 40.000000;
BA_ "GenSigInvalidValue" SG_ 811 DCDC_PCBT "255";
BA_ "GenSigCycleTime" SG_ 811 DCDC_OverT 100;
BA_ "GenSigCycleTime" SG_ 811 DCDC_FltRnk 100;
BA_ "GenSigCycleTime" SG_ 811 DCDC_FltCode 100;
BA_ "GenSigCycleTime" SG_ 811 DCDC_CRCCheck_31D 100;
BA_ "GenSigCycleTime" SG_ 811 DCDC_Utlzt 100;
BA_ "GenSigCycleTime" SG_ 811 DCDC_ULV 100;
BA_ "GenSigCycleTime" SG_ 811 DCDC_UHV 100;
BA_ "GenSigCycleTime" SG_ 811 DCDC_RollingCounter_2E4 100;
BA_ "GenSigCycleTime" SG_ 811 DCDC_CRCCheck_2E4 100;
BA_ "GenSigCycleTime" SG_ 811 DCDC_StsWarning 100;
BA_ "GenSigCycleTime" SG_ 811 DCDC_OperMod 100;
BA_ "GenSigCycleTime" SG_ 811 DCDC_ILV 100;
BA_ "GenSigCycleTime" SG_ 811 DCDC_IHV 100;

BA_ "GenSigCycleTime" SG_ 276 TCU_ShiftPostionValid1 10;
BA_ "GenSigInvalidValue" SG_ 276 TCU_ShiftPostionValid1 "1";
BA_ "GenSigCycleTime" SG_ 276 TCU_GearShiftPosition1 10;
BA_ "GenSigStartValue" SG_ 276 TCU_GearShiftPosition1 13.000000;
BA_ "GenSigInvalidValue" SG_ 276 TCU_GearShiftPosition1 "15";
BA_ "GenSigCycleTime" SG_ 276 PCU_TM1DynTqUnloadAllwd 10;
BA_ "GenSigCycleTime" SG_ 276 PCU_CRCCheck_114 10;
BA_ "GenSigCycleTime" SG_ 276 PCU_RollingCounter_114 10;
BA_ "GenSigCycleTime" SG_ 276 PCU_CRCCheck_114_2 10;
BA_ "GenSigCycleTime" SG_ 276 PCU_RollingCounter_114_2 10;
BA_ "GenSigCycleTime" SG_ 276 PCU_CRCCheck_114_1 10;
BA_ "GenSigCycleTime" SG_ 276 PCU_RollingCounter_114_1 10;
BA_ "GenSigCycleTime" SG_ 276 PCU_TM1CurrentCmd 10;
BA_ "GenSigStartValue" SG_ 276 PCU_TM1CurrentCmd 1000.000000;
BA_ "GenSigInvalidValue" SG_ 276 PCU_TM1CurrentCmd "2047";
BA_ "GenSigCycleTime" SG_ 276 PCU_TM1TqRgnIMax 10;
BA_ "GenSigCycleTime" SG_ 276 PCU_TM1TqImax 10;
BA_ "GenSigCycleTime" SG_ 276 PCU_TM1_SurgeDamperTqMin 10;
BA_ "GenSigCycleTime" SG_ 276 PCU_TM1_SurgeDamperTqMax 10;
BA_ "GenSigCycleTime" SG_ 276 PCU_TM1_MotTqPosMax 10;
BA_ "GenSigCycleTime" SG_ 276 PCU_TM1_MotTqNegMax 10;
BA_ "GenSigCycleTime" SG_ 276 PCU_TM1_MotRateTqMax 10;
BA_ "GenSigCycleTime" SG_ 276 PCU_CRCCheck_114_0 10;
BA_ "GenSigCycleTime" SG_ 276 PCU_RollingCounter_114_0 10;
BA_ "GenSigCycleTime" SG_ 276 PCU_TM1_SurgeDamperEna 10;
BA_ "GenSigCycleTime" SG_ 276 PCU_TM1_ResoCaliAllow 10;
BA_ "GenSigInvalidValue" SG_ 276 PCU_TM1_ResoCaliAllow "3";
BA_ "GenSigCycleTime" SG_ 276 PCU_TM1_nCtlExtCfg 10;
BA_ "GenSigCycleTime" SG_ 276 PCU_TM1_MotTqReq 10;
BA_ "GenSigStartValue" SG_ 276 PCU_TM1_MotTqReq 8000.000000;
BA_ "GenSigCycleTime" SG_ 276 PCU_TM1_MotSpdReq 10;
BA_ "GenSigStartValue" SG_ 276 PCU_TM1_MotSpdReq 12000.000000;
BA_ "GenSigCycleTime" SG_ 276 PCU_TM1_MotModReq 10;

BA_ "GenSigCycleTime" SG_ 342 PCU_CoastRgnTarWhlRearQlfr 20;
BA_ "GenSigCycleTime" SG_ 342 PCU_CoastRgnTarWhlRear 20;
BA_ "GenSigCycleTime" SG_ 342 TCU_K3_CluClsActiveVld 20;
BA_ "GenSigCycleTime" SG_ 342 TCU_K3_CluClsActive 20;
BA_ "GenSigCycleTime" SG_ 342 PCU_CoastRgnTarWhlFrntQlfr 20;
BA_ "GenSigCycleTime" SG_ 342 PCU_CoastRgnTarWhlFrnt 20;

BA_ "GenSigCycleTime" SG_ 576 PCU_PTMode 20;
BA_ "GenSigInvalidValue" SG_ 576 PCU_PTMode "0";
BA_ "GenSigCycleTime" SG_ 576 PCU_RollingCounter_240 20;
BA_ "GenSigCycleTime" SG_ 576 PCU_MotDCUMin 20;
BA_ "GenSigCycleTime" SG_ 576 PCU_MotDCUMax 20;
BA_ "GenSigCycleTime" SG_ 576 PCU_ImmoFeedback 20;
BA_ "GenSigCycleTime" SG_ 576 PCU_ImmoConfiguration 20;
BA_ "GenSigCycleTime" SG_ 576 PCU_GearShiftStyleReq 20;
BA_ "GenSigCycleTime" SG_ 576 PCU_CRCCheck_240 20;

BA_ "GenSigCycleTime" SG_ 583 APA_ESP_BrakeFunctionMode 100;
BA_ "GenSigInvalidValue" SG_ 583 APA_ESP_BrakeFunctionMode "0";
BA_ "GenSigCycleTime" SG_ 583 APA_RollingCounter_236 20;
BA_ "GenSigCycleTime" SG_ 583 APA_PtTrqReqValid 20;
BA_ "GenSigCycleTime" SG_ 583 APA_PtTorqReq 20;
BA_ "GenSigCycleTime" SG_ 583 APA_CRC_Checksum_236 20;
BA_ "GenSigCycleTime" SG_ 583 APA_FunctionOnOffSts 20;
BA_ "GenSigInvalidValue" SG_ 583 APA_FunctionOnOffSts "15";
BA_ "GenSigCycleTime" SG_ 583 APA_CRCCheck_247 20;
BA_ "GenSigCycleTime" SG_ 583 APA_RollingCounter_247 20;
BA_ "GenSigCycleTime" SG_ 583 APA_TrqHoldForTCUCl 20;
BA_ "GenSigCycleTime" SG_ 583 APA_TCUClutchCombinationReq 20;
BA_ "GenSigCycleTime" SG_ 583 APA_APAOnOff 20;
BA_ "GenSigCycleTime" SG_ 583 APA_CRCCheck_264 20;
BA_ "GenSigCycleTime" SG_ 583 APA_ParkingPercentage 20;
BA_ "GenSigInvalidValue" SG_ 583 APA_ParkingPercentage "101";
BA_ "GenSigCycleTime" SG_ 583 APA_RollingCounter_264 20;
BA_ "GenSigCycleTime" SG_ 583 APA_TurnLightsCommand 20;
BA_ "GenSigInvalidValue" SG_ 583 APA_TurnLightsCommand "0";
BA_ "GenSigCycleTime" SG_ 583 APA_ParkNotice 20;
BA_ "GenSigCycleTime" SG_ 583 APA_IncreasePressureReq 20;
BA_ "GenSigInvalidValue" SG_ 583 APA_IncreasePressureReq "0";
BA_ "GenSigCycleTime" SG_ 583 APA_ButtonPress 20;
BA_ "GenSigCycleTime" SG_ 583 APA_RemoteOnOff 20;
BA_ "GenSigCycleTime" SG_ 583 APA_SteeringAngleReq 20;
BA_ "GenSigInvalidValue" SG_ 583 APA_SteeringAngleReq "32767";
BA_ "GenSigCycleTime" SG_ 583 APA_EmergenceBrake 20;
BA_ "GenSigInvalidValue" SG_ 583 APA_EmergenceBrake "0";
BA_ "GenSigCycleTime" SG_ 583 APA_indication 20;
BA_ "GenSigInvalidValue" SG_ 583 APA_indication "5";
BA_ "GenSigCycleTime" SG_ 583 APA_ErrorStatus 20;
BA_ "GenSigCycleTime" SG_ 583 APA_SteeringAngleReqProtection 20;
BA_ "GenSigCycleTime" SG_ 583 APA_HSAHDforbidden 20;
BA_ "GenSigInvalidValue" SG_ 583 APA_HSAHDforbidden "0";
BA_ "GenSigCycleTime" SG_ 583 APA_CRCCheck_26C 20;
BA_ "GenSigCycleTime" SG_ 583 APA_RollingCounter_26C 20;
BA_ "GenSigCycleTime" SG_ 583 APA_ESPDecompressionModel 20;
BA_ "GenSigInvalidValue" SG_ 583 APA_ESPDecompressionModel "0";
BA_ "GenSigCycleTime" SG_ 583 APA_AccPedShieldReq 20;
BA_ "GenSigCycleTime" SG_ 583 APA_SlotNotice 20;
BA_ "GenSigInvalidValue" SG_ 583 APA_SlotNotice "15";
BA_ "GenSigCycleTime" SG_ 583 APA_DynamicSlotWarning 20;
BA_ "GenSigInvalidValue" SG_ 583 APA_DynamicSlotWarning "0";
BA_ "GenSigCycleTime" SG_ 583 APA_PrefillReq 20;
BA_ "GenSigInvalidValue" SG_ 583 APA_PrefillReq "0";
BA_ "GenSigCycleTime" SG_ 583 APA_Activation_Status 20;
BA_ "GenSigCycleTime" SG_ 583 APA_EngTorqReq 20;
BA_ "GenSigInvalidValue" SG_ 583 APA_EngTorqReq "1023";
BA_ "GenSigCycleTime" SG_ 583 APA_EngineTrqReqEnable 20;
BA_ "GenSigInvalidValue" SG_ 583 APA_EngineTrqReqEnable "0";
BA_ "GenSigCycleTime" SG_ 583 APA_LSCAction 20;
BA_ "GenSigCycleTime" SG_ 583 APA_TransPRNDShiftEnable 20;
BA_ "GenSigInvalidValue" SG_ 583 APA_TransPRNDShiftEnable "0";
BA_ "GenSigCycleTime" SG_ 583 APA_TargetAcceleration 20;
BA_ "GenSigStartValue" SG_ 583 APA_TargetAcceleration 100.000000;
BA_ "GenSigCycleTime" SG_ 583 APA_TransPRNDShiftReqValid 20;
BA_ "GenSigInvalidValue" SG_ 583 APA_TransPRNDShiftReqValid "0";
BA_ "GenSigCycleTime" SG_ 583 APA_TransPRNDShiftRequest 20;
BA_ "GenSigInvalidValue" SG_ 583 APA_TransPRNDShiftRequest "0";
BA_ "GenSigCycleTime" SG_ 583 APA_TargetAccelerationValid 20;
BA_ "GenSigInvalidValue" SG_ 583 APA_TargetAccelerationValid "0";
BA_ "GenSigCycleTime" SG_ 583 APA_EPBrequestValid 20;
BA_ "GenSigInvalidValue" SG_ 583 APA_EPBrequestValid "0";
BA_ "GenSigCycleTime" SG_ 583 APA_EPBrequest 20;
BA_ "GenSigInvalidValue" SG_ 583 APA_EPBrequest "0";

BA_ "GenSigCycleTime" SG_ 610 PEPS_RemoteStartKeyStatus 40;
BA_ "GenSigInvalidValue" SG_ 610 PEPS_RemoteStartKeyStatus "0";
BA_ "GenSigCycleTime" SG_ 610 PEPS_APA_PowerMirrorFoldFeedback 40;
BA_ "GenSigCycleTime" SG_ 610 PEPS_APARemoteParkingOff 40;
BA_ "GenSigCycleTime" SG_ 610 PEPS_KeyStandbyPositionIndicator 40;
BA_ "GenSigInvalidValue" SG_ 610 PEPS_KeyStandbyPositionIndicator "0";
BA_ "GenSigCycleTime" SG_ 610 PEPS_CRCCheck_262 40;
BA_ "GenSigCycleTime" SG_ 610 PEPS_RollingCounter_262 40;
BA_ "GenSigCycleTime" SG_ 610 PEPS_PEPSFailStatus 40;
BA_ "GenSigCycleTime" SG_ 610 PEPS_PowerDistributionFaultBit 40;
BA_ "GenSigCycleTime" SG_ 610 PEPS_IMMOFeedback 40;
BA_ "GenSigCycleTime" SG_ 610 PEPS_EngineStartupInhibitFB 40;
BA_ "GenSigCycleTime" SG_ 610 PEPS_RemoteStartFeedback 40;
BA_ "GenSigCycleTime" SG_ 610 PEPS_EngineStartupInhibitSts 40;
BA_ "GenSigCycleTime" SG_ 610 PEPS_PowerDistributionStatus 40;
BA_ "GenSigInvalidValue" SG_ 610 PEPS_PowerDistributionStatus "3";
BA_ "GenSigCycleTime" SG_ 610 PEPS_UnallowStartSignal_Not_PN 40;
BA_ "GenSigCycleTime" SG_ 610 PEPS_IMMOFailedAlarmsignal 40;
BA_ "GenSigCycleTime" SG_ 610 PEPS_UnallowStart_ESCL_LOCK 40;
BA_ "GenSigCycleTime" SG_ 610 PEPS_UnallowStart_ESCL_Error 40;
BA_ "GenSigCycleTime" SG_ 610 PEPS_StartIndicatorSignal 40;
BA_ "GenSigCycleTime" SG_ 610 PEPS_StartupButtonSignal 40;
BA_ "GenSigInvalidValue" SG_ 610 PEPS_StartupButtonSignal "3";
BA_ "GenSigCycleTime" SG_ 610 PEPS_APA_CloseWinFeedback 40;
BA_ "GenSigInvalidValue" SG_ 610 PEPS_APA_CloseWinFeedback "0";
BA_ "GenSigCycleTime" SG_ 610 PEPS_RemoteControlACReq 40;
BA_ "GenSigCycleTime" SG_ 610 PEPS_RemoteAPADoneKeyOffReq 40;
BA_ "GenSigInvalidValue" SG_ 610 PEPS_RemoteAPADoneKeyOffReq "0";
BA_ "GenSigCycleTime" SG_ 610 PEPS_APA_Engine0ffFeedback 40;
BA_ "GenSigInvalidValue" SG_ 610 PEPS_APA_Engine0ffFeedback "0";
BA_ "GenSigCycleTime" SG_ 610 PEPS_APA_LockFeedback 40;
BA_ "GenSigInvalidValue" SG_ 610 PEPS_APA_LockFeedback "0";
BA_ "GenSigCycleTime" SG_ 610 PEPS_APARemoteParkingOn 40;

BA_ "GenSigCycleTime" SG_ 632 ESP_YawRateValid 20;
BA_ "GenSigCycleTime" SG_ 632 ESP_YawRate 20;
BA_ "GenSigInvalidValue" SG_ 632 ESP_YawRate "16383";
BA_ "GenSigCycleTime" SG_ 632 ESP_RollingCounter_278 20;
BA_ "GenSigCycleTime" SG_ 632 ESP_LongAccel 20;
BA_ "GenSigInvalidValue" SG_ 632 ESP_LongAccel "1023";
BA_ "GenSigCycleTime" SG_ 632 ESP_LatAccel 20;
BA_ "GenSigInvalidValue" SG_ 632 ESP_LatAccel "255";
BA_ "GenSigCycleTime" SG_ 632 ESP_CRCCheck_278 20;

BA_ "GenSigCycleTime" SG_ 664 BCM_TrunkUnlockReq 40;
BA_ "GenSigCycleTime" SG_ 664 PEPS_LuggageUnlockSignal 40;
BA_ "GenSigInvalidValue" SG_ 664 PEPS_LuggageUnlockSignal "0";
BA_ "GenSigCycleTime" SG_ 664 BCM_DriverDoorLockStatus 40;
BA_ "GenSigStartValue" SG_ 664 BCM_DriverDoorLockStatus 3.000000;
BA_ "GenSigCycleTime" SG_ 664 BCM_CRCCheck_298 40;
BA_ "GenSigCycleTime" SG_ 664 BCM_RollingCounter_298 40;
BA_ "GenSigCycleTime" SG_ 664 BCM_PassengerDoorLockStatus 40;
BA_ "GenSigCycleTime" SG_ 664 BCM_LeftRearDoorStatus 40;
BA_ "GenSigCycleTime" SG_ 664 PEPS_SmartWelcomeLightStaus 40;
BA_ "GenSigInvalidValue" SG_ 664 PEPS_SmartWelcomeLightStaus "0";
BA_ "GenSigCycleTime" SG_ 664 PEPS_TrunkKeyStatus 40;
BA_ "GenSigInvalidValue" SG_ 664 PEPS_TrunkKeyStatus "0";
BA_ "GenSigCycleTime" SG_ 664 PEPS_UnLockKeyStatus 40;
BA_ "GenSigInvalidValue" SG_ 664 PEPS_UnLockKeyStatus "0";
BA_ "GenSigCycleTime" SG_ 664 PEPS_LockKeyStatus 40;
BA_ "GenSigInvalidValue" SG_ 664 PEPS_LockKeyStatus "0";
BA_ "GenSigCycleTime" SG_ 664 PEPS_SmartTrunkUlockRemind 40;
BA_ "GenSigInvalidValue" SG_ 664 PEPS_SmartTrunkUlockRemind "0";
BA_ "GenSigCycleTime" SG_ 664 PEPS_UnlockSignal 40;
BA_ "GenSigInvalidValue" SG_ 664 PEPS_UnlockSignal "0";
BA_ "GenSigCycleTime" SG_ 664 PEPS_LockSignal 40;
BA_ "GenSigInvalidValue" SG_ 664 PEPS_LockSignal "0";
BA_ "GenSigCycleTime" SG_ 664 PEPS_KeyNumber 40;
BA_ "GenSigInvalidValue" SG_ 664 PEPS_KeyNumber "7";
BA_ "GenSigCycleTime" SG_ 664 PEPS_KeyAuthenticationStatus 40;
BA_ "GenSigCycleTime" SG_ 664 PEPS_Easy_open 40;
BA_ "GenSigInvalidValue" SG_ 664 PEPS_Easy_open "0";
BA_ "GenSigCycleTime" SG_ 664 PEPS_Welcomelamp 40;
BA_ "GenSigInvalidValue" SG_ 664 PEPS_Welcomelamp "0";
BA_ "GenSigCycleTime" SG_ 664 PEPS_TrunkRequestSignal 40;
BA_ "GenSigCycleTime" SG_ 664 PEPS_KeyLearningSignal 40;
BA_ "GenSigInvalidValue" SG_ 664 PEPS_KeyLearningSignal "3";
BA_ "GenSigCycleTime" SG_ 664 PEPS_EasyOpenOrginalSignal 40;
BA_ "GenSigInvalidValue" SG_ 664 PEPS_EasyOpenOrginalSignal "0";
BA_ "GenSigCycleTime" SG_ 664 PEPS_RemoteFailedAlarmSignal 40;
BA_ "GenSigCycleTime" SG_ 664 PEPS_SearchCarSignal 40;

BA_ "GenSigCycleTime" SG_ 793 OBC_RollingCounter_319 100;
BA_ "GenSigCycleTime" SG_ 793 OBC_CRCCheck_319 100;
BA_ "GenSigCycleTime" SG_ 793 DCAC_DcacInpU 100;
BA_ "GenSigInvalidValue" SG_ 793 DCAC_DcacInpU "8191";
BA_ "GenSigCycleTime" SG_ 793 DCAC_DcacInpI 100;
BA_ "GenSigInvalidValue" SG_ 793 DCAC_DcacInpI "0";
BA_ "GenSigCycleTime" SG_ 793 OBC_ResetSts 100;
BA_ "GenSigInvalidValue" SG_ 793 OBC_ResetSts "7";
BA_ "GenSigCycleTime" SG_ 793 OBC_MILONReq 100;
BA_ "GenSigCycleTime" SG_ 793 OBC_IntT 100;
BA_ "GenSigStartValue" SG_ 793 OBC_IntT 60.000000;
BA_ "GenSigInvalidValue" SG_ 793 OBC_IntT "255";
BA_ "GenSigCycleTime" SG_ 793 DCAC_DcacPwrCnseAct 100;
BA_ "GenSigInvalidValue" SG_ 793 DCAC_DcacPwrCnseAct "4095";
BA_ "GenSigCycleTime" SG_ 793 DCAC_DcacOutpU 100;
BA_ "GenSigInvalidValue" SG_ 793 DCAC_DcacOutpU "255";
BA_ "GenSigCycleTime" SG_ 793 DCAC_DcacOutpPwrAvlMax 100;
BA_ "GenSigInvalidValue" SG_ 793 DCAC_DcacOutpPwrAvlMax "4095";
BA_ "GenSigCycleTime" SG_ 793 DCAC_DcacOutpI 100;
BA_ "GenSigInvalidValue" SG_ 793 DCAC_DcacOutpI "4095";
BA_ "GenSigCycleTime" SG_ 793 DCAC_DcacOperMod 100;
BA_ "GenSigInvalidValue" SG_ 793 DCAC_DcacOperMod "15";
BA_ "GenSigCycleTime" SG_ 793 DCAC_DcacFltRnk 100;
BA_ "GenSigCycleTime" SG_ 793 DCAC_DcacErrNr 100;
BA_ "GenSigInvalidValue" SG_ 793 DCAC_DcacErrNr "2047";
BA_ "GenSigCycleTime" SG_ 793 OBC_ObcWaterT 100;
BA_ "GenSigStartValue" SG_ 793 OBC_ObcWaterT 60.000000;
BA_ "GenSigInvalidValue" SG_ 793 OBC_ObcWaterT "255";
BA_ "GenSigCycleTime" SG_ 793 OBC_ObcTOverWarn 100;
BA_ "GenSigCycleTime" SG_ 793 OBC_ObcErrNr 100;
BA_ "GenSigInvalidValue" SG_ 793 OBC_ObcErrNr "255";
BA_ "GenSigCycleTime" SG_ 793 OBC_ObcChrgInpAcU 100;
BA_ "GenSigInvalidValue" SG_ 793 OBC_ObcChrgInpAcU "511";
BA_ "GenSigCycleTime" SG_ 793 OBC_ObcChrgInpAcI 100;
BA_ "GenSigInvalidValue" SG_ 793 OBC_ObcChrgInpAcI "1023";
BA_ "GenSigCycleTime" SG_ 793 OBC_ObcChrgDcU 100;
BA_ "GenSigInvalidValue" SG_ 793 OBC_ObcChrgDcU "8191";
BA_ "GenSigCycleTime" SG_ 793 OBC_ObcChrgDcI 100;
BA_ "GenSigInvalidValue" SG_ 793 OBC_ObcChrgDcI "1023";
BA_ "GenSigCycleTime" SG_ 793 OBC_Obc349CycCntr 100;
BA_ "GenSigInvalidValue" SG_ 793 OBC_Obc349CycCntr "15";
BA_ "GenSigCycleTime" SG_ 793 OBC_HVPwrOnReq 100;
BA_ "GenSigInvalidValue" SG_ 793 OBC_HVPwrOnReq "0";
BA_ "GenSigCycleTime" SG_ 793 OBC_ObcWakeupSrc 100;
BA_ "GenSigCycleTime" SG_ 793 OBC_ObcS2Sts 100;
BA_ "GenSigCycleTime" SG_ 793 OBC_ObcMaxChrgOutpUAvl 100;
BA_ "GenSigInvalidValue" SG_ 793 OBC_ObcMaxChrgOutpUAvl "8191";
BA_ "GenSigCycleTime" SG_ 793 OBC_ObcMaxChrgOutpPwrAvl 100;
BA_ "GenSigInvalidValue" SG_ 793 OBC_ObcMaxChrgOutpPwrAvl "1023";
BA_ "GenSigCycleTime" SG_ 793 OBC_ObcMaxChrgOutpIAvl 100;
BA_ "GenSigInvalidValue" SG_ 793 OBC_ObcMaxChrgOutpIAvl "1023";
BA_ "GenSigCycleTime" SG_ 793 OBC_ObcFltRnk 100;
BA_ "GenSigCycleTime" SG_ 793 OBC_ObcCpValVld 100;
BA_ "GenSigInvalidValue" SG_ 793 OBC_ObcCpValVld "0";
BA_ "GenSigCycleTime" SG_ 793 OBC_ObcCpVal 100;
BA_ "GenSigInvalidValue" SG_ 793 OBC_ObcCpVal "255";
BA_ "GenSigCycleTime" SG_ 793 OBC_ObcCpOutpU 100;
BA_ "GenSigInvalidValue" SG_ 793 OBC_ObcCpOutpU "63";
BA_ "GenSigCycleTime" SG_ 793 OBC_ObcChrgSts 100;
BA_ "GenSigInvalidValue" SG_ 793 OBC_ObcChrgSts "15";
BA_ "GenSigCycleTime" SG_ 793 OBC_Obc319CycCntr 100;
BA_ "GenSigInvalidValue" SG_ 793 OBC_Obc319CycCntr "15";
BA_ "GenSigCycleTime" SG_ 793 OBC_ChargeCoverSts 100;

BA_ "GenSigCycleTime" SG_ 804 TMS_ClearDiagnositicInfo 100;
BA_ "GenSigCycleTime" SG_ 804 TMS_PwrSafeAct 100;
BA_ "GenSigCycleTime" SG_ 804 TMS_PwrMinReq 100;
BA_ "GenSigCycleTime" SG_ 804 TMS_PwrMaxReq 100;
BA_ "GenSigCycleTime" SG_ 804 TMS_PTC_Current 100;
BA_ "GenSigCycleTime" SG_ 804 TMS_Motor_Temp_inValid 100;
BA_ "GenSigCycleTime" SG_ 804 TMS_Motor_Temp_in 100;
BA_ "GenSigStartValue" SG_ 804 TMS_Motor_Temp_in 60.000000;
BA_ "GenSigCycleTime" SG_ 804 TMS_MILONReq 100;
BA_ "GenSigCycleTime" SG_ 804 TMS_BattT_out 100;
BA_ "GenSigStartValue" SG_ 804 TMS_BattT_out 60.000000;
BA_ "GenSigCycleTime" SG_ 804 TMS_WaterPumpDutyCycle 100;

BA_ "GenSigCycleTime" SG_ 838 EMS_ReFueldSts 100;
BA_ "GenSigCycleTime" SG_ 838 EMS_NormalDteskEvapdiareq 100;
BA_ "GenSigCycleTime" SG_ 838 EMS_ClearTMSDiagnositicInfo 100;
BA_ "GenSigCycleTime" SG_ 838 EMS_CleaGPEUDiagnosticInfo 100;
BA_ "GenSigCycleTime" SG_ 838 EMS_EngStrtInhb 100;
BA_ "GenSigCycleTime" SG_ 838 EMS_CoolantThermostatDC 100;
BA_ "GenSigInvalidValue" SG_ 838 EMS_CoolantThermostatDC "15";
BA_ "GenSigCycleTime" SG_ 838 EMS_flgWtrPmpErr 100;
BA_ "GenSigCycleTime" SG_ 838 EMS_WtrPmpActSpd 100;
BA_ "GenSigInvalidValue" SG_ 838 EMS_WtrPmpActSpd "127";
BA_ "GenSigCycleTime" SG_ 838 EMS_WtrPmpTargetSpd 100;
BA_ "GenSigInvalidValue" SG_ 838 EMS_WtrPmpTargetSpd "127";
BA_ "GenSigCycleTime" SG_ 838 EMS_EngTargetCoolantTemp 100;
BA_ "GenSigStartValue" SG_ 838 EMS_EngTargetCoolantTemp 63.000000;
BA_ "GenSigInvalidValue" SG_ 838 EMS_EngTargetCoolantTemp "63";
BA_ "GenSigCycleTime" SG_ 838 EMS_ClearOBCDiagnosticInfo 100;
BA_ "GenSigCycleTime" SG_ 838 EMS_EngProtectionActive 100;
BA_ "GenSigCycleTime" SG_ 838 EMS_MILIndcdLightInfo 100;
BA_ "GenSigCycleTime" SG_ 838 EMS_EGRDia 100;
BA_ "GenSigCycleTime" SG_ 838 Ems_GpfSrvRgnReq 100;
BA_ "GenSigCycleTime" SG_ 838 EMS_DenominatorCntr2 100;
BA_ "GenSigCycleTime" SG_ 838 EMS_DenominatorCntr1 100;
BA_ "GenSigCycleTime" SG_ 838 EmsEngCoolanT2 100;
BA_ "GenSigCycleTime" SG_ 838 EMS_ClearRPEUDiagnosticInfo 100;
BA_ "GenSigCycleTime" SG_ 838 Ems_EngRvsTowingReq 100;
BA_ "GenSigCycleTime" SG_ 838 Ems_EngFuCutOffFbd 100;
BA_ "GenSigCycleTime" SG_ 838 Ems_GpfActvRgnReq 100;
BA_ "GenSigCycleTime" SG_ 838 Ems_FltRnk 100;
BA_ "GenSigCycleTime" SG_ 838 EMS_RollingCounter_346 100;
BA_ "GenSigCycleTime" SG_ 838 EMS_CRCCheck_346 100;
BA_ "GenSigCycleTime" SG_ 838 EMS_CleaDPEUDiagnosticInfo 100;
BA_ "GenSigCycleTime" SG_ 838 EMS_ThrottleRelativePosition 100;
BA_ "GenSigInvalidValue" SG_ 838 EMS_ThrottleRelativePosition "255";
BA_ "GenSigCycleTime" SG_ 838 EMS_ThrottleAbsolutePosition 100;
BA_ "GenSigInvalidValue" SG_ 838 EMS_ThrottleAbsolutePosition "255";
BA_ "GenSigCycleTime" SG_ 838 EMS_PwrTrainStopTime 100;
BA_ "GenSigStartValue" SG_ 838 EMS_PwrTrainStopTime 65535.000000;
BA_ "GenSigInvalidValue" SG_ 838 EMS_PwrTrainStopTime "255";
BA_ "GenSigCycleTime" SG_ 838 EMS_PwrTrainRunningTime 100;
BA_ "GenSigStartValue" SG_ 838 EMS_PwrTrainRunningTime 65535.000000;
BA_ "GenSigInvalidValue" SG_ 838 EMS_PwrTrainRunningTime "65535";
BA_ "GenSigCycleTime" SG_ 838 EMS_ClearPCUDiagnosticInfo 100;
BA_ "GenSigCycleTime" SG_ 838 EMS_ClearIBCUDiagnosticInfo 100;
BA_ "GenSigCycleTime" SG_ 838 EMS_ClearBMSDiagnosticInfo 100;
BA_ "GenSigCycleTime" SG_ 838 EMS_PFCCCondition 100;
BA_ "GenSigCycleTime" SG_ 838 EMS_GPF_State 100;
BA_ "GenSigInvalidValue" SG_ 838 EMS_GPF_State "7";
BA_ "GenSigCycleTime" SG_ 838 EMS_EngLoad 100;
BA_ "GenSigInvalidValue" SG_ 838 EMS_EngLoad "255";
BA_ "GenSigCycleTime" SG_ 838 EMS_OxygenSensorDia 100;
BA_ "GenSigCycleTime" SG_ 838 EMS_LowPreOilPumpProRemind 100;
BA_ "GenSigCycleTime" SG_ 838 EMS_EngProtectionRemind 100;
BA_ "GenSigCycleTime" SG_ 838 EMS_TotOdometer 100;
BA_ "GenSigCycleTime" SG_ 838 EMS_SVSLamp 100;
BA_ "GenSigCycleTime" SG_ 838 EMS_OilPressureSts 100;
BA_ "GenSigCycleTime" SG_ 838 EMS_MILIndcd 100;
BA_ "GenSigCycleTime" SG_ 838 EMS_FuelCapLeakDisplay 100;
BA_ "GenSigCycleTime" SG_ 838 EMS_FuCnse 100;
BA_ "GenSigCycleTime" SG_ 838 EMS_EngOilT 100;

BA_ "GenSigCycleTime" SG_ 870 AC_TargetTorque 100;
BA_ "GenSigInvalidValue" SG_ 870 AC_TargetTorque "255";
BA_ "GenSigCycleTime" SG_ 870 AC_WorkSts 100;
BA_ "GenSigCycleTime" SG_ 870 AC_PTCStatus 100;
BA_ "GenSigInvalidValue" SG_ 870 AC_PTCStatus "3";
BA_ "GenSigCycleTime" SG_ 870 AC_SolenoidCurrent 100;
BA_ "GenSigInvalidValue" SG_ 870 AC_SolenoidCurrent "255";
BA_ "GenSigCycleTime" SG_ 870 AC_CompressorStatus 100;
BA_ "GenSigInvalidValue" SG_ 870 AC_CompressorStatus "0";
BA_ "GenSigCycleTime" SG_ 870 AC_ACPre 100;
BA_ "GenSigInvalidValue" SG_ 870 AC_ACPre "4095";
BA_ "GenSigCycleTime" SG_ 870 AC_AC_ReqValid 100;
BA_ "GenSigInvalidValue" SG_ 870 AC_AC_ReqValid "1";
BA_ "GenSigCycleTime" SG_ 870 AC_FrReqWindLevel 100;
BA_ "GenSigInvalidValue" SG_ 870 AC_FrReqWindLevel "15";
BA_ "GenSigCycleTime" SG_ 870 AC_FrReqWindLevelVD 100;
BA_ "GenSigInvalidValue" SG_ 870 AC_FrReqWindLevelVD "1";
BA_ "GenSigCycleTime" SG_ 870 AC_AC_Req 100;
BA_ "GenSigCycleTime" SG_ 870 AC_EnvironmentalTemp 100;
BA_ "GenSigStartValue" SG_ 870 AC_EnvironmentalTemp 255.000000;
BA_ "GenSigInvalidValue" SG_ 870 AC_EnvironmentalTemp "255";
BA_ "GenSigCycleTime" SG_ 870 AC_EnvironmentalTempVD 100;
BA_ "GenSigInvalidValue" SG_ 870 AC_EnvironmentalTempVD "1";

BA_ "GenSigCycleTime" SG_ 1302 HU_AirHumidityValid 1000;
BA_ "GenSigInvalidValue" SG_ 1302 HU_AirHumidityValid "1";
BA_ "GenSigCycleTime" SG_ 1302 HU_AirHumidity 1000;
BA_ "GenSigInvalidValue" SG_ 1302 HU_AirHumidity "127";
BA_ "GenSigCycleTime" SG_ 1302 HU_LeaveMaintainMileage 1000;
BA_ "GenSigInvalidValue" SG_ 1302 HU_LeaveMaintainMileage "1048575";
BA_ "GenSigCycleTime" SG_ 1302 HU_LeaveMaintainDay 1000;
BA_ "GenSigInvalidValue" SG_ 1302 HU_LeaveMaintainDay "4095";
BA_ "GenSigCycleTime" SG_ 1302 HU_MaintainRemindReq 1000;
BA_ "GenSigInvalidValue" SG_ 1302 HU_MaintainRemindReq "0";
BA_ "GenSigCycleTime" SG_ 1302 HU_LocalTimeSystem 1000;
BA_ "GenSigCycleTime" SG_ 1302 HU_LocalTimeSecond 1000;
BA_ "GenSigInvalidValue" SG_ 1302 HU_LocalTimeSecond "0";
BA_ "GenSigCycleTime" SG_ 1302 HU_LocalTimeMinute 1000;
BA_ "GenSigInvalidValue" SG_ 1302 HU_LocalTimeMinute "0";
BA_ "GenSigCycleTime" SG_ 1302 HU_LocalTimeHour 1000;
BA_ "GenSigInvalidValue" SG_ 1302 HU_LocalTimeHour "0";
BA_ "GenSigCycleTime" SG_ 1302 HU_LocalTimeDate 1000;
BA_ "GenSigStartValue" SG_ 1302 HU_LocalTimeDate 1.000000;
BA_ "GenSigInvalidValue" SG_ 1302 HU_LocalTimeDate "1";
BA_ "GenSigCycleTime" SG_ 1302 HU_LocalTimeYear 1000;
BA_ "GenSigInvalidValue" SG_ 1302 HU_LocalTimeYear "0";
BA_ "GenSigCycleTime" SG_ 1302 HU_LocalTimeMonth 1000;
BA_ "GenSigStartValue" SG_ 1302 HU_LocalTimeMonth 1.000000;
BA_ "GenSigInvalidValue" SG_ 1302 HU_LocalTimeMonth "1";
BA_ "GenSigCycleTime" SG_ 1302 HU_LocalTimeValid 1000;
BA_ "GenSigInvalidValue" SG_ 1302 HU_LocalTimeValid "1";
BA_ "GenSigCycleTime" SG_ 1302 HU_CurrentLocationLatitude 1000;
BA_ "GenSigInvalidValue" SG_ 1302 HU_CurrentLocationLatitude "268435455";
BA_ "GenSigCycleTime" SG_ 1302 HU_CurrentLocationLongitude 1000;
BA_ "GenSigInvalidValue" SG_ 1302 HU_CurrentLocationLongitude "536870911";
BA_ "GenSigCycleTime" SG_ 1302 HU_CurrentLocationValid 1000;
BA_ "GenSigInvalidValue" SG_ 1302 HU_CurrentLocationValid "1";

BA_ "GenSigCycleTime" SG_ 1304 BCM_CarMode 500;
BA_ "GenSigInvalidValue" SG_ 1304 BCM_CarMode "0";

BA_ "GenSigCycleTime" SG_ 1328 IP_FuelLevel 500;
BA_ "GenSigInvalidValue" SG_ 1328 IP_FuelLevel "0";
BA_ "GenSigCycleTime" SG_ 1328 IP_TotalOdometer 500;
BA_ "GenSigInvalidValue" SG_ 1328 IP_TotalOdometer "16777215";
BA_ "GenSigCycleTime" SG_ 1328 IP_EngineOffTime 500;
BA_ "GenSigInvalidValue" SG_ 1328 IP_EngineOffTime "65535";

BA_ "GenSigCycleTime" SG_ 1333 BMS_BcuCycWakupCount 50;
BA_ "GenSigInvalidValue" SG_ 1333 BMS_BcuCycWakupCount "0";
BA_ "GenSigCycleTime" SG_ 1333 BMS_BcuCycWakupSts 50;
BA_ "GenSigInvalidValue" SG_ 1333 BMS_BcuCycWakupSts "LastValue";
BA_ "GenSigCycleTime" SG_ 1333 BMS_CellDeltaU 50;
BA_ "GenSigInvalidValue" SG_ 1333 BMS_CellDeltaU "2047";
BA_ "GenSigCycleTime" SG_ 1333 BMS_ModTRiseValue 50;
BA_ "GenSigCycleTime" SG_ 1333 BMS_ModTRiseQntty 50;
BA_ "GenSigInvalidValue" SG_ 1333 BMS_ModTRiseQntty "15";
BA_ "GenSigCycleTime" SG_ 1333 BMS_ModTRiseNum 50;
BA_ "GenSigInvalidValue" SG_ 1333 BMS_ModTRiseNum "63";
BA_ "GenSigCycleTime" SG_ 1333 BMS_CellUdownErrQntty 50;
BA_ "GenSigInvalidValue" SG_ 1333 BMS_CellUdownErrQntty "31";
BA_ "GenSigCycleTime" SG_ 1333 BMS_CellUdownErrNum 50;
BA_ "GenSigCycleTime" SG_ 1333 BMS_SosMixSt 50;
BA_ "GenSigInvalidValue" SG_ 1333 BMS_SosMixSt "0";
BA_ "GenSigCycleTime" SG_ 1333 BMS_PackARMU 50;
BA_ "GenSigInvalidValue" SG_ 1333 BMS_PackARMU "2047";
BA_ "GenSigCycleTime" SG_ 1333 BMS_DataUploadReq 50;
BA_ "GenSigCycleTime" SG_ 1333 BMS_Wkpmod 50;
BA_ "GenSigInvalidValue" SG_ 1333 BMS_Wkpmod "NA";
BA_ "GenSigCycleTime" SG_ 1333 BMS_SwitchSts 50;
BA_ "GenSigInvalidValue" SG_ 1333 BMS_SwitchSts "NA";
BA_ "GenSigCycleTime" SG_ 1333 BMS_PckPrssrSts 50;
BA_ "GenSigInvalidValue" SG_ 1333 BMS_PckPrssrSts "0";
BA_ "GenSigCycleTime" SG_ 1333 BMS_PackPRMU 50;
BA_ "GenSigInvalidValue" SG_ 1333 BMS_PackPRMU "0";
BA_ "GenSigCycleTime" SG_ 1333 BMS_HeatWarngSts 50;
BA_ "GenSigInvalidValue" SG_ 1333 BMS_HeatWarngSts "NA";
BA_ "GenSigCycleTime" SG_ 1333 BMS_HeatSftyStsRMU 50;
BA_ "GenSigInvalidValue" SG_ 1333 BMS_HeatSftyStsRMU "0";
BA_ "GenSigCycleTime" SG_ 1333 BMS_StopCarTi 50;
BA_ "GenSigInvalidValue" SG_ 1333 BMS_StopCarTi "NA";
BA_ "GenSigCycleTime" SG_ 1333 BMS_CycleNr 50;
BA_ "GenSigInvalidValue" SG_ 1333 BMS_CycleNr "NA";
BA_ "GenSigCycleTime" SG_ 1333 BMS_CycleSt 50;
BA_ "GenSigInvalidValue" SG_ 1333 BMS_CycleSt "NA";
BA_ "GenSigCycleTime" SG_ 1333 BMS_FirstCellU 50;
BA_ "GenSigInvalidValue" SG_ 1333 BMS_FirstCellU "NA";

BA_ "GenSigCycleTime" SG_ 1541 BMS_SOCUproModDisp 1000;
BA_ "GenSigCycleTime" SG_ 1541 BMS_SOCOverFlgDisp 1000;
BA_ "GenSigCycleTime" SG_ 1541 BMS_SOCEKFDisp 1000;
BA_ "GenSigCycleTime" SG_ 1541 BMS_BattResidPwr 1000;
BA_ "GenSigInvalidValue" SG_ 1541 BMS_BattResidPwr "65535";
BA_ "GenSigCycleTime" SG_ 1541 BMS_BattRatedAh 1000;
BA_ "GenSigInvalidValue" SG_ 1541 BMS_BattRatedAh "65535";
BA_ "GenSigCycleTime" SG_ 1541 BMS_SOCCntrDisp 1000;
BA_ "GenSigCycleTime" SG_ 1541 BMS_VehCANErr 1000;
BA_ "GenSigCycleTime" SG_ 1541 BMS_SOHBattCpDisp 1000;
BA_ "GenSigInvalidValue" SG_ 1541 BMS_SOHBattCpDisp "NA";
BA_ "GenSigCycleTime" SG_ 1541 BMS_SOCEstDisp 1000;
BA_ "GenSigInvalidValue" SG_ 1541 BMS_SOCEstDisp "NA";
BA_ "GenSigCycleTime" SG_ 1541 BMS_OverCrrtDischrg 1000;
BA_ "GenSigCycleTime" SG_ 1541 BMS_OverCrrtChrg 1000;
BA_ "GenSigCycleTime" SG_ 1541 BMS_SwVers 1000;
BA_ "GenSigCycleTime" SG_ 1541 BMS_SwSn 1000;
BA_ "GenSigCycleTime" SG_ 1541 BMS_SwNm 1000;
BA_ "GenSigCycleTime" SG_ 1541 BMS_HwVers 1000;
BA_ "GenSigCycleTime" SG_ 1541 BMS_CalDataVers 1000;
BA_ "GenSigCycleTime" SG_ 1541 BMS_BattSoe 1000;
BA_ "GenSigInvalidValue" SG_ 1541 BMS_BattSoe "1023";
BA_ "GenSigCycleTime" SG_ 1541 BMS_SOH 1000;
BA_ "GenSigInvalidValue" SG_ 1541 BMS_SOH "1023";
BA_ "GenSigCycleTime" SG_ 1541 BMS_SOCMin 1000;
BA_ "GenSigInvalidValue" SG_ 1541 BMS_SOCMin "255";
BA_ "GenSigCycleTime" SG_ 1541 BMS_SOCMax 1000;
BA_ "GenSigInvalidValue" SG_ 1541 BMS_SOCMax "255";
BA_ "GenSigCycleTime" SG_ 1541 BMS_RmaingCpby 1000;
BA_ "GenSigInvalidValue" SG_ 1541 BMS_RmaingCpby "32767";
BA_ "GenSigCycleTime" SG_ 1541 BMS_ChrgnSysIAllwdMax 1000;
BA_ "GenSigInvalidValue" SG_ 1541 BMS_ChrgnSysIAllwdMax "511";
BA_ "GenSigCycleTime" SG_ 1541 BMS_BattT_InpReq 1000;
BA_ "GenSigStartValue" SG_ 1541 BMS_BattT_InpReq 60.000000;
BA_ "GenSigInvalidValue" SG_ 1541 BMS_BattT_InpReq "255";

BA_ "GenSigCycleTime" SG_ 1590 BMS_CellEquilnSts168 1000;
BA_ "GenSigCycleTime" SG_ 1590 BMS_CellEquilnSts167 1000;
BA_ "GenSigCycleTime" SG_ 1590 BMS_CellEquilnSts166 1000;
BA_ "GenSigCycleTime" SG_ 1590 BMS_CellEquilnSts165 1000;
BA_ "GenSigCycleTime" SG_ 1590 BMS_CellEquilnSts164 1000;
BA_ "GenSigCycleTime" SG_ 1590 BMS_CellEquilnSts163 1000;
BA_ "GenSigCycleTime" SG_ 1590 BMS_CellEquilnSts162 1000;
BA_ "GenSigCycleTime" SG_ 1590 BMS_CellEquilnSts161 1000;
BA_ "GenSigCycleTime" SG_ 1590 BMS_CellEquilnSts160 1000;
BA_ "GenSigCycleTime" SG_ 1590 BMS_CellEquilnSts159 1000;
BA_ "GenSigCycleTime" SG_ 1590 BMS_CellEquilnSts158 1000;
BA_ "GenSigCycleTime" SG_ 1590 BMS_CellEquilnSts157 1000;
BA_ "GenSigCycleTime" SG_ 1590 BMS_CellEquilnSts156 1000;
BA_ "GenSigCycleTime" SG_ 1590 BMS_CellEquilnSts155 1000;
BA_ "GenSigCycleTime" SG_ 1590 BMS_CellEquilnSts154 1000;
BA_ "GenSigCycleTime" SG_ 1590 BMS_CellEquilnSts153 1000;
BA_ "GenSigCycleTime" SG_ 1590 BMS_CellEquilnSts152 1000;
BA_ "GenSigCycleTime" SG_ 1590 BMS_CellEquilnSts151 1000;
BA_ "GenSigCycleTime" SG_ 1590 BMS_CellEquilnSts150 1000;
BA_ "GenSigCycleTime" SG_ 1590 BMS_CellEquilnSts149 1000;
BA_ "GenSigCycleTime" SG_ 1590 BMS_CellEquilnSts148 1000;
BA_ "GenSigCycleTime" SG_ 1590 BMS_CellEquilnSts147 1000;
BA_ "GenSigCycleTime" SG_ 1590 BMS_CellEquilnSts146 1000;
BA_ "GenSigCycleTime" SG_ 1590 BMS_CellEquilnSts145 1000;
BA_ "GenSigCycleTime" SG_ 1590 BMS_CellEquilnSts144 1000;
BA_ "GenSigCycleTime" SG_ 1590 BMS_CellEquilnSts143 1000;
BA_ "GenSigCycleTime" SG_ 1590 BMS_CellEquilnSts142 1000;
BA_ "GenSigCycleTime" SG_ 1590 BMS_CellEquilnSts141 1000;
BA_ "GenSigCycleTime" SG_ 1590 BMS_CellEquilnSts140 1000;
BA_ "GenSigCycleTime" SG_ 1590 BMS_CellEquilnSts139 1000;
BA_ "GenSigCycleTime" SG_ 1590 BMS_CellEquilnSts138 1000;
BA_ "GenSigCycleTime" SG_ 1590 BMS_CellEquilnSts137 1000;
BA_ "GenSigCycleTime" SG_ 1590 BMS_CellEquilnSts136 1000;
BA_ "GenSigCycleTime" SG_ 1590 BMS_CellEquilnSts135 1000;
BA_ "GenSigCycleTime" SG_ 1590 BMS_CellEquilnSts134 1000;
BA_ "GenSigCycleTime" SG_ 1590 BMS_CellEquilnSts133 1000;
BA_ "GenSigCycleTime" SG_ 1590 BMS_CellEquilnSts132 1000;
BA_ "GenSigCycleTime" SG_ 1590 BMS_CellEquilnSts131 1000;
BA_ "GenSigCycleTime" SG_ 1590 BMS_CellEquilnSts130 1000;
BA_ "GenSigCycleTime" SG_ 1590 BMS_CellEquilnSts129 1000;
BA_ "GenSigCycleTime" SG_ 1590 BMS_CellEquilnSts128 1000;
BA_ "GenSigCycleTime" SG_ 1590 BMS_CellEquilnSts127 1000;
BA_ "GenSigCycleTime" SG_ 1590 BMS_CellEquilnSts126 1000;
BA_ "GenSigCycleTime" SG_ 1590 BMS_CellEquilnSts125 1000;
BA_ "GenSigCycleTime" SG_ 1590 BMS_CellEquilnSts124 1000;
BA_ "GenSigCycleTime" SG_ 1590 BMS_CellEquilnSts123 1000;
BA_ "GenSigCycleTime" SG_ 1590 BMS_CellEquilnSts122 1000;
BA_ "GenSigCycleTime" SG_ 1590 BMS_CellEquilnSts121 1000;
BA_ "GenSigCycleTime" SG_ 1590 BMS_CellEquilnSts120 1000;
BA_ "GenSigCycleTime" SG_ 1590 BMS_CellEquilnSts119 1000;
BA_ "GenSigCycleTime" SG_ 1590 BMS_CellEquilnSts118 1000;
BA_ "GenSigCycleTime" SG_ 1590 BMS_CellEquilnSts117 1000;
BA_ "GenSigCycleTime" SG_ 1590 BMS_CellEquilnSts116 1000;
BA_ "GenSigCycleTime" SG_ 1590 BMS_CellEquilnSts115 1000;
BA_ "GenSigCycleTime" SG_ 1590 BMS_CellEquilnSts114 1000;
BA_ "GenSigCycleTime" SG_ 1590 BMS_CellEquilnSts113 1000;
BA_ "GenSigCycleTime" SG_ 1590 BMS_CellEquilnSts112 1000;
BA_ "GenSigCycleTime" SG_ 1590 BMS_CellEquilnSts111 1000;
BA_ "GenSigCycleTime" SG_ 1590 BMS_CellEquilnSts110 1000;
BA_ "GenSigCycleTime" SG_ 1590 BMS_CellEquilnSts109 1000;
BA_ "GenSigCycleTime" SG_ 1590 BMS_CellEquilnSts108 1000;
BA_ "GenSigCycleTime" SG_ 1590 BMS_CellEquilnSts107 1000;
BA_ "GenSigCycleTime" SG_ 1590 BMS_CellEquilnSts106 1000;
BA_ "GenSigCycleTime" SG_ 1590 BMS_CellEquilnSts105 1000;
BA_ "GenSigCycleTime" SG_ 1590 BMS_CellEquilnSts104 1000;
BA_ "GenSigCycleTime" SG_ 1590 BMS_CellEquilnSts103 1000;
BA_ "GenSigCycleTime" SG_ 1590 BMS_CellEquilnSts102 1000;
BA_ "GenSigCycleTime" SG_ 1590 BMS_CellEquilnSts101 1000;
BA_ "GenSigCycleTime" SG_ 1590 BMS_CellEquilnSts100 1000;
BA_ "GenSigCycleTime" SG_ 1590 BMS_CellEquilnSts99 1000;
BA_ "GenSigCycleTime" SG_ 1590 BMS_CellEquilnSts98 1000;
BA_ "GenSigCycleTime" SG_ 1590 BMS_CellEquilnSts97 1000;
BA_ "GenSigCycleTime" SG_ 1590 BMS_CellEquilnSts96 1000;
BA_ "GenSigCycleTime" SG_ 1590 BMS_CellEquilnSts95 1000;
BA_ "GenSigCycleTime" SG_ 1590 BMS_CellEquilnSts94 1000;
BA_ "GenSigCycleTime" SG_ 1590 BMS_CellEquilnSts93 1000;
BA_ "GenSigCycleTime" SG_ 1590 BMS_CellEquilnSts92 1000;
BA_ "GenSigCycleTime" SG_ 1590 BMS_CellEquilnSts91 1000;
BA_ "GenSigCycleTime" SG_ 1590 BMS_CellEquilnSts90 1000;
BA_ "GenSigCycleTime" SG_ 1590 BMS_CellEquilnSts89 1000;
BA_ "GenSigCycleTime" SG_ 1590 BMS_CellEquilnSts88 1000;
BA_ "GenSigCycleTime" SG_ 1590 BMS_CellEquilnSts87 1000;
BA_ "GenSigCycleTime" SG_ 1590 BMS_CellEquilnSts86 1000;
BA_ "GenSigCycleTime" SG_ 1590 BMS_CellEquilnSts85 1000;
BA_ "GenSigCycleTime" SG_ 1590 BMS_CellEquilnSts84 1000;
BA_ "GenSigCycleTime" SG_ 1590 BMS_CellEquilnSts83 1000;
BA_ "GenSigCycleTime" SG_ 1590 BMS_CellEquilnSts82 1000;
BA_ "GenSigCycleTime" SG_ 1590 BMS_CellEquilnSts81 1000;
BA_ "GenSigCycleTime" SG_ 1590 BMS_CellEquilnSts80 1000;
BA_ "GenSigCycleTime" SG_ 1590 BMS_CellEquilnSts79 1000;
BA_ "GenSigCycleTime" SG_ 1590 BMS_CellEquilnSts78 1000;
BA_ "GenSigCycleTime" SG_ 1590 BMS_CellEquilnSts77 1000;
BA_ "GenSigCycleTime" SG_ 1590 BMS_CellEquilnSts76 1000;
BA_ "GenSigCycleTime" SG_ 1590 BMS_CellEquilnSts75 1000;
BA_ "GenSigCycleTime" SG_ 1590 BMS_CellEquilnSts74 1000;
BA_ "GenSigCycleTime" SG_ 1590 BMS_CellEquilnSts73 1000;
BA_ "GenSigCycleTime" SG_ 1590 BMS_CellEquilnSts72 1000;
BA_ "GenSigCycleTime" SG_ 1590 BMS_CellEquilnSts71 1000;
BA_ "GenSigCycleTime" SG_ 1590 BMS_CellEquilnSts70 1000;
BA_ "GenSigCycleTime" SG_ 1590 BMS_CellEquilnSts69 1000;
BA_ "GenSigCycleTime" SG_ 1590 BMS_CellEquilnSts68 1000;
BA_ "GenSigCycleTime" SG_ 1590 BMS_CellEquilnSts67 1000;
BA_ "GenSigCycleTime" SG_ 1590 BMS_CellEquilnSts66 1000;
BA_ "GenSigCycleTime" SG_ 1590 BMS_CellEquilnSts65 1000;
BA_ "GenSigCycleTime" SG_ 1590 BMS_CellEquilnSts9 1000;
BA_ "GenSigCycleTime" SG_ 1590 BMS_CellEquilnSts8 1000;
BA_ "GenSigCycleTime" SG_ 1590 BMS_CellEquilnSts7 1000;
BA_ "GenSigCycleTime" SG_ 1590 BMS_CellEquilnSts64 1000;
BA_ "GenSigCycleTime" SG_ 1590 BMS_CellEquilnSts63 1000;
BA_ "GenSigCycleTime" SG_ 1590 BMS_CellEquilnSts62 1000;
BA_ "GenSigCycleTime" SG_ 1590 BMS_CellEquilnSts61 1000;
BA_ "GenSigCycleTime" SG_ 1590 BMS_CellEquilnSts60 1000;
BA_ "GenSigCycleTime" SG_ 1590 BMS_CellEquilnSts6 1000;
BA_ "GenSigCycleTime" SG_ 1590 BMS_CellEquilnSts59 1000;
BA_ "GenSigCycleTime" SG_ 1590 BMS_CellEquilnSts58 1000;
BA_ "GenSigCycleTime" SG_ 1590 BMS_CellEquilnSts57 1000;
BA_ "GenSigCycleTime" SG_ 1590 BMS_CellEquilnSts56 1000;
BA_ "GenSigCycleTime" SG_ 1590 BMS_CellEquilnSts55 1000;
BA_ "GenSigCycleTime" SG_ 1590 BMS_CellEquilnSts54 1000;
BA_ "GenSigCycleTime" SG_ 1590 BMS_CellEquilnSts53 1000;
BA_ "GenSigCycleTime" SG_ 1590 BMS_CellEquilnSts52 1000;
BA_ "GenSigCycleTime" SG_ 1590 BMS_CellEquilnSts51 1000;
BA_ "GenSigCycleTime" SG_ 1590 BMS_CellEquilnSts50 1000;
BA_ "GenSigCycleTime" SG_ 1590 BMS_CellEquilnSts5 1000;
BA_ "GenSigCycleTime" SG_ 1590 BMS_CellEquilnSts49 1000;
BA_ "GenSigCycleTime" SG_ 1590 BMS_CellEquilnSts48 1000;
BA_ "GenSigCycleTime" SG_ 1590 BMS_CellEquilnSts47 1000;
BA_ "GenSigCycleTime" SG_ 1590 BMS_CellEquilnSts46 1000;
BA_ "GenSigCycleTime" SG_ 1590 BMS_CellEquilnSts45 1000;
BA_ "GenSigCycleTime" SG_ 1590 BMS_CellEquilnSts44 1000;
BA_ "GenSigCycleTime" SG_ 1590 BMS_CellEquilnSts43 1000;
BA_ "GenSigCycleTime" SG_ 1590 BMS_CellEquilnSts42 1000;
BA_ "GenSigCycleTime" SG_ 1590 BMS_CellEquilnSts41 1000;
BA_ "GenSigCycleTime" SG_ 1590 BMS_CellEquilnSts40 1000;
BA_ "GenSigCycleTime" SG_ 1590 BMS_CellEquilnSts4 1000;
BA_ "GenSigCycleTime" SG_ 1590 BMS_CellEquilnSts39 1000;
BA_ "GenSigCycleTime" SG_ 1590 BMS_CellEquilnSts38 1000;
BA_ "GenSigCycleTime" SG_ 1590 BMS_CellEquilnSts37 1000;
BA_ "GenSigCycleTime" SG_ 1590 BMS_CellEquilnSts36 1000;
BA_ "GenSigCycleTime" SG_ 1590 BMS_CellEquilnSts35 1000;
BA_ "GenSigCycleTime" SG_ 1590 BMS_CellEquilnSts34 1000;
BA_ "GenSigCycleTime" SG_ 1590 BMS_CellEquilnSts33 1000;
BA_ "GenSigCycleTime" SG_ 1590 BMS_CellEquilnSts32 1000;
BA_ "GenSigCycleTime" SG_ 1590 BMS_CellEquilnSts31 1000;
BA_ "GenSigCycleTime" SG_ 1590 BMS_CellEquilnSts30 1000;
BA_ "GenSigCycleTime" SG_ 1590 BMS_CellEquilnSts3 1000;
BA_ "GenSigCycleTime" SG_ 1590 BMS_CellEquilnSts29 1000;
BA_ "GenSigCycleTime" SG_ 1590 BMS_CellEquilnSts28 1000;
BA_ "GenSigCycleTime" SG_ 1590 BMS_CellEquilnSts27 1000;
BA_ "GenSigCycleTime" SG_ 1590 BMS_CellEquilnSts26 1000;
BA_ "GenSigCycleTime" SG_ 1590 BMS_CellEquilnSts25 1000;
BA_ "GenSigCycleTime" SG_ 1590 BMS_CellEquilnSts24 1000;
BA_ "GenSigCycleTime" SG_ 1590 BMS_CellEquilnSts23 1000;
BA_ "GenSigCycleTime" SG_ 1590 BMS_CellEquilnSts22 1000;
BA_ "GenSigCycleTime" SG_ 1590 BMS_CellEquilnSts21 1000;
BA_ "GenSigCycleTime" SG_ 1590 BMS_CellEquilnSts20 1000;
BA_ "GenSigCycleTime" SG_ 1590 BMS_CellEquilnSts2 1000;
BA_ "GenSigCycleTime" SG_ 1590 BMS_CellEquilnSts19 1000;
BA_ "GenSigCycleTime" SG_ 1590 BMS_CellEquilnSts18 1000;
BA_ "GenSigCycleTime" SG_ 1590 BMS_CellEquilnSts17 1000;
BA_ "GenSigCycleTime" SG_ 1590 BMS_CellEquilnSts16 1000;
BA_ "GenSigCycleTime" SG_ 1590 BMS_CellEquilnSts15 1000;
BA_ "GenSigCycleTime" SG_ 1590 BMS_CellEquilnSts14 1000;
BA_ "GenSigCycleTime" SG_ 1590 BMS_CellEquilnSts13 1000;
BA_ "GenSigCycleTime" SG_ 1590 BMS_CellEquilnSts12 1000;
BA_ "GenSigCycleTime" SG_ 1590 BMS_CellEquilnSts11 1000;
BA_ "GenSigCycleTime" SG_ 1590 BMS_CellEquilnSts10 1000;
BA_ "GenSigCycleTime" SG_ 1590 BMS_CellEquilnSts1 1000;

VAL_ 80 SRS_PassengerBuckleSwitchStatus 0 "Buckled" 1 "Unbuckle " 2 "Not Used" 3 "Not Used
Default value= 0x0";
VAL_ 80 SRS_RightRearBuckleSwitchSts 0 "Buckled " 1 " Unbuckle " 2 "Not Used" 3 "Not Used  
Default value= 0x0";
VAL_ 80 SRS_MiddleRearBuckleSwitchSts 0 "Buckled " 1 " Unbuckle " 2 "Not Used" 3 "Not Used 
Default value= 0x0";
VAL_ 80 SRS_LeftRearBuckleSwitchSts 0 "Buckled " 1 " Unbuckle " 2 "Not Used" 3 "Not Used  
Default value= 0x0";
VAL_ 80 SRS_FrontPsgOccupancy 0 "not occupied" 1 "occupied
Default value= 0x1";
VAL_ 80 SRS_PADIndication 0 "PAB on and Lamp off" 1 "PAB off and Lamp on
Default value= 0x1";
VAL_ 80 SRS_WarningLampStatus 0 "Lamp off" 1 "Lamp on" 2 "Lamp Flashing" 3 "Not Used";
VAL_ 80 SRS_DriverBuckleSwitchStatus 0 "Buckled" 1 "Unbuckle " 2 "Not Used" 3 "Not Used
Default value= 0x0";
VAL_ 80 SRS_CrashOutputStatusCheckSum 0 "(SRS_CrashOutputStatus) XOR 0xF";
VAL_ 80 SRS_CrashOutputStatus 0 "No Crash" 1 "crash " 2 "Not Used";

VAL_ 384 SAS_SASFailure 0 "No Failure" 1 "Failure";
VAL_ 384 SAS_Calibrated 0 "Calibrated" 1 " Not Calibrated";
VAL_ 384 SAS_SteeringAngleValid 0 "Valid " 1 "Invalid";

VAL_ 400 BMS_BattPlsHeagStsFb 0 "������" 1 "�������" 2 "������" 3 "�������" 4 "Ԥ��" 5 "Ԥ��" 6 "Ԥ��" 7 "Ԥ��";
VAL_ 400 BMS_BcuCycWakeupTimer 0 "������" 1 "����ʱ��";
VAL_ 400 BMS_BcuDataUploadReq 0 "No Request" 1 "request";
VAL_ 400 BMS_BattInrHeatMode 0 " ���ȹ���" 1 "��ʻ����" 2 "�������" 3 "������" 4 "���¼���" 5 "ԤԼ����" 6 "��ʱ����" 7 "��ʻ��ȴ" 8 "������ȴ" 9 "�����ȴ" 10 "��ʧ����ȴ";
VAL_ 400 BMS_BattPlsHeatgGearReq 0 "No Request" 1 "һ��" 2 "����" 3 "����";
VAL_ 400 BMS_RlyWlddErr 0 "noerror" 1 "error";
VAL_ 400 BMS_BattUCmdLoc 0 "Ԥ��" 1 "BattPackU" 2 "BattLinkU";
VAL_ 400 BMS_BcuSngPackModSts 0 "no Ready" 1 "Ready";
VAL_ 400 BMS_PwrUpAllw 0 "notallow" 1 "allow";
VAL_ 400 BMS_OperMod 0 "Initializing" 1 "Standby" 2 "PreCharge" 3 "HVActive" 4 "Powerdown" 5 "Failure" 7 "ReadytoSleep";
VAL_ 400 BMS_OBCOperModReq 0 "standby" 1 "Battery  charging" 2 "Battery   heat";
VAL_ 400 BMS_InsulationSts 0 "noerror" 1 "BMSInsulationHVErr" 2 "BMSInsulationIntrErr" 3 "BMSInsulationHVLoadErr";
VAL_ 400 BMS_HVILSts 0 "noerror" 1 "error";
VAL_ 400 BMS_HeatSftySts 0 "no error" 1 "error";
VAL_ 400 BMS_FltRnk 0 "noerror" 1 "faultrank1" 2 "faultrank2" 3 "faultrank3" 4 "faultrank4" 5 "faultrank5" 6 "faultrank6" 7 "faultrank7" 8 "faultrank8";
VAL_ 400 BMS_CrashSts 0 "noerror" 1 "error";

VAL_ 308 GM_MotorStart 0 "Off" 1 "On";
VAL_ 308 GM_KeyOn 0 "Off" 1 "On";
VAL_ 308 GM_MotSpdVld 1 "valid" 0 "Invalid";
VAL_ 308 GM_TorsionalVibrationTqVld 1 "valid" 0 "Invalid";
VAL_ 308 GM_MotTqRealVld 1 "valid" 0 "Invalid";
VAL_ 308 GM_IvtTOver 0 "No error" 1 "error";
VAL_ 308 GM_OperMdl 14 "DisCharge" 13 "Failure" 10 "linkage" 9 "����ͣ ��" 8 "TrqCtl" 6 "nCtlExt" 5 "alOFFsetCal" 4 "UdcCtl" 3 "Standby" 2 "StpPosnCtl" 1 "PreCharge" 0 "Initialization";
VAL_ 308 GM_MotTOver 0 "No error" 1 "error";
VAL_ 308 GM_MotSts 0 "�ĵ�" 1 "����" 2 "�ر�״̬" 3 "׼��״̬";
VAL_ 308 GM_MotNr 0 "";
VAL_ 308 GM_Resolvercalibrstatus 0 "default" 1 "��δ������ѧϰ" 2 "��ѧϰ�ҳɹ�" 3 "��ѧϰ����ʧ��" 4 "��ѧϰ����" 5 "��ѧϰ�ɹ�" 6 "��ѧϰʧ��" 7 "��ѧϰ���󣬵�����������";
VAL_ 308 GM_FltRnk 4 "emergency stop" 3 "No torque output" 2 "derating" 1 "only DTC" 0 "Normal";
VAL_ 308 GM_ASCflag 0 "No Error" 1 "ASC";

VAL_ 510 PCU_GM_MotModReq 14 "DisCharge" 10 "linkage" 9 "Auxiliary shutdown" 8 "TrqCtl" 6 "nCtlExt" 5 "alOFFsetCal" 4 "UdcCtl" 3 "HVactive" 2 "StpPosnCtl" 0 "Initialization";
VAL_ 510 PCU_GM_SurgeDamperEna 1 "enable" 0 "disable";
VAL_ 510 PCU_GM_ResoCaliAllow 0 "Default" 1 "Not allow" 2 "allow" 3 "resostpflg";
VAL_ 510 PCU_GM_nCtlExtCfg 0 "default" 1 "Kp adaption" 2 "Motor Idle" 3 "EV Creeping" 4 "HEV Creeping" 5 "Engine Start
0x6=Engine Stop" 7 "Series";

VAL_ 1467 TM1_VcuIpuErrLamp 0 "OFF";
VAL_ 1467 TM1_RmipuTqLimFlgWithInpU 0 "not Active" 1 "active";
VAL_ 1467 TM1_MotSts 0 "�ĵ�" 1 "����" 2 "�ر�״̬" 3 "׼��״̬";
VAL_ 1467 TM1_MotNr 0 "";

VAL_ 811 DCDC_ResetSts 0 "Valid" 1 "GW����λ" 2 "�����жϸ�λ" 3 "�����㸴λ����" 4 "Reserve" 7 "Invalid";
VAL_ 811 DCDC_Sts 0 "Off" 1 "working" 2 "stop" 3 "Reserved";
VAL_ 811 DCDC_OverT 0 "noprotected" 1 "protectedhappened";
VAL_ 811 DCDC_FltRnk 0 "�޹���" 1 "һ������" 2 "��������" 3 "��������";
VAL_ 811 DCDC_StsWarning 0 "normal" 1 "failure";
VAL_ 811 DCDC_OperMod 6 "Failure" 5 "Reserved" 4 "Boost
0x3=Buck" 2 "Standby" 1 "Precharge
0x0=OFF";

VAL_ 276 TCU_ShiftPostionValid1 0 "valid" 1 "invalid";
VAL_ 276 TCU_GearShiftPosition1 0 "Parking" 1 "Reverse" 2 "Neutral" 3 "D" 4 "D3" 5 "D2" 6 "L" 7 "M/S" 8 "Reserved" 13 " Initial value" 14 " Unreliable" 15 " Invalid";
VAL_ 276 PCU_TM1DynTqUnloadAllwd 0 "Not Allowed" 1 "Allowed";
VAL_ 276 PCU_TM1_SurgeDamperEna 1 "enable" 0 "disable";
VAL_ 276 PCU_TM1_ResoCaliAllow 0 "Default" 1 "Not allow" 2 "allow" 3 "resostpflg";
VAL_ 276 PCU_TM1_nCtlExtCfg 0 "default" 1 "Kp adaption" 2 "Motor Idle" 3 "EV Creeping" 4 "HEV Creeping" 5 "Engine Start";
VAL_ 276 PCU_TM1_MotModReq 14 "DisCharge" 10 "linkage" 9 "reserve" 8 "TrqCtl" 6 "nCtlExt" 5 "alOFFsetCal" 4 "UdcCtl" 3 "HVactive" 0 "Initialization";

VAL_ 342 PCU_CoastRgnTarWhlRearQlfr 0 "NotIntialized" 1 "Normal" 2 "Faulty";
VAL_ 342 TCU_K3_CluClsActiveVld 0 "Valid" 1 "Invalid";
VAL_ 342 TCU_K3_CluClsActive 0 "clutch disengage��toque can��t be tasmitted" 1 "clutch engage��toque can be tasmitted";
VAL_ 342 PCU_CoastRgnTarWhlFrntQlfr 0 "NotIntialized" 1 "Normal" 2 "Faulty";

VAL_ 576 PCU_PTMode 0 "invalid" 1 "SHEV" 2 "PHEV" 3 "EV";
VAL_ 576 PCU_ImmoFeedback 3 "Failed" 2 "Success" 1 "Authenticating" 0 "Inactive";
VAL_ 576 PCU_ImmoConfiguration 1 "IMMO" 0 "No IMMO";
VAL_ 576 PCU_GearShiftStyleReq 0 " Initial" 1 "Slow" 2 "Medium" 3 "Fast";

VAL_ 583 APA_ESP_BrakeFunctionMode 0 "None" 1 "ReducedFunction" 2 "FullFunction" 3 "Invalid";
VAL_ 583 APA_PtTrqReqValid 0 "Invalid" 1 "Valid";
VAL_ 583 APA_FunctionOnOffSts 0 " Off" 1 " searching" 2 "Remote Vertical In&Out  On" 3 "RemoteByAPP On" 4 "RemoteByOneKey On" 5 "Remote function on" 6 "APAparkin" 7 "APAparkout" 8 "RemoteByAPPVerticalInOutOn" 9 "4G Remote Vertical In&Out On" 10 "4G Remote ParkingOut" 11 "4G Remote function on" 12 "4G ParkHoming" 13 "4G Parking On" 14 "HZPParkin" 15 "HZPParkout" 16 "AVPParkin" 17 "AVPParkout" 18 "Remotefullfunction" 19 "RADS" 20 "RemotebyAPPparkingout";
VAL_ 583 APA_TrqHoldForTCUCl 0 "Off" 1 "On";
VAL_ 583 APA_TCUClutchCombinationReq 0 "" 1 "";
VAL_ 583 APA_APAOnOff 0 "OFF" 1 "ON";
VAL_ 583 APA_TurnLightsCommand 0 "No Request" 1 "LeftLight On" 2 "RightLight On" 3 "DoubleLights On  ";
VAL_ 583 APA_ParkNotice 0 "IDLE" 1 "pPSC_Search_R" 2 "pPSC_Search_L" 3 "cPSC_Search_R" 4 "cPSC_Search_L" 5 "pPSC_PS_OK_Pos_NOK_R" 6 "pPSC_PS_OK_Pos_NOK_L" 7 "cPSC_PS_OK_Pos_NOK_R" 8 "cPSC_PS_OK_Pos_NOK_L" 9 "pPSC_PS_OK_Stop_R" 10 "pPSC_PS_OK_Stop_L" 11 "cPSC_PS_OK_Stop_R" 12 "cPSC_PS_OK_Stop_L" 13 "pPSC_PS_OK_R_Gear_R" 14 "pPSC_PS_OK_R_Gear_L" 15 "cPSC_PS_OK_R_Gear_R" 16 "cPSC_PS_OK_R_Gear_L" 17 "PSC_PS_OK_Reactive" 18 "ePSC_PS_OK_R_Gear_R" 19 "POC_OK_R" 20 "ePSC_PS_OK_R_Gear_L" 21 "POC_Turn_ON_Indicator" 22 "pPSC_move_bwd_R" 23 "pPSC_move_bwd_L" 24 "cPSC_move_bwd_R" 25 "cPSC_move_bwd_L" 26 "POC_move_bwd_R" 27 "POC_move_bwd_L" 28 "pPSC_move_fwd_R" 29 "pPSC_move_fwd_L" 30 "cPSC_move_fwd_R" 31 "cPSC_move_fwd_L" 32 "POC_move_fwd_R" 33 "POC_move_fwd_L" 34 "Guidance_Insert_D_Gear" 35 "Guidance_Insert_R_Gear" 36 "Guidance_Stop" 37 "Guidence_Wait_for_steeringcomplete" 38 "Guidence_Slow_Down" 39 "Parking maneuver completed" 40 "reserved" 41 "Abort_ESP Intervention" 42 "Abort_Speed too high" 43 "Abort_Hand on detect" 44 "Abort_max number of maneouvres reached" 45 "Abort_Trailor attached" 46 "Abort_ User deactivated" 47 "Failure_Sensors Blinded" 48 "APA internal Failure" 49 "APA external Failure" 50 "Searching_Slow_Down" 51 "Abort_GuidanceTimeout" 52 "Abort_OffTrack" 53 " Abort_PS too small" 54 "Abort_Other_reasons" 55 "POC_No front obstacle" 56 "Searching forPakingSlotRightEchelon" 57 "Searching forPakingSlotLeftEchelon" 58 "ParkingSpaceFoundRightEchelon" 59 "ParkingSpaceFoundLeftEchelon";
VAL_ 583 APA_IncreasePressureReq 0 "Not request" 1 "Request";
VAL_ 583 APA_ButtonPress 0 " PSC button idle" 1 " PSC button pressed";
VAL_ 583 APA_RemoteOnOff 0 "OFF" 1 "On" 2 "Not used" 3 "Invalid ";
VAL_ 583 APA_EmergenceBrake 0 "Not request" 1 "Request";
VAL_ 583 APA_indication 0 " No function is active " 1 " pPSC is active" 2 " cPSC is active " 3 " POC is active" 4 "ePSC is active" 5 "Invalid";
VAL_ 583 APA_ErrorStatus 0 "No Error" 1 "Error";
VAL_ 583 APA_SteeringAngleReqProtection 0 "No Request" 1 "Request EPS control" 2 "EPS control active";
VAL_ 583 APA_HSAHDforbidden 0 "Not request" 1 "Request";
VAL_ 583 APA_ESPDecompressionModel 0 "Slow decompression" 1 "fast decompression";
VAL_ 583 APA_AccPedShieldReq 0 "Unshield" 1 "Shield";
VAL_ 583 APA_SlotNotice 0 " IDLE" 1 " Parking in" 2 "L_Per_slot" 3 "R_Per_slot" 4 "L_Par_slot" 5 " R_Par_slot" 6 "L_Fishbone_slot" 7 " R_Fishbone_slot" 8 "L_Parking out indication" 9 "R_Parking out indication" 10 "Rearview" 11 "360 surround view" 12 "reserved" 15 "Invalid";
VAL_ 583 APA_DynamicSlotWarning 0 "No warning" 1 "Warning";
VAL_ 583 APA_PrefillReq 0 "Not request" 1 "Request";
VAL_ 583 APA_Activation_Status 0 "APA_Off" 1 "APA_Nonactivated" 2 "APA_Actived" 3 "APA_GuidanceActive" 4 "APA_Completed" 5 "APA_Failure" 6 "APA_Terminated" 7 "APA_Suspend";
VAL_ 583 APA_EngineTrqReqEnable 0 "Not Enable" 1 "Enable";
VAL_ 583 APA_LSCAction 0 "OFF" 1 "ON";
VAL_ 583 APA_TransPRNDShiftEnable 0 "Not Enable" 1 "Enable";
VAL_ 583 APA_TransPRNDShiftReqValid 0 "Invalid" 1 "Valid";
VAL_ 583 APA_TransPRNDShiftRequest 0 "No Request" 1 "Park " 2 " Reverse " 3 "Neutral" 4 "Drive" 5 " invalid" 6 "reserved";
VAL_ 583 APA_TargetAccelerationValid 0 " not enable" 1 " enable";
VAL_ 583 APA_EPBrequestValid 0 "Invalid" 1 "Valid";
VAL_ 583 APA_EPBrequest 0 "No Request" 1 "RequestBrake" 2 "RequestRelase";

VAL_ 610 PEPS_RemoteStartKeyStatus 0 "invalid" 1 " pressed" 2 "not pressed " 3 "reserve";
VAL_ 610 PEPS_APA_PowerMirrorFoldFeedback 0 "InActive " 1 "Fold" 2 "Open" 3 "Reserved";
VAL_ 610 PEPS_APARemoteParkingOff 0 " Not Pressed" 1 " Pressed";
VAL_ 610 PEPS_KeyStandbyPositionIndicator 0 "Inactive" 1 "ON";
VAL_ 610 PEPS_PEPSFailStatus 0 "No Error" 1 "Error";
VAL_ 610 PEPS_PowerDistributionFaultBit 0 "No Error" 1 "Error";
VAL_ 610 PEPS_IMMOFeedback 0 "Inactive����֤״̬" 1 "Authenticating��֤��
0x2=Success�ɹ�" 3 "Failedʧ��";
VAL_ 610 PEPS_EngineStartupInhibitFB 0 "inactive " 1 "Inhibit succes";
VAL_ 610 PEPS_RemoteStartFeedback 0 " �޷���" 1 " ����ɹ�" 2 " ���������������" 3 " ������������" 4 " ���Ż�����ǻ�������δ�ر�" 5 " ң��Կ���ڳ���" 6 " ��������" 7 " ��������ƹ⼤��" 8 " ��������P��" 9 " ���ٲ�Ϊ0" 10 " �������Ѿ�����" 11 " ������ɲδ�н�" 12 " ��������" 13 " ���ϵͳ����" 14 " ����������ѹ������" 15 " ��������ȴҺ�¶ȹ���" 16 " ����ϵͳ����" 17 " ����ʱ�䵽����Ϩ��" 18 " �����¶ȹ���" 19 "�ܱ߷���δ�������״̬" 20 "Զ��/ң��Ϩ��ɹ�" 21 "���ʱ���Ѵ�30min ����" 22 " Reserved";
VAL_ 610 PEPS_EngineStartupInhibitSts 0 "Not inhibit " 1 "Inhibit";
VAL_ 610 PEPS_PowerDistributionStatus 0 " OFF" 1 " ACC" 2 " ON" 3 " Start.";
VAL_ 610 PEPS_UnallowStartSignal_Not_PN 0 "Inactive" 1 "δ��P/N��";
VAL_ 610 PEPS_IMMOFailedAlarmsignal 0 "Inactive" 1 "IMMO��EMS��֤ʧ��";
VAL_ 610 PEPS_UnallowStart_ESCL_LOCK 0 "Inactive" 1 "ESCLδ����";
VAL_ 610 PEPS_UnallowStart_ESCL_Error 0 "Inactive" 1 "ESCL����";
VAL_ 610 PEPS_StartIndicatorSignal 0 "Inactive" 1 "������ƶ�̤����ʾ";
VAL_ 610 PEPS_StartupButtonSignal 0 " OFF" 1 " ON" 2 " Error" 3 " ������";
VAL_ 610 PEPS_APA_CloseWinFeedback 0 "InActive " 1 "Success " 2 "Failed " 3 "Reserved";
VAL_ 610 PEPS_RemoteControlACReq 0 "No Request" 1 "AC Start" 2 "Reserved";
VAL_ 610 PEPS_RemoteAPADoneKeyOffReq 0 " invalid" 1 " request" 2 " not request" 3 " reserved";
VAL_ 610 PEPS_APA_Engine0ffFeedback 0 "InActive " 1 "Success " 2 "Failed " 3 "Reserved";
VAL_ 610 PEPS_APA_LockFeedback 0 "InActive " 1 "Success " 2 "Failed " 3 "Reserved";
VAL_ 610 PEPS_APARemoteParkingOn 0 " Not Pressed" 1 " Pressed";

VAL_ 632 ESP_YawRateValid 0 "Valid" 1 "Invalid";

VAL_ 664 BCM_TrunkUnlockReq 0 "No request" 1 "Trunk unlock";
VAL_ 664 PEPS_LuggageUnlockSignal 0 " Inactive" 1 " ң�����������" 2 " PE���������" 3 " ������";
VAL_ 664 BCM_DriverDoorLockStatus 0 "Lock" 1 "Unlock" 2 "Not used" 3 "Error";
VAL_ 664 BCM_PassengerDoorLockStatus 0 "Lock" 1 "Unlock" 2 "Not used" 3 "Error";
VAL_ 664 BCM_LeftRearDoorStatus 0 "Close" 1 "Open";
VAL_ 664 PEPS_SmartWelcomeLightStaus 0 "inactive" 1 "On" 2 "Off" 3 "Reserved";
VAL_ 664 PEPS_TrunkKeyStatus 0 "invalid" 1 " pressed" 2 "not pressed " 3 "reserve";
VAL_ 664 PEPS_UnLockKeyStatus 0 "invalid" 1 " pressed" 2 "not pressed " 3 "reserve";
VAL_ 664 PEPS_LockKeyStatus 0 "invalid" 1 " pressed" 2 "not pressed " 3 "reserve";
VAL_ 664 PEPS_SmartTrunkUlockRemind 0 " Inactive" 1 "SlowFlash" 2 "FastFlash" 3 "Reserved";
VAL_ 664 PEPS_UnlockSignal 0 " Inactive" 1 " ң�ؽ���" 2 " ��ǰPE����" 3 " ��ǰPE����";
VAL_ 664 PEPS_LockSignal 0 " Inactive" 1 " ң�ر���" 2 " PE����" 3 " ������";
VAL_ 664 PEPS_KeyNumber 0 "invalid" 1 "Key1-Key6" 7 "Reserved";
VAL_ 664 PEPS_KeyAuthenticationStatus 0 "Inactive����֤״̬" 1 "start��֤��" 2 "Success�ɹ�" 3 "failedʧ��";
VAL_ 664 PEPS_Easy_open 0 "no command" 1 "�Զ���Ӧ�ź�";
VAL_ 664 PEPS_Welcomelamp 0 "Inactive" 1 " OFF" 2 "ON" 3 "Reserved";
VAL_ 664 PEPS_TrunkRequestSignal 0 "OFF" 1 " �����䰴ť������";
VAL_ 664 PEPS_KeyLearningSignal 0 " Inactive��ѧϰ״̬" 1 " Startѧϰ��" 2 " Success�ɹ�" 3 " Failedʧ��";
VAL_ 664 PEPS_EasyOpenOrginalSignal 0 " �Ų�������δ����" 1 "�Ų�����������";
VAL_ 664 PEPS_RemoteFailedAlarmSignal 0 "Inactive" 1 "Կ����֤ʧ��";
VAL_ 664 PEPS_SearchCarSignal 0 "Inactive" 1 "ON";

VAL_ 793 OBC_ResetSts 0 "Valid" 1 "GW����λ" 2 "�����жϸ�λ" 3 "�����㸴λ����" 4 "Reserve" 7 "Invalid";
VAL_ 793 OBC_MILONReq 0 " no request" 1 "request";
VAL_ 793 DCAC_DcacOperMod 0 "��" 1 "����" 2 "���ڷŵ�" 3 "����ŵ�" 4 "���ڳ���ͬʱ�ŵ�" 5 "Failure";
VAL_ 793 DCAC_DcacFltRnk 0 "�޹���" 1 "һ������" 2 "��������" 3 "��������";
VAL_ 793 OBC_ObcTOverWarn 0 "Normal" 1 "Over";
VAL_ 793 OBC_HVPwrOnReq 0 "No Req" 1 "Req";
VAL_ 793 OBC_ObcWakeupSrc 0 "CPwakeup" 1 "CANwakeup" 2 "ChargeCoverWakeUp�����ǰ廽�ѣ�" 3 "KL15";
VAL_ 793 OBC_ObcS2Sts 0 "turnoff" 1 "turnon";
VAL_ 793 OBC_ObcFltRnk 0 "�޹���" 1 "һ������" 2 "��������" 3 "��������";
VAL_ 793 OBC_ObcCpValVld 0 "invalid" 1 "valid";
VAL_ 793 OBC_ObcChrgSts 0 "Init" 1 "Standby" 2 "working" 3 "Derating" 4 "Failure" 5 "��" 6 "PreSleep";
VAL_ 793 OBC_ChargeCoverSts 0 "Closed(��)" 1 "Open������";

VAL_ 804 TMS_ClearDiagnositicInfo 0 "Normal" 1 "Not used" 2 "TMS request EMS to clear DiagNosticInfo" 3 "TMS has cleared Diag info per EMS request";
VAL_ 804 TMS_Motor_Temp_inValid 0 "Valid" 1 "Invalid";
VAL_ 804 TMS_MILONReq 0 "No request" 1 "Request";

VAL_ 838 EMS_ReFueldSts 0 "Inactive" 1 "Acitve";
VAL_ 838 EMS_NormalDteskEvapdiareq 0 "No Request" 1 "Request";
VAL_ 838 EMS_ClearTMSDiagnositicInfo 0 "Normal" 1 "Not used" 2 "EMS request TMS to clear DiagNosticInfo" 3 "EMS has cleared Diag info per TMS request";
VAL_ 838 EMS_CleaGPEUDiagnosticInfo 0 "Normal" 1 "Not used" 2 "EMS request GPEU to clear" 3 "EMS has cleared diag into per GPEU request";
VAL_ 838 EMS_EngStrtInhb 3 "3rd priority" 2 "2nd priority" 1 "1st priority" 0 "no request";
VAL_ 838 EMS_CoolantThermostatDC 0 "OFF " 1 "10_Percent" 2 "20_Percent" 3 "30_Percent" 4 "40_Percent" 5 "50_Percent" 6 "60_Percent" 7 "70_Percent" 8 "80_Percent" 9 "90_Percent" 10 "Full_ON" 15 "unkownposition";
VAL_ 838 EMS_flgWtrPmpErr 0 "No error" 1 "Error";
VAL_ 838 EMS_EngTargetCoolantTemp 0 "-60~120��" 63 "Invalid";
VAL_ 838 EMS_ClearOBCDiagnosticInfo 0 "Normal" 1 "Not used" 2 "EMS request OBC to clear" 3 "EMS has cleared diag into per OBC request";
VAL_ 838 EMS_EngProtectionActive 0 "Inactive" 1 "������������30��δ���С�" 2 "������������60��δ���С�" 3 "������������90��δ���С�";
VAL_ 838 EMS_MILIndcdLightInfo 0 "off" 1 "EMS MILIndcdON" 2 "PCU/PDCU MILIndcdON" 3 "PEU  MILIndcdON" 4 " EPBi/IBCU   MILIndcdON" 5 "BMS  MILIndcdON" 6 "OBC  MILIndcdON" 7 "TMS  MILIndcdON" 8 "DCDC  MILIndcdON" 9 "TCU MILIndcdON" 10 "Reserved";
VAL_ 838 EMS_EGRDia 0 "������" 1 "EGR�������";
VAL_ 838 Ems_GpfSrvRgnReq 0 "No Request" 1 "Request";
VAL_ 838 EMS_DenominatorCntr2 0 "Not request" 1 "request";
VAL_ 838 EMS_DenominatorCntr1 0 "Not request" 1 "request";
VAL_ 838 EMS_ClearRPEUDiagnosticInfo 0 "Normal" 1 "Not Used" 2 "EMS request RMIPU to clear Diag Info" 3 "EMS has cleared Diag info per RMIPU request";
VAL_ 838 Ems_EngRvsTowingReq 0 "No Request" 1 "Request";
VAL_ 838 Ems_EngFuCutOffFbd 0 "NoForbid" 1 "Forbid";
VAL_ 838 Ems_GpfActvRgnReq 0 "No Request" 1 "Request";
VAL_ 838 Ems_FltRnk 0 "NoFault" 1 "startproble" 2 "torquelimited" 3 "limphome" 4 "needshutdown";
VAL_ 838 EMS_CleaDPEUDiagnosticInfo 0 "Normal" 1 "Not used" 2 "EMS request PEU to clear" 3 "EMS has cleared diag into per PEU request";
VAL_ 838 EMS_PwrTrainStopTime 0 "0-65533s" 65534 "65534 or >65534" 65535 "invalid.
This sig/l identifies the amount of time from PwrTrain stop to the  next PwrTrain running. ";
VAL_ 838 EMS_PwrTrainRunningTime 0 "0-65533s" 65534 "65534 or >65534" 65535 "invalid.
This sig/l identifies the amount of time from PwrTrain running to the  PwrTrain stop . ";
VAL_ 838 EMS_ClearPCUDiagnosticInfo 0 "Normal" 1 "Not used" 2 "EMS request PCU to clear" 3 "EMS has cleared diag into per PCU request";
VAL_ 838 EMS_ClearIBCUDiagnosticInfo 0 "Normal" 1 "Not used" 2 "EMS request IBCU to clear" 3 "EMS has cleared diag into per IBCU request";
VAL_ 838 EMS_ClearBMSDiagnosticInfo 0 "Normal" 1 "Not used" 2 "EMS request BMS to clear" 3 "EMS has cleared diag into per BMS request";
VAL_ 838 EMS_PFCCCondition 0 "Not Achieved" 1 "Achieved";
VAL_ 838 EMS_GPF_State 0 "Ĭ��ֵ������ʾ" 1 "GPF��Ҫ����" 2 "GPF��������" 3 "GPF������ ��" 4 "GPF�����޷�����" 5 "reserved" 6 "reserved" 7 "invalid";
VAL_ 838 EMS_OxygenSensorDia 0 "������" 1 "���������������";
VAL_ 838 EMS_LowPreOilPumpProRemind 0 "������ʾ��" 1 "��ȼ�ͺľ������������ޣ��뼰ʱ���͡�";
VAL_ 838 EMS_EngProtectionRemind 0 "������ʾ��" 1 "������������30��δ���У������л��춯ģʽ��ʻ3���ӡ�" 2 "������������60��δ���У��ѿ���3�����Ȼ����ܡ�" 3 "������������90��δ���У��ѿ���3�����Ȼ����ܡ�";
VAL_ 838 EMS_SVSLamp 1 "ON" 0 "OFF";
VAL_ 838 EMS_OilPressureSts 0 "no error" 1 "error";
VAL_ 838 EMS_MILIndcd 3 "Error" 2 "Reserved" 1 "ON" 0 "Off";
VAL_ 838 EMS_FuelCapLeakDisplay 1 "ON" 0 "OFF";

VAL_ 870 AC_TargetTorque 0 "-0~25.4" 255 "Invalid";
VAL_ 870 AC_WorkSts 0 "OFF" 1 "Defrost_Defog" 2 "fast Cool" 3 "fast Warm" 4 "Opportunistic Cool" 5 "Opportunistic Warm" 6 "Large Heating" 7 "Reserved";
VAL_ 870 AC_PTCStatus 0 "OFF" 1 "1��" 2 "2��" 3 "3��";
VAL_ 870 AC_SolenoidCurrent 0 "0~1.016";
VAL_ 870 AC_CompressorStatus 0 "OFF" 1 "ON";
VAL_ 870 AC_ACPre 0 "0~40.94" 4095 "Invalid";
VAL_ 870 AC_AC_ReqValid 0 " Valid" 1 " Invalid";
VAL_ 870 AC_FrReqWindLevel 0 "OFF" 1 "Level1" 2 "Level2" 3 "Level3" 4 "Level4" 5 "Level5" 6 "Level6" 7 "Level7" 8 "Level8" 9 "Level0��Ҷ" 10 "Reserved" 11 "Reserved" 12 "Reserved" 13 "Reserved" 14 "Reserved" 15 "Invaild";
VAL_ 870 AC_FrReqWindLevelVD 0 "Valid" 1 "Invalid";
VAL_ 870 AC_AC_Req 0 "OFF" 1 "ON";
VAL_ 870 AC_EnvironmentalTemp 0 "-40~87��" 255 "Invalid";
VAL_ 870 AC_EnvironmentalTempVD 0 "Valid" 1 "Invalid";

VAL_ 1302 HU_AirHumidityValid 0 "Valid" 1 "Invalid";
VAL_ 1302 HU_AirHumidity 0 "0~100" 101 "reserved" 127 "Invalid";
VAL_ 1302 HU_LeaveMaintainMileage 0 "0~100000" 100001 "Reserved" 1048575 "Invalid";
VAL_ 1302 HU_LeaveMaintainDay 0 "0~3100��" 3101 "Reserved" 4095 "Invalid";
VAL_ 1302 HU_MaintainRemindReq 0 "������" 1 "����Ԥ������" 2 "����������ʾ����" 3 "Invalid";
VAL_ 1302 HU_LocalTimeSystem 0 "24h" 1 "12h" 2 "Reserved" 3 "Invalid";
VAL_ 1302 HU_LocalTimeValid 0 "Valid" 1 "Not Valid";
VAL_ 1302 HU_CurrentLocationLatitude 134217727 "";
VAL_ 1302 HU_CurrentLocationLongitude 268435455 "";
VAL_ 1302 HU_CurrentLocationValid 0 "Valid" 1 "Not Valid";

VAL_ 1304 BCM_CarMode 0 "���������û�ģʽ " 1 " �������ڹ���ģʽ" 2 "������������ģʽ" 3 " Reserved";

VAL_ 1328 IP_FuelLevel 0 " FUEIL��E" 1 " E < FUEIL ��1/8" 2 " 1/8< FUEIL ��1/4" 3 " 1/4< FUEIL ��3/8" 4 "3/8< FUEIL ��1/2" 5 "  1/2< FUEIL ��5/8" 6 " 5/8< FUEIL ��3/4" 7 " 3/4< FUEIL ��7/8" 8 " 7/8< FUEIL ��F";
VAL_ 1328 IP_EngineOffTime 0 "0-65533s" 65534 "65534 or >65534" 65535 "invalid";

VAL_ 1333 BMS_BcuCycWakupSts 0 "NotCycWakeup" 1 "CycWakeup";
VAL_ 1333 BMS_SosMixSt 0 "�޹���" 1 "��ѹ����" 2 "���ع���" 4 "ѹ�����" 8 "ѹ������" 16 "��ѹ�͹���" 32 "��������" 64 "���¹���" 128 "�²����" 256 "��Ե����" 512 "����ͨ�Ź���" 1024 "��ѹ�����߹���" 2048 "��ѹ�����Թ���" 4096 "�¶Ȳ����߿�·" 8192 "�¶Ȳ����߶�·" 16384 "�¶Ȳɼ�������" 32768 "Ԥ��";
VAL_ 1333 BMS_DataUploadReq 0 "no request" 1 "request";
VAL_ 1333 BMS_Wkpmod 0 "�޻���" 1 "WakeUp����" 2 "CC����" 3 "NTCR����" 4 "����������" 5 "��ʧ�ش���������" 6 "�ְ廽��";
VAL_ 1333 BMS_SwitchSts 0 "δ����(��δ��)" 1 "����(����)";
VAL_ 1333 BMS_PckPrssrSts 0 "����������" 1 "�����������1" 2 "�����������2" 3 "�����������3��";
VAL_ 1333 BMS_HeatWarngSts 0 "����״̬" 1 "һ��Ԥ��" 2 "����Ԥ��" 3 "����Ԥ��";
VAL_ 1333 BMS_HeatSftyStsRMU 0 "No error" 1 "error";

VAL_ 1541 BMS_SOCOverFlgDisp 0 "NO" 1 "YES";
VAL_ 1541 BMS_VehCANErr 0 "Noerror" 1 "CANerror";
VAL_ 1541 BMS_OverCrrtDischrg 0 "Noerror" 1 "overcurrent";
VAL_ 1541 BMS_OverCrrtChrg 0 "Noerror" 1 "overcurrent";

VAL_ 1590 BMS_CellEquilnSts168 0 "NO" 1 "YES";
VAL_ 1590 BMS_CellEquilnSts167 0 "NO" 1 "YES";
VAL_ 1590 BMS_CellEquilnSts166 0 "NO" 1 "YES";
VAL_ 1590 BMS_CellEquilnSts165 0 "NO" 1 "YES";
VAL_ 1590 BMS_CellEquilnSts164 0 "NO" 1 "YES";
VAL_ 1590 BMS_CellEquilnSts163 0 "NO" 1 "YES";
VAL_ 1590 BMS_CellEquilnSts162 0 "NO" 1 "YES";
VAL_ 1590 BMS_CellEquilnSts161 0 "NO" 1 "YES";
VAL_ 1590 BMS_CellEquilnSts160 0 "NO" 1 "YES";
VAL_ 1590 BMS_CellEquilnSts159 0 "NO" 1 "YES";
VAL_ 1590 BMS_CellEquilnSts158 0 "NO" 1 "YES";
VAL_ 1590 BMS_CellEquilnSts157 0 "NO" 1 "YES";
VAL_ 1590 BMS_CellEquilnSts156 0 "NO" 1 "YES";
VAL_ 1590 BMS_CellEquilnSts155 0 "NO" 1 "YES";
VAL_ 1590 BMS_CellEquilnSts154 0 "NO" 1 "YES";
VAL_ 1590 BMS_CellEquilnSts153 0 "NO" 1 "YES";
VAL_ 1590 BMS_CellEquilnSts152 0 "NO" 1 "YES";
VAL_ 1590 BMS_CellEquilnSts151 0 "NO" 1 "YES";
VAL_ 1590 BMS_CellEquilnSts150 0 "NO" 1 "YES";
VAL_ 1590 BMS_CellEquilnSts149 0 "NO" 1 "YES";
VAL_ 1590 BMS_CellEquilnSts148 0 "NO" 1 "YES";
VAL_ 1590 BMS_CellEquilnSts147 0 "NO" 1 "YES";
VAL_ 1590 BMS_CellEquilnSts146 0 "NO" 1 "YES";
VAL_ 1590 BMS_CellEquilnSts145 0 "NO" 1 "YES";
VAL_ 1590 BMS_CellEquilnSts144 0 "NO" 1 "YES";
VAL_ 1590 BMS_CellEquilnSts143 0 "NO" 1 "YES";
VAL_ 1590 BMS_CellEquilnSts142 0 "NO" 1 "YES";
VAL_ 1590 BMS_CellEquilnSts141 0 "NO" 1 "YES";
VAL_ 1590 BMS_CellEquilnSts140 0 "NO" 1 "YES";
VAL_ 1590 BMS_CellEquilnSts139 0 "NO" 1 "YES";
VAL_ 1590 BMS_CellEquilnSts138 0 "NO" 1 "YES";
VAL_ 1590 BMS_CellEquilnSts137 0 "NO" 1 "YES";
VAL_ 1590 BMS_CellEquilnSts136 0 "NO" 1 "YES";
VAL_ 1590 BMS_CellEquilnSts135 0 "NO" 1 "YES";
VAL_ 1590 BMS_CellEquilnSts134 0 "NO" 1 "YES";
VAL_ 1590 BMS_CellEquilnSts133 0 "NO" 1 "YES";
VAL_ 1590 BMS_CellEquilnSts132 0 "NO" 1 "YES";
VAL_ 1590 BMS_CellEquilnSts131 0 "NO" 1 "YES";
VAL_ 1590 BMS_CellEquilnSts130 0 "NO" 1 "YES";
VAL_ 1590 BMS_CellEquilnSts129 0 "NO" 1 "YES";
VAL_ 1590 BMS_CellEquilnSts128 0 "NO" 1 "YES";
VAL_ 1590 BMS_CellEquilnSts127 0 "NO" 1 "YES";
VAL_ 1590 BMS_CellEquilnSts126 0 "NO" 1 "YES";
VAL_ 1590 BMS_CellEquilnSts125 0 "NO" 1 "YES";
VAL_ 1590 BMS_CellEquilnSts124 0 "NO" 1 "YES";
VAL_ 1590 BMS_CellEquilnSts123 0 "NO" 1 "YES";
VAL_ 1590 BMS_CellEquilnSts122 0 "NO" 1 "YES";
VAL_ 1590 BMS_CellEquilnSts121 0 "NO" 1 "YES";
VAL_ 1590 BMS_CellEquilnSts120 0 "NO" 1 "YES";
VAL_ 1590 BMS_CellEquilnSts119 0 "NO" 1 "YES";
VAL_ 1590 BMS_CellEquilnSts118 0 "NO" 1 "YES";
VAL_ 1590 BMS_CellEquilnSts117 0 "NO" 1 "YES";
VAL_ 1590 BMS_CellEquilnSts116 0 "NO" 1 "YES";
VAL_ 1590 BMS_CellEquilnSts115 0 "NO" 1 "YES";
VAL_ 1590 BMS_CellEquilnSts114 0 "NO" 1 "YES";
VAL_ 1590 BMS_CellEquilnSts113 0 "NO" 1 "YES";
VAL_ 1590 BMS_CellEquilnSts112 0 "NO" 1 "YES";
VAL_ 1590 BMS_CellEquilnSts111 0 "NO" 1 "YES";
VAL_ 1590 BMS_CellEquilnSts110 0 "NO" 1 "YES";
VAL_ 1590 BMS_CellEquilnSts109 0 "NO" 1 "YES";
VAL_ 1590 BMS_CellEquilnSts108 0 "NO" 1 "YES";
VAL_ 1590 BMS_CellEquilnSts107 0 "NO" 1 "YES";
VAL_ 1590 BMS_CellEquilnSts106 0 "NO" 1 "YES";
VAL_ 1590 BMS_CellEquilnSts105 0 "NO" 1 "YES";
VAL_ 1590 BMS_CellEquilnSts104 0 "NO" 1 "YES";
VAL_ 1590 BMS_CellEquilnSts103 0 "NO" 1 "YES";
VAL_ 1590 BMS_CellEquilnSts102 0 "NO" 1 "YES";
VAL_ 1590 BMS_CellEquilnSts101 0 "NO" 1 "YES";
VAL_ 1590 BMS_CellEquilnSts100 0 "NO" 1 "YES";
VAL_ 1590 BMS_CellEquilnSts99 0 "NO" 1 "YES";
VAL_ 1590 BMS_CellEquilnSts98 0 "NO" 1 "YES";
VAL_ 1590 BMS_CellEquilnSts97 0 "NO" 1 "YES";
VAL_ 1590 BMS_CellEquilnSts96 0 "NO" 1 "YES";
VAL_ 1590 BMS_CellEquilnSts95 0 "NO" 1 "YES";
VAL_ 1590 BMS_CellEquilnSts94 0 "NO" 1 "YES";
VAL_ 1590 BMS_CellEquilnSts93 0 "NO" 1 "YES";
VAL_ 1590 BMS_CellEquilnSts92 0 "NO" 1 "YES";
VAL_ 1590 BMS_CellEquilnSts91 0 "NO" 1 "YES";
VAL_ 1590 BMS_CellEquilnSts90 0 "NO" 1 "YES";
VAL_ 1590 BMS_CellEquilnSts89 0 "NO" 1 "YES";
VAL_ 1590 BMS_CellEquilnSts88 0 "NO" 1 "YES";
VAL_ 1590 BMS_CellEquilnSts87 0 "NO" 1 "YES";
VAL_ 1590 BMS_CellEquilnSts86 0 "NO" 1 "YES";
VAL_ 1590 BMS_CellEquilnSts85 0 "NO" 1 "YES";
VAL_ 1590 BMS_CellEquilnSts84 0 "NO" 1 "YES";
VAL_ 1590 BMS_CellEquilnSts83 0 "NO" 1 "YES";
VAL_ 1590 BMS_CellEquilnSts82 0 "NO" 1 "YES";
VAL_ 1590 BMS_CellEquilnSts81 0 "NO" 1 "YES";
VAL_ 1590 BMS_CellEquilnSts80 0 "NO" 1 "YES";
VAL_ 1590 BMS_CellEquilnSts79 0 "NO" 1 "YES";
VAL_ 1590 BMS_CellEquilnSts78 0 "NO" 1 "YES";
VAL_ 1590 BMS_CellEquilnSts77 0 "NO" 1 "YES";
VAL_ 1590 BMS_CellEquilnSts76 0 "NO" 1 "YES";
VAL_ 1590 BMS_CellEquilnSts75 0 "NO" 1 "YES";
VAL_ 1590 BMS_CellEquilnSts74 0 "NO" 1 "YES";
VAL_ 1590 BMS_CellEquilnSts73 0 "NO" 1 "YES";
VAL_ 1590 BMS_CellEquilnSts72 0 "NO" 1 "YES";
VAL_ 1590 BMS_CellEquilnSts71 0 "NO" 1 "YES";
VAL_ 1590 BMS_CellEquilnSts70 0 "NO" 1 "YES";
VAL_ 1590 BMS_CellEquilnSts69 0 "NO" 1 "YES";
VAL_ 1590 BMS_CellEquilnSts68 0 "NO" 1 "YES";
VAL_ 1590 BMS_CellEquilnSts67 0 "NO" 1 "YES";
VAL_ 1590 BMS_CellEquilnSts66 0 "NO" 1 "YES";
VAL_ 1590 BMS_CellEquilnSts65 0 "NO" 1 "YES";
VAL_ 1590 BMS_CellEquilnSts9 0 "NO" 1 "YES";
VAL_ 1590 BMS_CellEquilnSts8 0 "NO" 1 "YES";
VAL_ 1590 BMS_CellEquilnSts7 0 "NO" 1 "YES";
VAL_ 1590 BMS_CellEquilnSts64 0 "NO" 1 "YES";
VAL_ 1590 BMS_CellEquilnSts63 0 "NO" 1 "YES";
VAL_ 1590 BMS_CellEquilnSts62 0 "NO" 1 "YES";
VAL_ 1590 BMS_CellEquilnSts61 0 "NO" 1 "YES";
VAL_ 1590 BMS_CellEquilnSts60 0 "NO" 1 "YES";
VAL_ 1590 BMS_CellEquilnSts6 0 "NO" 1 "YES";
VAL_ 1590 BMS_CellEquilnSts59 0 "NO" 1 "YES";
VAL_ 1590 BMS_CellEquilnSts58 0 "NO" 1 "YES";
VAL_ 1590 BMS_CellEquilnSts57 0 "NO" 1 "YES";
VAL_ 1590 BMS_CellEquilnSts56 0 "NO" 1 "YES";
VAL_ 1590 BMS_CellEquilnSts55 0 "NO" 1 "YES";
VAL_ 1590 BMS_CellEquilnSts54 0 "NO" 1 "YES";
VAL_ 1590 BMS_CellEquilnSts53 0 "NO" 1 "YES";
VAL_ 1590 BMS_CellEquilnSts52 0 "NO" 1 "YES";
VAL_ 1590 BMS_CellEquilnSts51 0 "NO" 1 "YES";
VAL_ 1590 BMS_CellEquilnSts50 0 "NO" 1 "YES";
VAL_ 1590 BMS_CellEquilnSts5 0 "NO" 1 "YES";
VAL_ 1590 BMS_CellEquilnSts49 0 "NO" 1 "YES";
VAL_ 1590 BMS_CellEquilnSts48 0 "NO" 1 "YES";
VAL_ 1590 BMS_CellEquilnSts47 0 "NO" 1 "YES";
VAL_ 1590 BMS_CellEquilnSts46 0 "NO" 1 "YES";
VAL_ 1590 BMS_CellEquilnSts45 0 "NO" 1 "YES";
VAL_ 1590 BMS_CellEquilnSts44 0 "NO" 1 "YES";
VAL_ 1590 BMS_CellEquilnSts43 0 "NO" 1 "YES";
VAL_ 1590 BMS_CellEquilnSts42 0 "NO" 1 "YES";
VAL_ 1590 BMS_CellEquilnSts41 0 "NO" 1 "YES";
VAL_ 1590 BMS_CellEquilnSts40 0 "NO" 1 "YES";
VAL_ 1590 BMS_CellEquilnSts4 0 "NO" 1 "YES";
VAL_ 1590 BMS_CellEquilnSts39 0 "NO" 1 "YES";
VAL_ 1590 BMS_CellEquilnSts38 0 "NO" 1 "YES";
VAL_ 1590 BMS_CellEquilnSts37 0 "NO" 1 "YES";
VAL_ 1590 BMS_CellEquilnSts36 0 "NO" 1 "YES";
VAL_ 1590 BMS_CellEquilnSts35 0 "NO" 1 "YES";
VAL_ 1590 BMS_CellEquilnSts34 0 "NO" 1 "YES";
VAL_ 1590 BMS_CellEquilnSts33 0 "NO" 1 "YES";
VAL_ 1590 BMS_CellEquilnSts32 0 "NO" 1 "YES";
VAL_ 1590 BMS_CellEquilnSts31 0 "NO" 1 "YES";
VAL_ 1590 BMS_CellEquilnSts30 0 "NO" 1 "YES";
VAL_ 1590 BMS_CellEquilnSts3 0 "NO" 1 "YES";
VAL_ 1590 BMS_CellEquilnSts29 0 "NO" 1 "YES";
VAL_ 1590 BMS_CellEquilnSts28 0 "NO" 1 "YES";
VAL_ 1590 BMS_CellEquilnSts27 0 "NO" 1 "YES";
VAL_ 1590 BMS_CellEquilnSts26 0 "NO" 1 "YES";
VAL_ 1590 BMS_CellEquilnSts25 0 "NO" 1 "YES";
VAL_ 1590 BMS_CellEquilnSts24 0 "NO" 1 "YES";
VAL_ 1590 BMS_CellEquilnSts23 0 "NO" 1 "YES";
VAL_ 1590 BMS_CellEquilnSts22 0 "NO" 1 "YES";
VAL_ 1590 BMS_CellEquilnSts21 0 "NO" 1 "YES";
VAL_ 1590 BMS_CellEquilnSts20 0 "NO" 1 "YES";
VAL_ 1590 BMS_CellEquilnSts2 0 "NO" 1 "YES";
VAL_ 1590 BMS_CellEquilnSts19 0 "NO" 1 "YES";
VAL_ 1590 BMS_CellEquilnSts18 0 "NO" 1 "YES";
VAL_ 1590 BMS_CellEquilnSts17 0 "NO" 1 "YES";
VAL_ 1590 BMS_CellEquilnSts16 0 "NO" 1 "YES";
VAL_ 1590 BMS_CellEquilnSts15 0 "NO" 1 "YES";
VAL_ 1590 BMS_CellEquilnSts14 0 "NO" 1 "YES";
VAL_ 1590 BMS_CellEquilnSts13 0 "NO" 1 "YES";
VAL_ 1590 BMS_CellEquilnSts12 0 "NO" 1 "YES";
VAL_ 1590 BMS_CellEquilnSts11 0 "NO" 1 "YES";
VAL_ 1590 BMS_CellEquilnSts10 0 "NO" 1 "YES";
VAL_ 1590 BMS_CellEquilnSts1 0 "NO" 1 "YES";
